VERSION "HNNBNNNYNNNNNNNNNNNNNNNNNNNNNNNNNNNNNNNNNN/4/%%%/4/'%**4NNN///"

NS_ :

BS_ :

BU_:  Airbag BAP_Tester ICAS1_Gateway ICAS1_KommunikationsServer LE1 LE2 Motor_BEV Schaltbetaetigung

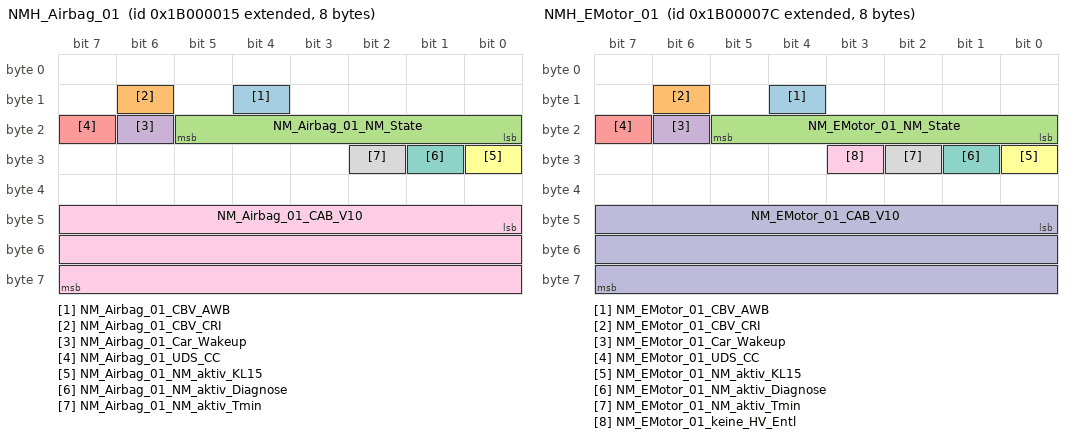
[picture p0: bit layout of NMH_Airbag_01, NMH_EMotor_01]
BO_ 2600468501 NMH_Airbag_01: 8 Airbag
 SG_ NM_Airbag_01_CBV_AWB  : 12|1@1+ (1.000000,0.000000) [0.000000|1.000000] "" ICAS1_Gateway
 SG_ NM_Airbag_01_CBV_CRI  : 14|1@1+ (1.000000,0.000000) [0.000000|1.000000] "" ICAS1_Gateway
 SG_ NM_Airbag_01_NM_State  : 16|6@1+ (1.000000,0.000000) [0.000000|63.000000] "" LE1 LE2 Motor_BEV Schaltbetaetigung
 SG_ NM_Airbag_01_Car_Wakeup  : 22|1@1+ (1.000000,0.000000) [0.000000|1.000000] "" ICAS1_Gateway
 SG_ NM_Airbag_01_UDS_CC  : 23|1@1+ (1.000000,0.000000) [0.000000|1.000000] "" Vector__XXX
 SG_ NM_Airbag_01_NM_aktiv_KL15  : 24|1@1+ (1.000000,0.000000) [0.000000|1.000000] "" Vector__XXX
 SG_ NM_Airbag_01_NM_aktiv_Diagnose  : 25|1@1+ (1.000000,0.000000) [0.000000|1.000000] "" Vector__XXX
 SG_ NM_Airbag_01_NM_aktiv_Tmin  : 26|1@1+ (1.000000,0.000000) [0.000000|1.000000] "" Vector__XXX
 SG_ NM_Airbag_01_CAB_V10  : 40|24@1+ (1.000000,0.000000) [0.000000|16777215.000000] "" ICAS1_Gateway

BO_ 2600468604 NMH_EMotor_01: 8 LE1
 SG_ NM_EMotor_01_CBV_AWB  : 12|1@1+ (1.000000,0.000000) [0.000000|1.000000] "" ICAS1_Gateway
 SG_ NM_EMotor_01_CBV_CRI  : 14|1@1+ (1.000000,0.000000) [0.000000|1.000000] "" ICAS1_Gateway
 SG_ NM_EMotor_01_NM_State  : 16|6@1+ (1.000000,0.000000) [0.000000|63.000000] "" Airbag LE2 Motor_BEV Schaltbetaetigung
 SG_ NM_EMotor_01_Car_Wakeup  : 22|1@1+ (1.000000,0.000000) [0.000000|1.000000] "" ICAS1_Gateway
 SG_ NM_EMotor_01_UDS_CC  : 23|1@1+ (1.000000,0.000000) [0.000000|1.000000] "" Vector__XXX
 SG_ NM_EMotor_01_NM_aktiv_KL15  : 24|1@1+ (1.000000,0.000000) [0.000000|1.000000] "" Vector__XXX
 SG_ NM_EMotor_01_NM_aktiv_Diagnose  : 25|1@1+ (1.000000,0.000000) [0.000000|1.000000] "" Vector__XXX
 SG_ NM_EMotor_01_NM_aktiv_Tmin  : 26|1@1+ (1.000000,0.000000) [0.000000|1.000000] "" Vector__XXX
 SG_ NM_EMotor_01_keine_HV_Entl  : 27|1@1+ (1.000000,0.000000) [0.000000|1.000000] "" Vector__XXX
 SG_ NM_EMotor_01_CAB_V10  : 40|24@1+ (1.000000,0.000000) [0.000000|16777215.000000] "" ICAS1_Gateway

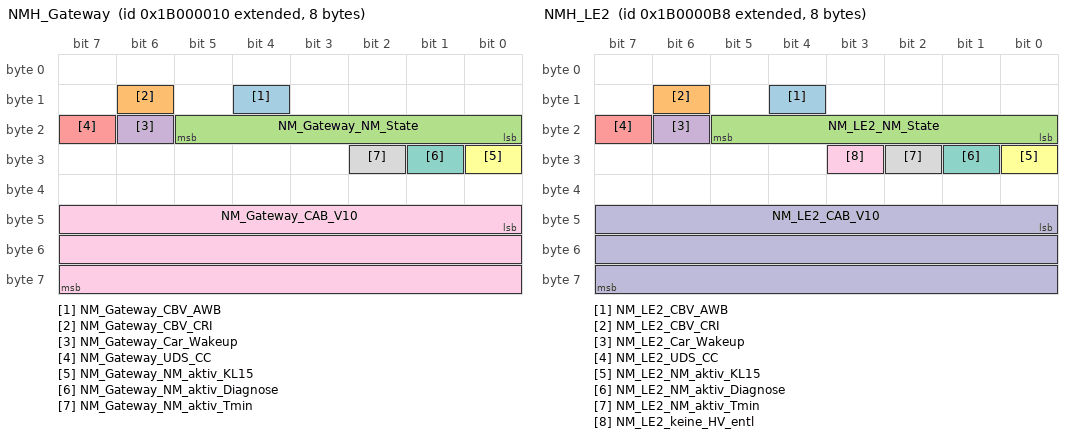
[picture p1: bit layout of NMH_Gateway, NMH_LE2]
BO_ 2600468496 NMH_Gateway: 8 ICAS1_Gateway
 SG_ NM_Gateway_CBV_AWB  : 12|1@1+ (1.000000,0.000000) [0.000000|1.000000] "" Vector__XXX
 SG_ NM_Gateway_CBV_CRI  : 14|1@1+ (1.000000,0.000000) [0.000000|1.000000] "" Vector__XXX
 SG_ NM_Gateway_NM_State  : 16|6@1+ (1.000000,0.000000) [0.000000|63.000000] "" Airbag LE1 LE2 Motor_BEV Schaltbetaetigung
 SG_ NM_Gateway_Car_Wakeup  : 22|1@1+ (1.000000,0.000000) [0.000000|1.000000] "" Vector__XXX
 SG_ NM_Gateway_UDS_CC  : 23|1@1+ (1.000000,0.000000) [0.000000|1.000000] "" Vector__XXX
 SG_ NM_Gateway_NM_aktiv_KL15  : 24|1@1+ (1.000000,0.000000) [0.000000|1.000000] "" Vector__XXX
 SG_ NM_Gateway_NM_aktiv_Diagnose  : 25|1@1+ (1.000000,0.000000) [0.000000|1.000000] "" Vector__XXX
 SG_ NM_Gateway_NM_aktiv_Tmin  : 26|1@1+ (1.000000,0.000000) [0.000000|1.000000] "" Vector__XXX
 SG_ NM_Gateway_CAB_V10  : 40|24@1+ (1.000000,0.000000) [0.000000|16777215.000000] "" Vector__XXX

BO_ 2600468664 NMH_LE2: 8 LE2
 SG_ NM_LE2_CBV_AWB  : 12|1@1+ (1.000000,0.000000) [0.000000|1.000000] "" ICAS1_Gateway
 SG_ NM_LE2_CBV_CRI  : 14|1@1+ (1.000000,0.000000) [0.000000|1.000000] "" ICAS1_Gateway
 SG_ NM_LE2_NM_State  : 16|6@1+ (1.000000,0.000000) [0.000000|63.000000] "" Airbag LE1 Motor_BEV Schaltbetaetigung
 SG_ NM_LE2_Car_Wakeup  : 22|1@1+ (1.000000,0.000000) [0.000000|1.000000] "" ICAS1_Gateway
 SG_ NM_LE2_UDS_CC  : 23|1@1+ (1.000000,0.000000) [0.000000|1.000000] "" Vector__XXX
 SG_ NM_LE2_NM_aktiv_KL15  : 24|1@1+ (1.000000,0.000000) [0.000000|1.000000] "" Vector__XXX
 SG_ NM_LE2_NM_aktiv_Diagnose  : 25|1@1+ (1.000000,0.000000) [0.000000|1.000000] "" Vector__XXX
 SG_ NM_LE2_NM_aktiv_Tmin  : 26|1@1+ (1.000000,0.000000) [0.000000|1.000000] "" Vector__XXX
 SG_ NM_LE2_keine_HV_entl  : 27|1@1+ (1.000000,0.000000) [0.000000|1.000000] "" Vector__XXX
 SG_ NM_LE2_CAB_V10  : 40|24@1+ (1.000000,0.000000) [0.000000|16777215.000000] "" ICAS1_Gateway

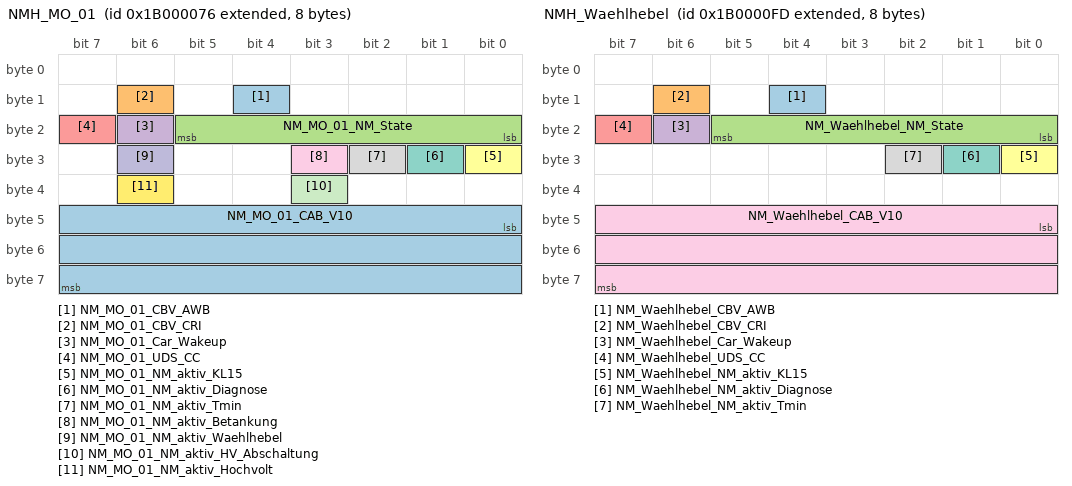
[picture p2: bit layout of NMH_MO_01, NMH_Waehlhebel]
BO_ 2600468598 NMH_MO_01: 8 Motor_BEV
 SG_ NM_MO_01_CBV_AWB  : 12|1@1+ (1.000000,0.000000) [0.000000|1.000000] "" ICAS1_Gateway
 SG_ NM_MO_01_CBV_CRI  : 14|1@1+ (1.000000,0.000000) [0.000000|1.000000] "" ICAS1_Gateway
 SG_ NM_MO_01_NM_State  : 16|6@1+ (1.000000,0.000000) [0.000000|63.000000] "" Airbag LE1 LE2 Schaltbetaetigung
 SG_ NM_MO_01_Car_Wakeup  : 22|1@1+ (1.000000,0.000000) [0.000000|1.000000] "" ICAS1_Gateway
 SG_ NM_MO_01_UDS_CC  : 23|1@1+ (1.000000,0.000000) [0.000000|1.000000] "" Vector__XXX
 SG_ NM_MO_01_NM_aktiv_KL15  : 24|1@1+ (1.000000,0.000000) [0.000000|1.000000] "" Vector__XXX
 SG_ NM_MO_01_NM_aktiv_Diagnose  : 25|1@1+ (1.000000,0.000000) [0.000000|1.000000] "" Vector__XXX
 SG_ NM_MO_01_NM_aktiv_Tmin  : 26|1@1+ (1.000000,0.000000) [0.000000|1.000000] "" Vector__XXX
 SG_ NM_MO_01_NM_aktiv_Betankung  : 27|1@1+ (1.000000,0.000000) [0.000000|1.000000] "" Vector__XXX
 SG_ NM_MO_01_NM_aktiv_Waehlhebel  : 30|1@1+ (1.000000,0.000000) [0.000000|1.000000] "" Vector__XXX
 SG_ NM_MO_01_NM_aktiv_HV_Abschaltung  : 35|1@1+ (1.000000,0.000000) [0.000000|1.000000] "" Vector__XXX
 SG_ NM_MO_01_NM_aktiv_Hochvolt  : 38|1@1+ (1.000000,0.000000) [0.000000|1.000000] "" Vector__XXX
 SG_ NM_MO_01_CAB_V10  : 40|24@1+ (1.000000,0.000000) [0.000000|16777215.000000] "" ICAS1_Gateway

BO_ 2600468733 NMH_Waehlhebel: 8 Schaltbetaetigung
 SG_ NM_Waehlhebel_CBV_AWB  : 12|1@1+ (1.000000,0.000000) [0.000000|1.000000] "" ICAS1_Gateway
 SG_ NM_Waehlhebel_CBV_CRI  : 14|1@1+ (1.000000,0.000000) [0.000000|1.000000] "" ICAS1_Gateway
 SG_ NM_Waehlhebel_NM_State  : 16|6@1+ (1.000000,0.000000) [0.000000|63.000000] "" Airbag LE1 LE2 Motor_BEV
 SG_ NM_Waehlhebel_Car_Wakeup  : 22|1@1+ (1.000000,0.000000) [0.000000|1.000000] "" ICAS1_Gateway
 SG_ NM_Waehlhebel_UDS_CC  : 23|1@1+ (1.000000,0.000000) [0.000000|1.000000] "" Vector__XXX
 SG_ NM_Waehlhebel_NM_aktiv_KL15  : 24|1@1+ (1.000000,0.000000) [0.000000|1.000000] "" Vector__XXX
 SG_ NM_Waehlhebel_NM_aktiv_Diagnose  : 25|1@1+ (1.000000,0.000000) [0.000000|1.000000] "" Vector__XXX
 SG_ NM_Waehlhebel_NM_aktiv_Tmin  : 26|1@1+ (1.000000,0.000000) [0.000000|1.000000] "" Vector__XXX
 SG_ NM_Waehlhebel_CAB_V10  : 40|24@1+ (1.000000,0.000000) [0.000000|16777215.000000] "" ICAS1_Gateway

BO_ 2621440533 OBDC_Airbag_01_Req_FD: 64 ICAS1_Gateway
 SG_ OBDC_Airbag_01_Req_FD_Data  : 0|512@1+ (1.000000,0.000000) [0.000000|13407807929942597099574024998205846127479365820592393377723561443721764030073546976801874298166903427690031858186486050853753882811946569946433649006084096.000000] "" Airbag

BO_ 2621571605 OBDC_Airbag_01_Resp_FD: 64 Airbag
 SG_ OBDC_Airbag_01_Resp_FD_Data  : 0|512@1+ (1.000000,0.000000) [0.000000|13407807929942597099574024998205846127479365820592393377723561443721764030073546976801874298166903427690031858186486050853753882811946569946433649006084096.000000] "" ICAS1_Gateway

BO_ 2621440636 OBDC_EMotor_01_Req_FD: 64 ICAS1_Gateway
 SG_ OBDC_EMotor_01_Req_FD_Data  : 0|512@1+ (1.000000,0.000000) [0.000000|13407807929942597099574024998205846127479365820592393377723561443721764030073546976801874298166903427690031858186486050853753882811946569946433649006084096.000000] "" LE1

BO_ 2621571708 OBDC_EMotor_01_Resp_FD: 64 LE1
 SG_ OBDC_EMotor_01_Resp_FD_Data  : 0|512@1+ (1.000000,0.000000) [0.000000|13407807929942597099574024998205846127479365820592393377723561443721764030073546976801874298166903427690031858186486050853753882811946569946433649006084096.000000] "" ICAS1_Gateway

BO_ 2621440696 OBDC_EMotor_02_Req_FD: 64 ICAS1_Gateway
 SG_ OBDC_EMotor_02_Req_FD_Data  : 0|512@1+ (1.000000,0.000000) [0.000000|13407807929942597099574024998205846127479365820592393377723561443721764030073546976801874298166903427690031858186486050853753882811946569946433649006084096.000000] "" LE2

BO_ 2621571768 OBDC_EMotor_02_Resp_FD: 64 LE2
 SG_ OBDC_EMotor_02_Resp_FD_Data  : 0|512@1+ (1.000000,0.000000) [0.000000|13407807929942597099574024998205846127479365820592393377723561443721764030073546976801874298166903427690031858186486050853753882811946569946433649006084096.000000] "" ICAS1_Gateway

BO_ 2621506048 OBDC_Funktionaler_Req_All_FD: 64 ICAS1_Gateway
 SG_ OBDC_Funktion_Req_All_FD_Data  : 0|512@1+ (1.000000,0.000000) [0.000000|13407807929942597099574024998205846127479365820592393377723561443721764030073546976801874298166903427690031858186486050853753882811946569946433649006084096.000000] "" Airbag LE1 LE2 Motor_BEV

BO_ 2621440630 OBDC_MO_01_Req_FD: 64 ICAS1_Gateway
 SG_ OBDC_MO_01_Req_FD_Data  : 0|512@1+ (1.000000,0.000000) [0.000000|13407807929942597099574024998205846127479365820592393377723561443721764030073546976801874298166903427690031858186486050853753882811946569946433649006084096.000000] "" Motor_BEV

BO_ 2621571702 OBDC_MO_01_Resp_FD: 64 Motor_BEV
 SG_ OBDC_MO_01_Resp_FD_Data  : 0|512@1+ (1.000000,0.000000) [0.000000|13407807929942597099574024998205846127479365820592393377723561443721764030073546976801874298166903427690031858186486050853753882811946569946433649006084096.000000] "" ICAS1_Gateway

BO_ 2564502513 OBDx_allOBD_Req: 8 ICAS1_Gateway
 SG_ OBDx_allOBD_Req_Data  : 0|64@1+ (1.000000,0.000000) [0.000000|18446744073709551616.000000] "" LE1 LE2 Motor_BEV

BO_ 2564425457 OBDx_LE1_Req: 8 ICAS1_Gateway
 SG_ OBDx_LE1_Req_Data  : 0|64@1+ (1.000000,0.000000) [0.000000|18446744073709551616.000000] "" LE1

BO_ 2564485382 OBDx_LE1_Resp: 8 LE1
 SG_ OBDx_LE1_Resp_Data  : 0|64@1+ (1.000000,0.000000) [0.000000|18446744073709551616.000000] "" ICAS1_Gateway

BO_ 2564425713 OBDx_LE2_Req: 8 ICAS1_Gateway
 SG_ OBDx_LE2_Req_Data  : 0|64@1+ (1.000000,0.000000) [0.000000|18446744073709551616.000000] "" LE2

BO_ 2564485383 OBDx_LE2_Resp: 8 LE2
 SG_ OBDx_LE2_Resp_Data  : 0|64@1+ (1.000000,0.000000) [0.000000|18446744073709551616.000000] "" ICAS1_Gateway

BO_ 2564424177 OBDx_MO_01_Req: 8 ICAS1_Gateway
 SG_ OBDx_MO_01_Req_Data  : 0|64@1+ (1.000000,0.000000) [0.000000|18446744073709551616.000000] "" Motor_BEV

BO_ 2564485377 OBDx_MO_01_Resp: 8 Motor_BEV
 SG_ OBDx_MO_01_Resp_Data  : 0|64@1+ (1.000000,0.000000) [0.000000|18446744073709551616.000000] "" ICAS1_Gateway

BO_ 627 OCC_01: 24 ICAS1_Gateway
 SG_ OCC_01_CRC  : 0|8@1+ (1.000000,0.000000) [0.000000|255.000000] "" Vector__XXX
 SG_ OCC_01_BZ  : 8|4@1+ (1.000000,0.000000) [0.000000|15.000000] "" Vector__XXX
 SG_ OCC_Stecker_Status  : 12|2@1+ (1.000000,0.000000) [0.000000|3.000000] "" Vector__XXX
 SG_ OCC_Status_Spgfreiheit  : 14|2@1+ (1.000000,0.000000) [0.000000|3.000000] "" Motor_BEV
 SG_ OCC_DC_IstStrom  : 16|11@1+ (0.100000,0.000000) [0.000000|204.500000] "Unit_Amper" Vector__XXX
 SG_ OCC_CC_Latchstatus_DC_GBT  : 27|3@1+ (1.000000,0.000000) [0.000000|7.000000] "" Vector__XXX
 SG_ OCC_Status_EoHVL  : 30|2@1+ (1.000000,0.000000) [0.000000|3.000000] "" Motor_BEV
 SG_ OCC_I_istAC_Netz_L1  : 32|9@1+ (0.100000,0.000000) [0.000000|50.800000] "Unit_Amper" Vector__XXX
 SG_ OCC_PP_Latchstatus_A  : 41|3@1+ (1.000000,0.000000) [0.000000|7.000000] "" Vector__XXX
 SG_ OCC_PP_Latchstatus_B  : 44|3@1+ (1.000000,0.000000) [0.000000|7.000000] "" Vector__XXX
 SG_ OCC_I_istAC_Netz_L2  : 47|9@1+ (0.100000,0.000000) [0.000000|50.800000] "Unit_Amper" Vector__XXX
 SG_ OCC_I_istAC_Netz_L3  : 56|9@1+ (0.100000,0.000000) [0.000000|50.800000] "Unit_Amper" Vector__XXX
 SG_ OCC_IstModus  : 65|3@1+ (1.000000,0.000000) [0.000000|7.000000] "" Motor_BEV
 SG_ OCC_CP_Status_A  : 68|2@1+ (1.000000,0.000000) [0.000000|3.000000] "" Vector__XXX
 SG_ OCC_CP_Status_B  : 70|2@1+ (1.000000,0.000000) [0.000000|3.000000] "" Vector__XXX
 SG_ OCC_IstSpannung_HV  : 72|10@1+ (1.000000,0.000000) [0.000000|1021.000000] "Unit_Volt" Vector__XXX
 SG_ OCC_PP_Status_A  : 82|2@1+ (1.000000,0.000000) [0.000000|3.000000] "" Vector__XXX
 SG_ OCC_PP_Status_B  : 84|2@1+ (1.000000,0.000000) [0.000000|3.000000] "" Vector__XXX
 SG_ OCC_CC_Status_DC_GBT  : 86|2@1+ (1.000000,0.000000) [0.000000|3.000000] "" Vector__XXX
 SG_ OCC_CC_Fehlerstatus_DC_GBT  : 88|4@1+ (1.000000,0.000000) [0.000000|15.000000] "" Vector__XXX
 SG_ OCC_Temp_Sensor_Fehlerstatus_DC  : 92|4@1+ (1.000000,0.000000) [0.000000|15.000000] "" Vector__XXX
 SG_ OCC_Temp_Sensor_Fehlerstatus_AC  : 96|3@1+ (1.000000,0.000000) [0.000000|7.000000] "" Vector__XXX
 SG_ OCC_Temp_Sensor_Status  : 99|3@1+ (1.000000,0.000000) [0.000000|7.000000] "" Vector__XXX

BO_ 2463978709 OCC_02: 32 ICAS1_Gateway
 SG_ OCC_CP_Tastgrad_A  : 12|10@1+ (0.100000,0.000000) [0.000000|100.000000] "Unit_PerCent" Vector__XXX
 SG_ OCC_CP_Tastgrad_B  : 22|10@1+ (0.100000,0.000000) [0.000000|100.000000] "Unit_PerCent" Vector__XXX
 SG_ OCC_CP_Frequenz_A  : 32|8@1+ (1.000000,880.000000) [880.000000|1132.000000] "Unit_Hertz" Vector__XXX
 SG_ OCC_CP_Frequenz_B  : 40|8@1+ (1.000000,880.000000) [880.000000|1132.000000] "Unit_Hertz" Vector__XXX
 SG_ OCC_CP_Spannung_A  : 48|9@1+ (0.100000,-25.000000) [-25.000000|25.900000] "Unit_Volt" Vector__XXX
 SG_ OCC_CP_Spannung_B  : 57|9@1+ (0.100000,-25.000000) [-25.000000|25.900000] "Unit_Volt" Vector__XXX
 SG_ OCC_CP_Fehlerstatus_A  : 66|3@1+ (1.000000,0.000000) [0.000000|7.000000] "" Vector__XXX
 SG_ OCC_CP_Fehlerstatus_B  : 69|3@1+ (1.000000,0.000000) [0.000000|7.000000] "" Vector__XXX
 SG_ OCC_Temp_Ladedose_A_AC  : 72|8@1+ (1.000000,-40.000000) [-40.000000|213.000000] "Unit_DegreCelsi" Vector__XXX
 SG_ OCC_Temp_Ladedose_A_DC_minus  : 80|8@1+ (1.000000,-40.000000) [-40.000000|213.000000] "Unit_DegreCelsi" Vector__XXX
 SG_ OCC_Temp_Ladedose_A_DC_plus  : 88|8@1+ (1.000000,-40.000000) [-40.000000|213.000000] "Unit_DegreCelsi" Vector__XXX
 SG_ OCC_U_istAC_Netz_L1  : 96|9@1+ (1.000000,0.000000) [0.000000|509.000000] "Unit_Volt" Vector__XXX
 SG_ OCC_U_istAC_Netz_L2  : 105|9@1+ (1.000000,0.000000) [0.000000|509.000000] "Unit_Volt" Vector__XXX
 SG_ OCC_U_istAC_Netz_L3  : 114|9@1+ (1.000000,0.000000) [0.000000|508.000000] "Unit_Volt" Vector__XXX
 SG_ OCC_StatusVerEntriegelungAktor_A  : 123|3@1+ (1.000000,0.000000) [0.000000|7.000000] "" Vector__XXX
 SG_ OCC_SteckerEntriegelung_Verbot_A  : 126|2@1+ (1.000000,0.000000) [0.000000|3.000000] "" Vector__XXX
 SG_ OCC_StatusVerEntriegelungAktor_B  : 128|3@1+ (1.000000,0.000000) [0.000000|7.000000] "" Vector__XXX
 SG_ OCC_SteckerEntriegelung_Verbot_B  : 131|2@1+ (1.000000,0.000000) [0.000000|3.000000] "" Vector__XXX
 SG_ OCC_Verriegelung_Status_A  : 133|3@1+ (1.000000,0.000000) [0.000000|7.000000] "" Vector__XXX
 SG_ OCC_Verriegelung_Status_B  : 136|3@1+ (1.000000,0.000000) [0.000000|7.000000] "" Vector__XXX
 SG_ OCC_RtmWarnLadeKommunikation  : 139|3@1+ (1.000000,0.000000) [0.000000|7.000000] "" Vector__XXX
 SG_ OCC_Ist_Wirkungsgrad  : 145|7@1+ (1.000000,0.000000) [0.000000|100.000000] "Unit_PerCent" Vector__XXX
 SG_ OCC_PP_Max_Strom_A  : 152|4@1+ (1.000000,0.000000) [0.000000|15.000000] "" Vector__XXX
 SG_ OCC_PP_Max_Strom_B  : 156|4@1+ (1.000000,0.000000) [0.000000|15.000000] "" Vector__XXX
 SG_ OCC_DC_MaxStrom  : 160|11@1+ (0.100000,0.000000) [0.000000|204.500000] "Unit_Amper" Vector__XXX
 SG_ OCC_Derating_Temperatur  : 171|1@1+ (1.000000,0.000000) [0.000000|1.000000] "" Vector__XXX
 SG_ OCC_Fehlerzustand  : 172|1@1+ (1.000000,0.000000) [0.000000|1.000000] "" Vector__XXX
 SG_ OCC_Ladest_Entriegelungs_Verbot  : 173|3@1+ (1.000000,0.000000) [0.000000|7.000000] "" Vector__XXX
 SG_ OCC_Netzfrequenz_EVU  : 176|9@1+ (0.100000,40.000000) [40.000000|80.000000] "Unit_Hertz" Vector__XXX
 SG_ OCC_Warnzustand  : 185|1@1+ (1.000000,0.000000) [0.000000|1.000000] "" Vector__XXX
 SG_ OCC_Kuehltemperatur  : 192|8@1+ (1.000000,-40.000000) [-40.000000|213.000000] "Unit_DegreCelsi" Motor_BEV
 SG_ OCC_PP_Fehlerstatus_A  : 200|4@1+ (1.000000,0.000000) [0.000000|15.000000] "" Vector__XXX
 SG_ OCC_PP_Fehlerstatus_B  : 204|4@1+ (1.000000,0.000000) [0.000000|15.000000] "" Vector__XXX

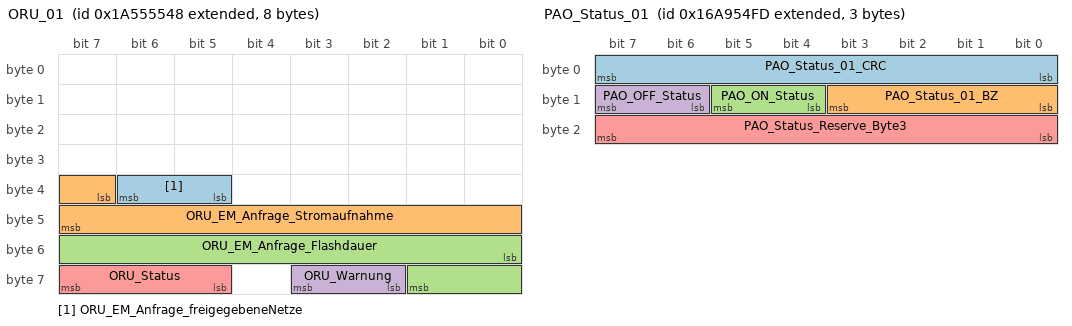
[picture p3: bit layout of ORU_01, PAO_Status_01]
BO_ 2589283656 ORU_01: 8 ICAS1_Gateway
 SG_ ORU_EM_Anfrage_freigegebeneNetze  : 37|2@1+ (1.000000,0.000000) [0.000000|3.000000] "" Vector__XXX
 SG_ ORU_EM_Anfrage_Stromaufnahme  : 39|9@1+ (0.100000,0.000000) [0.000000|51.100000] "Unit_Amper" Vector__XXX
 SG_ ORU_EM_Anfrage_Flashdauer  : 48|10@1+ (10.000000,0.000000) [0.000000|10230.000000] "Unit_Secon" Vector__XXX
 SG_ ORU_Warnung  : 58|2@1+ (1.000000,0.000000) [0.000000|3.000000] "" Vector__XXX
 SG_ ORU_Status  : 61|3@1+ (1.000000,0.000000) [0.000000|7.000000] "" Airbag LE1 LE2 Motor_BEV

BO_ 2527679741 PAO_Status_01: 3 ICAS1_Gateway
 SG_ PAO_Status_01_CRC  : 0|8@1+ (1.000000,0.000000) [0.000000|255.000000] "" Airbag
 SG_ PAO_Status_01_BZ  : 8|4@1+ (1.000000,0.000000) [0.000000|15.000000] "" Airbag
 SG_ PAO_ON_Status  : 12|2@1+ (1.000000,0.000000) [0.000000|3.000000] "" Airbag
 SG_ PAO_OFF_Status  : 14|2@1+ (1.000000,0.000000) [0.000000|3.000000] "" Airbag
 SG_ PAO_Status_Reserve_Byte3  : 16|8@1+ (1.000000,0.000000) [0.000000|255.000000] "" Vector__XXX

BO_ 518 Parken_01: 24 ICAS1_Gateway
 SG_ Parken_BKD_Anf  : 12|4@1+ (0.100000,0.000000) [0.000000|1.300000] "Unit_Secon" Vector__XXX
 SG_ Parken_Verz_Anf  : 16|7@1+ (0.100000,-12.600000) [-12.600000|-0.100000] "Unit_MeterPerSeconSquar" Vector__XXX
 SG_ Parken_Prefill_Anf  : 23|1@1+ (1.000000,0.000000) [0.000000|1.000000] "" Vector__XXX
 SG_ Parken_Warnruck_Anf  : 24|2@1+ (1.000000,0.000000) [0.000000|3.000000] "" Vector__XXX
 SG_ Parken_Verz_Anf_ASIL  : 26|2@1+ (1.000000,0.000000) [0.000000|3.000000] "" Vector__XXX
 SG_ Parken_Warnruckeln_Anf  : 28|2@1+ (1.000000,0.000000) [0.000000|3.000000] "" Vector__XXX
 SG_ Parken_beibehalten  : 30|2@1+ (1.000000,0.000000) [0.000000|3.000000] "" Vector__XXX
 SG_ Parken_Anforderung_HMS  : 32|3@1+ (1.000000,0.000000) [0.000000|7.000000] "" Vector__XXX
 SG_ Parken_Notstopp_Anf  : 40|2@1+ (1.000000,0.000000) [0.000000|3.000000] "" Vector__XXX
 SG_ Parken_Anhalteweg_Anf  : 42|10@1+ (0.010000,0.000000) [0.000000|10.210000] "Unit_Meter" Vector__XXX
 SG_ Parken_aktives_System  : 52|4@1+ (1.000000,0.000000) [0.000000|15.000000] "" Motor_BEV
 SG_ Parken_max_Beschleunigung  : 56|7@1+ (0.100000,-6.000000) [-5.900000|6.100000] "Unit_MeterPerSeconSquar" Motor_BEV
 SG_ Parken_Blinker_li_Anf  : 63|1@1+ (1.000000,0.000000) [0.000000|1.000000] "" Vector__XXX
 SG_ Parken_QFK_KruemmSoll  : 64|15@1+ (0.000007,0.000000) [0.000000|0.219539] "Unit_MeterInver" Vector__XXX
 SG_ Parken_QFK_KruemmSoll_VZ  : 79|1@1+ (1.000000,0.000000) [0.000000|1.000000] "" Vector__XXX
 SG_ Parken_QFK_Spuerb  : 80|8@1+ (0.400000,0.000000) [0.000000|100.000000] "Unit_PerCent" Vector__XXX
 SG_ Parken_QFK_AnfStat  : 88|4@1+ (1.000000,0.000000) [0.000000|15.000000] "" Vector__XXX
 SG_ Parken_QFK_Signal1  : 92|10@1+ (1.000000,0.000000) [0.000000|1023.000000] "" Vector__XXX
 SG_ Parken_QFK_Art1  : 102|3@1+ (1.000000,0.000000) [0.000000|7.000000] "" Vector__XXX
 SG_ Parken_QFK_Art2  : 105|3@1+ (1.000000,0.000000) [0.000000|7.000000] "" Vector__XXX
 SG_ Parken_QFK_Signal2  : 108|10@1+ (1.000000,0.000000) [0.000000|1023.000000] "" Vector__XXX
 SG_ Parken_Sollbeschleunigung  : 118|9@1+ (0.010000,-4.110000) [-4.100000|1.000000] "Unit_MeterPerSeconSquar" Motor_BEV
 SG_ Parken_Blinker_re_Anf  : 127|1@1+ (1.000000,0.000000) [0.000000|1.000000] "" Vector__XXX
 SG_ Parken_Status_IPA_TSK  : 128|4@1+ (1.000000,0.000000) [0.000000|15.000000] "" Motor_BEV
 SG_ Parken_erhoehtes_Moment  : 132|4@1+ (1.000000,0.000000) [0.000000|15.000000] "" Motor_BEV
 SG_ Parken_max_Geschwindigkeit  : 136|8@1+ (0.100000,0.000000) [0.100000|25.000000] "Unit_KiloMeterPerHour" Motor_BEV
 SG_ Parken_Soll_Anhalteweg_Anf  : 144|10@1+ (0.010000,0.000000) [0.000000|10.210000] "Unit_Meter" Vector__XXX
 SG_ Parken_Fahrstufenwunsch  : 154|3@1+ (1.000000,0.000000) [0.000000|7.000000] "" Motor_BEV
 SG_ IPA_TPA_Remote  : 157|2@1+ (1.000000,0.000000) [0.000000|3.000000] "" Vector__XXX
 SG_ IPA_TPA_Remote_Anf  : 159|1@1+ (1.000000,0.000000) [0.000000|1.000000] "" Vector__XXX
 SG_ IPA_TPA_Fehler  : 160|4@1+ (1.000000,0.000000) [0.000000|15.000000] "" Vector__XXX
 SG_ IPA_TPA_Abbruch  : 164|4@1+ (1.000000,0.000000) [0.000000|15.000000] "" Vector__XXX
 SG_ IPA_TPA_Status  : 168|4@1+ (1.000000,0.000000) [0.000000|15.000000] "" Vector__XXX

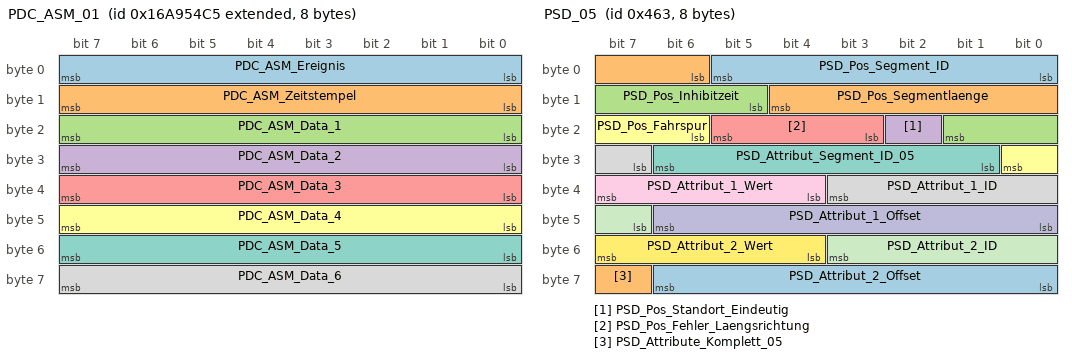
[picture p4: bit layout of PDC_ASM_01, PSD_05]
BO_ 2527679685 PDC_ASM_01: 8 ICAS1_Gateway
 SG_ PDC_ASM_Ereignis  : 0|8@1+ (1.000000,0.000000) [1.000000|254.000000] "" Airbag
 SG_ PDC_ASM_Zeitstempel  : 8|8@1+ (0.080000,0.000000) [0.000000|20.320000] "Unit_Secon" Airbag
 SG_ PDC_ASM_Data_1  : 16|8@1+ (1.000000,0.000000) [0.000000|255.000000] "" Airbag
 SG_ PDC_ASM_Data_2  : 24|8@1+ (1.000000,0.000000) [0.000000|255.000000] "" Airbag
 SG_ PDC_ASM_Data_3  : 32|8@1+ (1.000000,0.000000) [0.000000|255.000000] "" Airbag
 SG_ PDC_ASM_Data_4  : 40|8@1+ (1.000000,0.000000) [0.000000|255.000000] "" Airbag
 SG_ PDC_ASM_Data_5  : 48|8@1+ (1.000000,0.000000) [0.000000|255.000000] "" Airbag
 SG_ PDC_ASM_Data_6  : 56|8@1+ (1.000000,0.000000) [0.000000|255.000000] "" Airbag

BO_ 319 PreCrash_02: 8 Airbag
 SG_ PreCrash_Charisma_FahrPr  : 12|4@1+ (1.000000,0.000000) [0.000000|15.000000] "" ICAS1_Gateway
 SG_ PreCrash_Charisma_Status  : 16|2@1+ (1.000000,0.000000) [0.000000|3.000000] "" ICAS1_Gateway
 SG_ PreCrash_Schiebedach_schliessen  : 18|1@1+ (1.000000,0.000000) [0.000000|1.000000] "" ICAS1_Gateway
 SG_ PreCrash_Fenster_schliessen  : 19|1@1+ (1.000000,0.000000) [0.000000|1.000000] "" ICAS1_Gateway
 SG_ PreCrash_Blinken  : 20|3@1+ (1.000000,0.000000) [0.000000|7.000000] "" ICAS1_Gateway
 SG_ SC_PreSense_FCWP  : 23|1@1+ (1.000000,0.000000) [0.000000|1.000000] "" ICAS1_Gateway
 SG_ PreCrash_Tueren_Verriegeln  : 24|1@1+ (1.000000,0.000000) [0.000000|1.000000] "" ICAS1_Gateway
 SG_ PreCrash_FS_Laengsverstellung  : 25|1@1+ (1.000000,0.000000) [0.000000|1.000000] "" ICAS1_Gateway
 SG_ PreCrash_Anforderung_AFR  : 26|3@1+ (1.000000,0.000000) [0.000000|7.000000] "" ICAS1_Gateway
 SG_ SC_PreCrash_LED  : 29|2@1+ (1.000000,0.000000) [0.000000|3.000000] "" ICAS1_Gateway
 SG_ PreCrash_FS_Pneumatik_ansteuern  : 31|1@1+ (1.000000,0.000000) [0.000000|1.000000] "" ICAS1_Gateway
 SG_ PreCrash_BFS_Pneumatik_ansteuern  : 32|1@1+ (1.000000,0.000000) [0.000000|1.000000] "" ICAS1_Gateway
 SG_ PreCrash_Fo_Pneumatik_ansteuern  : 33|1@1+ (1.000000,0.000000) [0.000000|1.000000] "" ICAS1_Gateway
 SG_ PreCrash_FS_Sitzlehne_verfahren  : 34|3@1+ (1.000000,0.000000) [0.000000|7.000000] "" ICAS1_Gateway
 SG_ PreCrash_BFS_Sitzlehne_verfahren  : 37|3@1+ (1.000000,0.000000) [0.000000|7.000000] "" ICAS1_Gateway
 SG_ PreCrash_Fo_Sitzlehne_verfahren  : 40|3@1+ (1.000000,0.000000) [0.000000|7.000000] "" ICAS1_Gateway
 SG_ PreCrash_FS_KSV_verfahren  : 43|4@1+ (1.000000,0.000000) [0.000000|15.000000] "" ICAS1_Gateway
 SG_ PreCrash_BFS_KSV_verfahren  : 47|4@1+ (1.000000,0.000000) [0.000000|15.000000] "" ICAS1_Gateway
 SG_ PreCrash_Fo_KSV_verfahren  : 51|4@1+ (1.000000,0.000000) [0.000000|15.000000] "" ICAS1_Gateway
 SG_ PreCrash_BFS_Laengsverstellung  : 55|1@1+ (1.000000,0.000000) [0.000000|1.000000] "" ICAS1_Gateway
 SG_ SC_PreCrash_Warnung  : 56|4@1+ (1.000000,0.000000) [0.000000|15.000000] "" ICAS1_Gateway ICAS1_KommunikationsServer
 SG_ SC_PreCrash_Texte  : 60|4@1+ (1.000000,0.000000) [0.000000|15.000000] "" ICAS1_Gateway ICAS1_KommunikationsServer

BO_ 1122 PSD_04: 8 ICAS1_Gateway
 SG_ PSD_Segment_ID  : 0|6@1+ (1.000000,0.000000) [2.000000|63.000000] "" Motor_BEV
 SG_ PSD_Vorgaenger_Segment_ID  : 6|6@1+ (1.000000,0.000000) [2.000000|63.000000] "" Motor_BEV
 SG_ PSD_Segmentlaenge  : 12|7@1+ (2.000000,0.000000) [0.000000|254.000000] "Unit_Meter" Motor_BEV
 SG_ PSD_Strassenkategorie  : 19|3@1+ (1.000000,0.000000) [0.000000|7.000000] "" Motor_BEV
 SG_ PSD_Endkruemmung  : 22|8@1+ (1.000000,0.000000) [0.000000|254.000000] "Unit_None" Motor_BEV
 SG_ PSD_Endkruemmung_Vorz  : 30|1@1+ (1.000000,0.000000) [0.000000|1.000000] "" Motor_BEV
 SG_ PSD_Idenditaets_ID  : 31|6@1+ (1.000000,0.000000) [2.000000|63.000000] "" Vector__XXX
 SG_ PSD_ADAS_Qualitaet  : 37|1@1+ (1.000000,0.000000) [0.000000|1.000000] "" Motor_BEV
 SG_ PSD_wahrscheinlichster_Pfad  : 38|1@1+ (1.000000,0.000000) [0.000000|1.000000] "" Motor_BEV
 SG_ PSD_Geradester_Pfad  : 39|1@1+ (1.000000,0.000000) [0.000000|1.000000] "" Motor_BEV
 SG_ PSD_Fahrspuren_Anzahl  : 40|3@1+ (1.000000,0.000000) [0.000000|7.000000] "" Motor_BEV
 SG_ PSD_Bebauung  : 43|1@1+ (1.000000,0.000000) [0.000000|1.000000] "" Motor_BEV
 SG_ PSD_Segment_Komplett  : 44|1@1+ (1.000000,0.000000) [0.000000|1.000000] "" Motor_BEV
 SG_ PSD_Rampe  : 45|2@1+ (1.000000,0.000000) [0.000000|3.000000] "" Motor_BEV
 SG_ PSD_Anfangskruemmung  : 47|8@1+ (1.000000,0.000000) [0.000000|254.000000] "" Motor_BEV
 SG_ PSD_Anfangskruemmung_Vorz  : 55|1@1+ (1.000000,0.000000) [0.000000|1.000000] "" Motor_BEV
 SG_ PSD_Abzweigerichtung  : 56|1@1+ (1.000000,0.000000) [0.000000|1.000000] "" Motor_BEV
 SG_ PSD_Abzweigewinkel  : 57|7@1+ (1.417323,0.000000) [0.000000|180.000021] "" Motor_BEV

BO_ 1123 PSD_05: 8 ICAS1_Gateway
 SG_ PSD_Pos_Segment_ID  : 0|6@1+ (1.000000,0.000000) [2.000000|63.000000] "" Motor_BEV
 SG_ PSD_Pos_Segmentlaenge  : 6|7@1+ (2.000000,0.000000) [0.000000|254.000000] "Unit_Meter" Motor_BEV
 SG_ PSD_Pos_Inhibitzeit  : 13|5@1+ (10.000000,0.000000) [0.000000|310.000000] "Unit_MilliSecon" Motor_BEV
 SG_ PSD_Pos_Standort_Eindeutig  : 18|1@1+ (1.000000,0.000000) [0.000000|1.000000] "" Motor_BEV
 SG_ PSD_Pos_Fehler_Laengsrichtung  : 19|3@1+ (1.000000,0.000000) [0.000000|7.000000] "" Motor_BEV
 SG_ PSD_Pos_Fahrspur  : 22|3@1+ (1.000000,0.000000) [0.000000|7.000000] "" Motor_BEV
 SG_ PSD_Attribut_Segment_ID_05  : 25|6@1+ (1.000000,0.000000) [2.000000|63.000000] "" Motor_BEV
 SG_ PSD_Attribut_1_ID  : 31|5@1+ (1.000000,0.000000) [1.000000|31.000000] "" Motor_BEV
 SG_ PSD_Attribut_1_Wert  : 36|4@1+ (1.000000,0.000000) [0.000000|15.000000] "" Motor_BEV
 SG_ PSD_Attribut_1_Offset  : 40|7@1+ (2.000000,0.000000) [0.000000|254.000000] "Unit_Meter" Motor_BEV
 SG_ PSD_Attribut_2_ID  : 47|5@1+ (1.000000,0.000000) [1.000000|31.000000] "" Motor_BEV
 SG_ PSD_Attribut_2_Wert  : 52|4@1+ (1.000000,0.000000) [0.000000|15.000000] "" Motor_BEV
 SG_ PSD_Attribut_2_Offset  : 56|7@1+ (2.000000,0.000000) [0.000000|254.000000] "Unit_Meter" Motor_BEV
 SG_ PSD_Attribute_Komplett_05  : 63|1@1+ (1.000000,0.000000) [0.000000|1.000000] "" Motor_BEV

BO_ 1124 PSD_06: 8 ICAS1_Gateway
 SG_ PSD_06_Mux M : 0|3@1+ (1.000000,0.000000) [0.000000|7.000000] "" Motor_BEV
 SG_ PSD_Sys_Segment_ID m0 : 3|6@1+ (1.000000,0.000000) [2.000000|63.000000] "" Motor_BEV
 SG_ PSD_Attribut_Segment_ID m1 : 3|6@1+ (1.000000,0.000000) [2.000000|63.000000] "" Motor_BEV
 SG_ PSD_Ges_Segment_ID m2 : 3|6@1+ (1.000000,0.000000) [2.000000|63.000000] "" Motor_BEV
 SG_ PSD_Baum_Laenge_VZ m3 : 3|1@1+ (1.000000,0.000000) [0.000000|1.000000] "" Motor_BEV
 SG_ PSD_Steigung_1_Segment_ID m4 : 3|6@1+ (1.000000,0.000000) [2.000000|63.000000] "" Motor_BEV
 SG_ PSD_Baum_Laenge m3 : 4|25@1+ (0.000010,0.000000) [0.000000|180.000000] "Unit_DegreOfArc" Motor_BEV
 SG_ PSD_Sys_Laendercode m0 : 9|8@1+ (1.000000,0.000000) [0.000000|255.000000] "" Motor_BEV
 SG_ PSD_Attribut_3_ID m1 : 9|5@1+ (1.000000,0.000000) [1.000000|31.000000] "" Motor_BEV
 SG_ PSD_Ges_Offset m2 : 9|7@1+ (2.000000,0.000000) [0.000000|254.000000] "Unit_Meter" Motor_BEV
 SG_ PSD_Steigung_1_A_Steigung m4 : 9|7@1+ (0.120000,0.000000) [0.000000|15.000000] "Unit_PerCent" Motor_BEV
 SG_ PSD_Attribut_3_Offset m1 : 14|7@1+ (2.000000,0.000000) [0.000000|254.000000] "Unit_Meter" Motor_BEV
 SG_ PSD_Ges_Geschwindigkeit m2 : 16|5@1+ (1.000000,0.000000) [0.000000|31.000000] "" Motor_BEV
 SG_ PSD_Steigung_1_A_Vorz m4 : 16|1@1+ (1.000000,0.000000) [0.000000|1.000000] "" Motor_BEV
 SG_ PSD_Sys_Geschwindigkeit_Einheit m0 : 17|1@1+ (1.000000,0.000000) [0.000000|1.000000] "" Motor_BEV
 SG_ PSD_Steigung_1_A_Offset m4 : 17|7@1+ (2.000000,0.000000) [0.000000|254.000000] "Unit_Meter" Motor_BEV
 SG_ PSD_Sys_Verkehrsrichtung m0 : 18|1@1+ (1.000000,0.000000) [0.000000|1.000000] "" Motor_BEV
 SG_ PSD_Sys_Geometrieguete m0 : 19|2@1+ (1.000000,0.000000) [0.000000|3.000000] "" Motor_BEV
 SG_ PSD_Sys_Mapmatchingguete m0 : 21|2@1+ (1.000000,0.000000) [0.000000|3.000000] "" Motor_BEV
 SG_ PSD_Attribut_3_Wert m1 : 21|4@1+ (1.000000,0.000000) [0.000000|15.000000] "" Motor_BEV
 SG_ PSD_Ges_Typ m2 : 21|2@1+ (1.000000,0.000000) [0.000000|3.000000] "" Motor_BEV
 SG_ PSD_Sys_Alter_Karte m0 : 23|3@1+ (1.000000,0.000000) [0.000000|7.000000] "" Motor_BEV
 SG_ PSD_Ges_Spur_Geschw_Begrenzung m2 : 23|6@1+ (1.000000,0.000000) [0.000000|63.000000] "" Motor_BEV
 SG_ PSD_Steigung_1_B_Steigung m4 : 24|7@1+ (0.120000,0.000000) [0.000000|15.000000] "Unit_PerCent" Motor_BEV
 SG_ PSD_Attribut_4_ID m1 : 25|5@1+ (1.000000,0.000000) [1.000000|31.000000] "" Motor_BEV
 SG_ PSD_Sys_Zielfuehrung m0 : 26|1@1+ (1.000000,0.000000) [0.000000|1.000000] "" Motor_BEV
 SG_ PSD_Sys_US_State m0 : 27|6@1+ (1.000000,0.000000) [0.000000|63.000000] "" Motor_BEV
 SG_ PSD_Ges_Geschwindigkeit_Gespann m2 : 29|2@1+ (1.000000,0.000000) [0.000000|3.000000] "" Motor_BEV
 SG_ PSD_Baum_Breite_VZ m3 : 29|1@1+ (1.000000,0.000000) [0.000000|1.000000] "" Motor_BEV
 SG_ PSD_Attribut_4_Wert m1 : 30|4@1+ (1.000000,0.000000) [0.000000|15.000000] "" Motor_BEV
 SG_ PSD_Baum_Breite m3 : 30|24@1+ (0.000010,0.000000) [0.000000|90.000000] "Unit_DegreOfArc" Motor_BEV
 SG_ PSD_Ges_Geschwindigkeit_Witter m2 : 31|2@1+ (1.000000,0.000000) [0.000000|3.000000] "" Motor_BEV
 SG_ PSD_Steigung_1_B_Vorz m4 : 31|1@1+ (1.000000,0.000000) [0.000000|1.000000] "" Motor_BEV
 SG_ PSD_Steigung_1_B_Offset m4 : 32|7@1+ (2.000000,0.000000) [0.000000|254.000000] "Unit_Meter" Motor_BEV
 SG_ PSD_Sys_Quali_Geometrien m0 : 33|3@1+ (1.000000,0.000000) [0.000000|7.000000] "Unit_None" Vector__XXX
 SG_ PSD_Ges_Geschwindigkeit_Tag_Anf m2 : 33|3@1+ (1.000000,0.000000) [0.000000|7.000000] "" Motor_BEV
 SG_ PSD_Attribut_4_Offset m1 : 34|7@1+ (2.000000,0.000000) [0.000000|254.000000] "Unit_Meter" Motor_BEV
 SG_ PSD_Sys_Quali_Ortsinfo m0 : 36|2@1+ (1.000000,0.000000) [0.000000|3.000000] "Unit_None" Vector__XXX
 SG_ PSD_Ges_Geschwindigkeit_Tag_Ende m2 : 36|3@1+ (1.000000,0.000000) [0.000000|7.000000] "" Motor_BEV
 SG_ PSD_Sys_Quali_verfuegbar m0 : 38|1@1+ (1.000000,0.000000) [0.000000|1.000000] "" Vector__XXX
 SG_ PSD_Sys_Zielfuehrung_geaendert m0 : 39|1@1+ (1.000000,0.000000) [0.000000|1.000000] "" Motor_BEV
 SG_ PSD_Ges_Geschwindigkeit_Std_Anf m2 : 39|5@1+ (1.000000,0.000000) [0.000000|24.000000] "Unit_Hours" Motor_BEV
 SG_ PSD_Steigung_1_Attribute_kompl m4 : 39|1@1+ (1.000000,0.000000) [0.000000|1.000000] "" Motor_BEV
 SG_ PSD_Sys_Geometrieguete_erweitert m0 : 40|8@1+ (1.000000,0.000000) [0.000000|255.000000] "" Vector__XXX
 SG_ PSD_Steigung_2_Segment_ID m4 : 40|6@1+ (1.000000,0.000000) [2.000000|63.000000] "" Motor_BEV
 SG_ PSD_Attribut_5_ID m1 : 41|5@1+ (1.000000,0.000000) [1.000000|31.000000] "" Motor_BEV
 SG_ PSD_Ges_Geschwindigkeit_Std_Ende m2 : 44|5@1+ (1.000000,0.000000) [0.000000|24.000000] "Unit_Hours" Motor_BEV
 SG_ PSD_Attribut_5_Offset m1 : 46|7@1+ (2.000000,0.000000) [0.000000|254.000000] "Unit_Meter" Motor_BEV
 SG_ PSD_Steigung_2_Steigung m4 : 46|7@1+ (0.120000,0.000000) [0.000000|15.000000] "Unit_PerCent" Motor_BEV
 SG_ PSD_Sys_Quali_sonstige_Attribute m0 : 48|3@1+ (1.000000,0.000000) [0.000000|7.000000] "Unit_None" Vector__XXX
 SG_ PSD_Ges_Ueberholverbot m2 : 49|2@1+ (1.000000,0.000000) [0.000000|3.000000] "" Vector__XXX
 SG_ PSD_Sys_Quali_Steigungen m0 : 51|3@1+ (1.000000,0.000000) [0.000000|7.000000] "" Vector__XXX
 SG_ PSD_Ges_Wechselverkehrszeichen m2 : 51|3@1+ (1.000000,0.000000) [0.000000|7.000000] "" Vector__XXX
 SG_ PSD_Attribut_5_Wert m1 : 53|4@1+ (1.000000,0.000000) [0.000000|15.000000] "" Motor_BEV
 SG_ PSD_Steigung_2_Vorz m4 : 53|1@1+ (1.000000,0.000000) [0.000000|1.000000] "" Motor_BEV
 SG_ PSD_Sys_Quali_Strassenkennz m0 : 54|3@1+ (1.000000,0.000000) [0.000000|7.000000] "Unit_None" Vector__XXX
 SG_ PSD_Wechselverkehrszeichen_Typ m2 : 54|2@1+ (1.000000,0.000000) [0.000000|3.000000] "" Vector__XXX
 SG_ PSD_Baum_Ausrichtung m3 : 54|10@1+ (0.351562,0.000000) [0.000000|359.648438] "Unit_DegreOfArc" Vector__XXX
 SG_ PSD_Steigung_2_Offset m4 : 54|7@1+ (2.000000,0.000000) [0.000000|254.000000] "Unit_Meter" Motor_BEV
 SG_ PSD_Ges_Gesetzlich_Kategorie m2 : 56|3@1+ (1.000000,0.000000) [0.000000|7.000000] "" Motor_BEV
 SG_ PSD_Sys_Quali_Tempolimits m0 : 57|3@1+ (1.000000,0.000000) [0.000000|7.000000] "Unit_None" Vector__XXX
 SG_ PSD_Attribute_Komplett_06 m1 : 57|1@1+ (1.000000,0.000000) [0.000000|1.000000] "" Motor_BEV
 SG_ PSD_Ges_Gesetzlich_Zusatz m2 : 59|2@1+ (1.000000,0.000000) [0.000000|3.000000] "" Motor_BEV
 SG_ PSD_Sys_Quali_Vorfahrtsregelung m0 : 60|3@1+ (1.000000,0.000000) [0.000000|7.000000] "Unit_None" Vector__XXX
 SG_ PSD_Ges_Verkehrszeichen_Quelle m2 : 61|2@1+ (1.000000,0.000000) [0.000000|3.000000] "" Motor_BEV
 SG_ PSD_Steigung_2_Attribute_kompl m4 : 61|1@1+ (1.000000,0.000000) [0.000000|1.000000] "" Motor_BEV
 SG_ PSD_Ges_Attribute_Komplett m2 : 63|1@1+ (1.000000,0.000000) [0.000000|1.000000] "" Motor_BEV

BO_ 591 RDR1_Objekte_02: 64 ICAS1_Gateway
 SG_ RDR1_relevanter_Fehler  : 12|1@1+ (1.000000,0.000000) [0.000000|1.000000] "" Motor_BEV
 SG_ RDR1_Blindheit_erkannt  : 13|1@1+ (1.000000,0.000000) [0.000000|1.000000] "" Motor_BEV
 SG_ RDR1_relev_Nichtverfuegbarkeit  : 14|1@1+ (1.000000,0.000000) [0.000000|1.000000] "" Motor_BEV
 SG_ RDR1_Obj_01_Nummer  : 16|6@1+ (1.000000,0.000000) [0.000000|63.000000] "" Vector__XXX
 SG_ RDR1_Obj_02_Nummer  : 22|6@1+ (1.000000,0.000000) [0.000000|63.000000] "" Vector__XXX
 SG_ RDR1_Obj_03_Nummer  : 28|6@1+ (1.000000,0.000000) [0.000000|63.000000] "" Vector__XXX
 SG_ RDR1_Obj_04_Nummer  : 34|6@1+ (1.000000,0.000000) [0.000000|63.000000] "" Vector__XXX
 SG_ RDR1_Obj_05_Nummer  : 40|6@1+ (1.000000,0.000000) [0.000000|63.000000] "" Vector__XXX
 SG_ RDR1_Obj_06_Nummer  : 46|6@1+ (1.000000,0.000000) [0.000000|63.000000] "" Vector__XXX
 SG_ RDR1_Verkehrssinn  : 52|2@1+ (1.000000,0.000000) [0.000000|3.000000] "" Vector__XXX
 SG_ RDR1_Objekte_02_Datenalter  : 54|10@1+ (0.000977,0.000000) [0.000000|0.998047] "Unit_Secon" Vector__XXX
 SG_ RDR1_Obj_01_dx_v  : 64|12@1+ (0.062500,0.000000) [0.000000|255.937500] "Unit_Meter" Motor_BEV
 SG_ RDR1_Obj_01_dy_v  : 76|10@1+ (0.062500,-32.000000) [-32.000000|31.937500] "Unit_Meter" Motor_BEV
 SG_ RDR1_Obj_01_vx_v  : 86|10@1+ (0.250000,-128.000000) [-128.000000|127.750000] "Unit_MeterPerSecon" Motor_BEV
 SG_ RDR1_Obj_02_dx_v  : 96|12@1+ (0.062500,0.000000) [0.000000|255.937500] "Unit_Meter" Vector__XXX
 SG_ RDR1_Obj_02_dy_v  : 108|10@1+ (0.062500,-32.000000) [-32.000000|31.937500] "Unit_Meter" Vector__XXX
 SG_ RDR1_Obj_02_vx_v  : 118|10@1+ (0.250000,-128.000000) [-128.000000|127.750000] "Unit_MeterPerSecon" Vector__XXX
 SG_ RDR1_Obj_03_dx_v  : 128|12@1+ (0.062500,0.000000) [0.000000|255.937500] "Unit_Meter" Vector__XXX
 SG_ RDR1_Obj_03_dy_v  : 140|10@1+ (0.062500,-32.000000) [-32.000000|31.937500] "Unit_Meter" Vector__XXX
 SG_ RDR1_Obj_03_vx_v  : 150|10@1+ (0.250000,-128.000000) [-128.000000|127.750000] "Unit_MeterPerSecon" Vector__XXX
 SG_ RDR1_Obj_04_dx_v  : 160|12@1+ (0.062500,0.000000) [0.000000|255.937500] "Unit_Meter" Motor_BEV
 SG_ RDR1_Obj_04_dy_v  : 172|10@1+ (0.062500,-32.000000) [-32.000000|31.937500] "Unit_Meter" Vector__XXX
 SG_ RDR1_Obj_04_vx_v  : 182|10@1+ (0.250000,-128.000000) [-128.000000|127.750000] "Unit_MeterPerSecon" Motor_BEV
 SG_ RDR1_Obj_05_dx_v  : 192|12@1+ (0.062500,0.000000) [0.000000|255.937500] "Unit_Meter" Vector__XXX
 SG_ RDR1_Obj_05_dy_v  : 204|10@1+ (0.062500,-32.000000) [-32.000000|31.937500] "Unit_Meter" Vector__XXX
 SG_ RDR1_Obj_05_vx_v  : 214|10@1+ (0.250000,-128.000000) [-128.000000|127.750000] "Unit_MeterPerSecon" Vector__XXX
 SG_ RDR1_Obj_06_dx_v  : 224|12@1+ (0.062500,0.000000) [0.000000|255.937500] "Unit_Meter" Vector__XXX
 SG_ RDR1_Obj_06_dy_v  : 236|10@1+ (0.062500,-32.000000) [-32.000000|31.937500] "Unit_Meter" Vector__XXX
 SG_ RDR1_Obj_06_vx_v  : 246|10@1+ (0.250000,-128.000000) [-128.000000|127.750000] "Unit_MeterPerSecon" Vector__XXX
 SG_ RDR1_Obj_01_ax_v  : 256|8@1+ (0.125000,-16.000000) [-16.000000|15.750000] "Unit_MeterPerSeconSquar" Motor_BEV
 SG_ RDR1_Obj_01_ax_StdA  : 264|6@1+ (0.125000,0.000000) [0.000000|7.750000] "Unit_MeterPerSeconSquar" Motor_BEV
 SG_ RDR1_Obj_01_vx_StdA  : 270|7@1+ (0.031250,0.000000) [0.000000|3.937500] "Unit_MeterPerSecon" Motor_BEV
 SG_ RDR1_Obj_01_dx_StdA  : 277|7@1+ (0.050000,0.000000) [0.000000|6.300000] "Unit_Meter" Motor_BEV
 SG_ RDR1_Obj_01_dy_StdA  : 284|7@1+ (0.062500,0.000000) [0.000000|7.875000] "Unit_Meter" Motor_BEV

BO_ 2033 Request_Airbag_Deployment: 8 ICAS1_Gateway
 SG_ Request_Airbag_Deployment  : 0|64@1+ (1.000000,0.000000) [0.000000|18446744073709551616.000000] "" Airbag

BO_ 2041 Response_Airbag_Deployment: 8 Airbag
 SG_ Response_Airbag_Deployment  : 0|64@1+ (1.000000,0.000000) [0.000000|18446744073709551616.000000] "" ICAS1_Gateway

BO_ 980 SMLS_01: 8 ICAS1_Gateway
 SG_ SMLS_01_CRC  : 0|8@1+ (1.000000,0.000000) [0.000000|255.000000] "" Vector__XXX
 SG_ SMLS_01_BZ  : 8|4@1+ (1.000000,0.000000) [0.000000|15.000000] "" Vector__XXX
 SG_ BH_Blinker_li  : 12|1@1+ (1.000000,0.000000) [0.000000|1.000000] "" Motor_BEV
 SG_ BH_Blinker_re  : 13|1@1+ (1.000000,0.000000) [0.000000|1.000000] "" Motor_BEV
 SG_ BH_Lichthupe  : 14|1@1+ (1.000000,0.000000) [0.000000|1.000000] "" Vector__XXX
 SG_ BH_Fernlicht  : 15|1@1+ (1.000000,0.000000) [0.000000|1.000000] "" Vector__XXX
 SG_ WH_Tipwischen  : 16|1@1+ (1.000000,0.000000) [0.000000|1.000000] "" Vector__XXX
 SG_ WH_Intervall  : 17|1@1+ (1.000000,0.000000) [0.000000|1.000000] "" Vector__XXX
 SG_ WH_WischerStufe1  : 18|1@1+ (1.000000,0.000000) [0.000000|1.000000] "" Vector__XXX
 SG_ WH_WischerStufe2  : 19|1@1+ (1.000000,0.000000) [0.000000|1.000000] "" Vector__XXX
 SG_ WH_Frontwaschen  : 20|1@1+ (1.000000,0.000000) [0.000000|1.000000] "" Vector__XXX
 SG_ WH_Heckintervall  : 21|1@1+ (1.000000,0.000000) [0.000000|1.000000] "" Vector__XXX
 SG_ WH_Heckwaschen  : 22|1@1+ (1.000000,0.000000) [0.000000|1.000000] "" Vector__XXX
 SG_ WH_Intervallstufen  : 23|4@1+ (1.000000,0.000000) [0.000000|15.000000] "" Vector__XXX
 SG_ FAS_Taster  : 27|1@1+ (1.000000,0.000000) [0.000000|1.000000] "" Vector__XXX
 SG_ FAS_Taster_Fehler  : 28|1@1+ (1.000000,0.000000) [0.000000|1.000000] "" Vector__XXX
 SG_ SMLS_Hupe  : 29|1@1+ (1.000000,0.000000) [0.000000|1.000000] "" Vector__XXX
 SG_ LRH_on_off  : 30|2@1+ (1.000000,0.000000) [0.000000|3.000000] "" Vector__XXX
 SG_ LSS_Tastencode  : 32|8@1+ (1.000000,0.000000) [0.000000|255.000000] "" Vector__XXX
 SG_ LRH_aktiv  : 40|1@1+ (1.000000,0.000000) [0.000000|1.000000] "" Vector__XXX
 SG_ SMLS_P_verriegelt  : 41|2@1+ (1.000000,0.000000) [0.000000|3.000000] "" Vector__XXX
 SG_ SMLS_P_verriegelt_plausibel  : 43|1@1+ (1.000000,0.000000) [0.000000|1.000000] "" Vector__XXX
 SG_ WH_SRA  : 44|1@1+ (1.000000,0.000000) [0.000000|1.000000] "" Vector__XXX
 SG_ WH_Wischer_Fehler  : 45|1@1+ (1.000000,0.000000) [0.000000|1.000000] "" Vector__XXX
 SG_ BH_Blinker_Fehler  : 46|1@1+ (1.000000,0.000000) [0.000000|1.000000] "" Vector__XXX
 SG_ SMLS_PTT  : 47|1@1+ (1.000000,0.000000) [0.000000|1.000000] "" Vector__XXX
 SG_ WH_Tipwischen_lang  : 48|1@1+ (1.000000,0.000000) [0.000000|1.000000] "" Vector__XXX

BO_ 2464153718 SOK_FoD_MO_01_Req_Chal_01: 8 Motor_BEV
 SG_ SOK_FoD_MO_01_Req_Challenge  : 0|64@1+ (1.000000,0.000000) [0.000000|18446744073709551616.000000] "Unit_None" ICAS1_Gateway

BO_ 2464284790 SOK_FoD_MO_01_Resp_Chal_01: 8 ICAS1_Gateway
 SG_ SOK_FoD_MO_01_Resp_Challenge  : 0|64@1+ (1.000000,0.000000) [0.000000|18446744073709551616.000000] "Unit_None" Motor_BEV

BO_ 1413 Systeminfo_01: 8 ICAS1_Gateway
 SG_ SI_Sammel_SG_Fehler  : 0|6@1+ (1.000000,0.000000) [0.000000|60.000000] "" Vector__XXX
 SG_ SI_P_Mode_gueltig  : 6|1@1+ (1.000000,0.000000) [0.000000|1.000000] "" Vector__XXX
 SG_ SI_Diagnose_Aktiv  : 7|1@1+ (1.000000,0.000000) [0.000000|1.000000] "" Vector__XXX
 SG_ SI_QRS_Mode  : 8|1@1+ (1.000000,0.000000) [0.000000|1.000000] "" Airbag Motor_BEV
 SG_ SI_T_Mode  : 9|1@1+ (1.000000,0.000000) [0.000000|1.000000] "" Motor_BEV
 SG_ SI_NWDF  : 10|1@1+ (1.000000,0.000000) [0.000000|1.000000] "" Vector__XXX
 SG_ SI_NWDF_gueltig  : 11|1@1+ (1.000000,0.000000) [0.000000|1.000000] "" Vector__XXX
 SG_ SI_Sammelfehler  : 12|1@1+ (1.000000,0.000000) [0.000000|1.000000] "" Vector__XXX
 SG_ GW_KD_Fehler  : 13|1@1+ (1.000000,0.000000) [0.000000|1.000000] "" Vector__XXX
 SG_ SI_T_Schutz  : 14|1@1+ (1.000000,0.000000) [0.000000|1.000000] "" Motor_BEV
 SG_ SI_P_Mode  : 15|1@1+ (1.000000,0.000000) [0.000000|1.000000] "" Vector__XXX
 SG_ SI_BUS_01  : 16|1@1+ (1.000000,0.000000) [0.000000|1.000000] "" Vector__XXX
 SG_ SI_BUS_02  : 17|1@1+ (1.000000,0.000000) [0.000000|1.000000] "" Vector__XXX
 SG_ SI_BUS_03  : 18|1@1+ (1.000000,0.000000) [0.000000|1.000000] "" Vector__XXX
 SG_ SI_BUS_04  : 19|1@1+ (1.000000,0.000000) [0.000000|1.000000] "" Vector__XXX
 SG_ SI_BUS_05  : 20|1@1+ (1.000000,0.000000) [0.000000|1.000000] "" Vector__XXX
 SG_ SI_BUS_06  : 21|1@1+ (1.000000,0.000000) [0.000000|1.000000] "" Vector__XXX
 SG_ SI_BUS_07  : 22|1@1+ (1.000000,0.000000) [0.000000|1.000000] "" Vector__XXX
 SG_ SI_BUS_08  : 23|1@1+ (1.000000,0.000000) [0.000000|1.000000] "" Vector__XXX
 SG_ SI_BUS_09  : 24|1@1+ (1.000000,0.000000) [0.000000|1.000000] "" Vector__XXX
 SG_ SI_BUS_10  : 25|1@1+ (1.000000,0.000000) [0.000000|1.000000] "" Vector__XXX
 SG_ SI_BUS_11  : 26|1@1+ (1.000000,0.000000) [0.000000|1.000000] "" Vector__XXX
 SG_ SI_BUS_12  : 27|1@1+ (1.000000,0.000000) [0.000000|1.000000] "" Vector__XXX
 SG_ SI_BUS_13  : 28|1@1+ (1.000000,0.000000) [0.000000|1.000000] "" Vector__XXX
 SG_ SI_BUS_14  : 29|1@1+ (1.000000,0.000000) [0.000000|1.000000] "" Vector__XXX
 SG_ SI_BUS_15  : 30|1@1+ (1.000000,0.000000) [0.000000|1.000000] "" Vector__XXX
 SG_ SI_Bus_Identifikation  : 32|8@1+ (1.000000,0.000000) [0.000000|255.000000] "" Vector__XXX
 SG_ SI_CAB_V10  : 40|24@1+ (1.000000,0.000000) [0.000000|16777215.000000] "" Vector__XXX

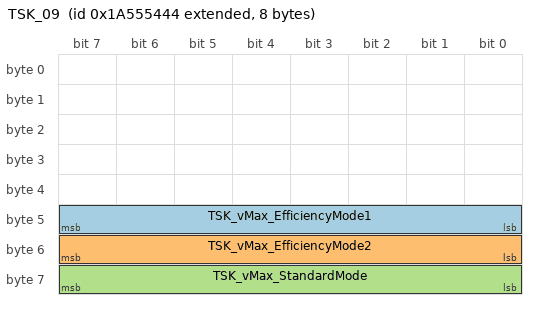
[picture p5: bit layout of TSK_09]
BO_ 2589283396 TSK_09: 8 Motor_BEV
 SG_ TSK_vMax_EfficiencyMode1  : 40|8@1+ (1.000000,0.000000) [0.000000|253.000000] "Unit_KiloMeterPerHour" ICAS1_Gateway
 SG_ TSK_vMax_EfficiencyMode2  : 48|8@1+ (1.000000,0.000000) [0.000000|253.000000] "Unit_KiloMeterPerHour" ICAS1_Gateway
 SG_ TSK_vMax_StandardMode  : 56|8@1+ (1.000000,0.000000) [0.000000|253.000000] "Unit_KiloMeterPerHour" ICAS1_Gateway

CM_ BO_ 2621506048 "VDCfunktionalerRequestaufCANFD";
CM_ BO_ 980 "AbMQB7.2";
CM_ BO_ 1413 "MQB,MLBevo";
CM_ SG_ 2600468501 NM_Airbag_01_CBV_AWB "DasSignalistzusetzen,wenndasSGaktivdenBusgeweckthat";
CM_ SG_ 2600468501 NM_Airbag_01_CBV_CRI "DasSignalistdauerhaftgesetzt,wenndasNM-LayoutdemneuenNM-LayoutfürTeilnetzbetriebentspricht";
CM_ SG_ 2600468501 NM_Airbag_01_NM_State "1=ZustandRepeatMessage(<--Bus-SleepMode)
2 = Zustand Repeat Message (<-- Prepare Bus-Sleep Mode)
4 = Zustand Normal Operation (<-- Repeat Message)
8 = Zustand Normal Operation (<-- Ready Sleep)";
CM_ SG_ 2600468501 NM_Airbag_01_Car_Wakeup "CarWakeup(Gatewaywertetaus)
MQB: Klemme 15 ist unplausibel (Kl.-15 HW ist ein, Kl.-15 SW aus) und muss dem Fahrer angezeigt werden (dauerhaft)";
CM_ SG_ 2600468501 NM_Airbag_01_UDS_CC "FunktionseinschränkungaufgrundaktivemUDS-CommunicationControl;sieheVW80124";
CM_ SG_ 2600468501 NM_Airbag_01_NM_aktiv_KL15 "SteuergeräthatKL15-EINerkannt";
CM_ SG_ 2600468501 NM_Airbag_01_NM_aktiv_Diagnose "DiagnosebefindetsichnachVW80124ineinerNonDefaultDiagnostic-Session,z.B.ExtendedDiagnostic-Session";
CM_ SG_ 2600468501 NM_Airbag_01_NM_aktiv_Tmin "Mindestaktivzeitistnochnichtabgelaufen(beijedemWeckereigniswirddieMindestaktivzeitneugestartet)";
CM_ SG_ 2600468501 NM_Airbag_01_CAB_V10 "CAB=Clusteraktivbits(V10)";
CM_ SG_ 2600468604 NM_EMotor_01_CBV_AWB "DasSignalistzusetzen,wenndasSGaktivdenBusgeweckthat";
CM_ SG_ 2600468604 NM_EMotor_01_CBV_CRI "DasSignalistdauerhaftgesetzt,wenndasNM-LayoutdemneuenNM-LayoutfürTeilnetzbetriebentspricht";
CM_ SG_ 2600468604 NM_EMotor_01_NM_State "1=ZustandRepeatMessage(<--Bus-SleepMode)
2 = Zustand Repeat Message (<-- Prepare Bus-Sleep Mode)
4 = Zustand Normal Operation (<-- Repeat Message)
8 = Zustand Normal Operation (<-- Ready Sleep)";
CM_ SG_ 2600468604 NM_EMotor_01_Car_Wakeup "CarWakeup(Gatewaywertetaus)
";
CM_ SG_ 2600468604 NM_EMotor_01_UDS_CC "FunktionseinschränkungaufgrundaktivemUDS-CommunicationControl;sieheVW80124";
CM_ SG_ 2600468604 NM_EMotor_01_NM_aktiv_KL15 "SteuergeräthatKL15-EINerkannt";
CM_ SG_ 2600468604 NM_EMotor_01_NM_aktiv_Diagnose "DiagnosebefindetsichnachVW80124ineinerNonDefaultDiagnostic-Session,z.B.ExtendedDiagnostic-Session";
CM_ SG_ 2600468604 NM_EMotor_01_NM_aktiv_Tmin "Mindestaktivzeitistnochnichtabgelaufen(beijedemWeckereigniswirddieMindestaktivzeitneugestartet)";
CM_ SG_ 2600468604 NM_EMotor_01_keine_HV_Entl "DieserBuswirdwachgehalten,weilkeineHV-Entladungmöglich";
CM_ SG_ 2600468604 NM_EMotor_01_CAB_V10 "CAB=Clusteraktivbits(V10)";
CM_ SG_ 2600468496 NM_Gateway_CBV_AWB "DasSignalistzusetzen,wenndasSGaktivdenBusgeweckthat";
CM_ SG_ 2600468496 NM_Gateway_CBV_CRI "DasSignalistdauerhaftgesetzt,wenndasNM-LayoutdemneuenNM-LayoutfürTeilnetzbetriebentspricht";
CM_ SG_ 2600468496 NM_Gateway_NM_State "1=ZustandRepeatMessage(<--Bus-SleepMode)
2 = Zustand Repeat Message (<-- Prepare Bus-Sleep Mode)
4 = Zustand Normal Operation (<-- Repeat Message)
8 = Zustand Normal Operation (<-- Ready Sleep)
16 = Zustand Repeat Message (<-- Ready Sleep)
32 ";
CM_ SG_ 2600468496 NM_Gateway_Car_Wakeup "CarWakeup(Subbusmasterwertetaus)

MQB:
-Diagnose- oder Komponentenschutzmaster-Funktion weckt den schlafenden Subbus (z.B. MOST)

MEB:
- Diagnose aktiv -aktive Diagnosekommunikation am OBD-Stecker";
CM_ SG_ 2600468496 NM_Gateway_UDS_CC "FunktionseinschränkungaufgrundaktivemUDS-CommunicationControl;sieheVW80124";
CM_ SG_ 2600468496 NM_Gateway_NM_aktiv_KL15 "SteuergeräthatKL15-EINerkannt";
CM_ SG_ 2600468496 NM_Gateway_NM_aktiv_Diagnose "DiagnosebefindetsichnachVW80124ineinerNonDefaultDiagnostic-Session,z.B.ExtendedDiagnostic-Session";
CM_ SG_ 2600468496 NM_Gateway_NM_aktiv_Tmin "Mindestaktivzeitistnochnichtabgelaufen(beijedemWeckereigniswirddieMindestaktivzeitneugestartet)";
CM_ SG_ 2600468496 NM_Gateway_CAB_V10 "CAB=Clusteraktivbits(V10)";
CM_ SG_ 2600468664 NM_LE2_CBV_AWB "DasSignalistzusetzen,wenndasSGaktivdenBusgeweckthat";
CM_ SG_ 2600468664 NM_LE2_CBV_CRI "DasSignalistdauerhaftgesetzt,wenndasNM-LayoutdemneuenNM-LayoutfürTeilnetzbetriebentspricht";
CM_ SG_ 2600468664 NM_LE2_NM_State "1=ZustandRepeatMessage(<--Bus-SleepMode)
2 = Zustand Repeat Message (<-- Prepare Bus-Sleep Mode)
4 = Zustand Normal Operation (<-- Repeat Message)
8 = Zustand Normal Operation (<-- Ready Sleep)
16 = Zustand Repeat Message (<-- Ready Sleep)
32 ";
CM_ SG_ 2600468664 NM_LE2_Car_Wakeup "CarWakeup(Gatewaywertetaus)";
CM_ SG_ 2600468664 NM_LE2_UDS_CC "FunktionseinschränkungaufgrundaktivemUDS-CommunicationControl;sieheVW80124";
CM_ SG_ 2600468664 NM_LE2_NM_aktiv_KL15 "SteuergeräthatKL15-EINerkannt";
CM_ SG_ 2600468664 NM_LE2_NM_aktiv_Diagnose "DiagnosebefindetsichnachVW80124ineinerNonDefaultDiagnostic-Session,z.B.ExtendedDiagnostic-Session";
CM_ SG_ 2600468664 NM_LE2_NM_aktiv_Tmin "Mindestaktivzeitistnochnichtabgelaufen(beijedemWeckereigniswirddieMindestaktivzeitneugestartet)";
CM_ SG_ 2600468664 NM_LE2_keine_HV_entl "DieserBuswirdwachgehalten,weilkeineHV-Entladungmöglich";
CM_ SG_ 2600468664 NM_LE2_CAB_V10 "CAB=Clusteraktivbits(V10)";
CM_ SG_ 2600468598 NM_MO_01_CBV_AWB "DasSignalistzusetzen,wenndasSGaktivdenBusgeweckthat";
CM_ SG_ 2600468598 NM_MO_01_CBV_CRI "DasSignalistdauerhaftgesetzt,wenndasNM-LayoutdemneuenNM-LayoutfürTeilnetzbetriebentspricht";
CM_ SG_ 2600468598 NM_MO_01_NM_State "1=ZustandRepeatMessage(<--Bus-SleepMode)
2 = Zustand Repeat Message (<-- Prepare Bus-Sleep Mode)
4 = Zustand Normal Operation (<-- Repeat Message)
8 = Zustand Normal Operation (<-- Ready Sleep)
16 = Zustand Repeat Message (<-- Ready Sleep)
32 ";
CM_ SG_ 2600468598 NM_MO_01_Car_Wakeup "CarWakeup(Gatewaywertetaus)
MQB:
- Betanken (Drucktank): gesetzt nur zum busübergreifenden Wachhalten (des BCM für Hybrid)
- Standklimatisierung (Vorhalt)
- Hybrid-Manager deaktiviert alle Hochvolt-Verbraucher für stromloses Öffnen der Batteriesch";
CM_ SG_ 2600468598 NM_MO_01_UDS_CC "FunktionseinschränkungaufgrundaktivemUDS-CommunicationControl;sieheVW80124";
CM_ SG_ 2600468598 NM_MO_01_NM_aktiv_KL15 "SteuergeräthatKL15-EINerkannt";
CM_ SG_ 2600468598 NM_MO_01_NM_aktiv_Diagnose "DiagnosebefindetsichnachVW80124ineinerNonDefaultDiagnostic-Session,z.B.ExtendedDiagnostic-Session";
CM_ SG_ 2600468598 NM_MO_01_NM_aktiv_Tmin "Mindestaktivzeitistnochnichtabgelaufen(beijedemWeckereigniswirddieMindestaktivzeitneugestartet)";
CM_ SG_ 2600468598 NM_MO_01_NM_aktiv_Betankung "BetankungDrucktank";
CM_ SG_ 2600468598 NM_MO_01_NM_aktiv_Waehlhebel "DerWaehlhebelMQBsetztwegenForderungderFunktion'Verlassenswarnung'NM-Highum.BeimE-Fzg.istderMasterdesWaehlhebelsdasMotor-SG.
Daher ist ein neuer Nachlaufgrund des Motors erforderlich, wenn die Wählhebelposition gefordert wird.";
CM_ SG_ 2600468598 NM_MO_01_NM_aktiv_HV_Abschaltung "Hybrid-ManagerdeaktiviertalleHochvolt-VerbraucherfürstromlosesÖffnenderBatterieschütze";
CM_ SG_ 2600468598 NM_MO_01_NM_aktiv_Hochvolt "Hochvoltaktiv";
CM_ SG_ 2600468598 NM_MO_01_CAB_V10 "CAB=Clusteraktivbits(V10)";
CM_ SG_ 2600468733 NM_Waehlhebel_CBV_AWB "DasSignalistzusetzen,wenndasSGaktivdenBusgeweckthat";
CM_ SG_ 2600468733 NM_Waehlhebel_CBV_CRI "DasSignalistdauerhaftgesetzt,wenndasNM-LayoutdemneuenNM-LayoutfürTeilnetzbetriebentspricht";
CM_ SG_ 2600468733 NM_Waehlhebel_NM_State "1=ZustandRepeatMessage(<--Bus-SleepMode)
2 = Zustand Repeat Message (<-- Prepare Bus-Sleep Mode)
4 = Zustand Normal Operation (<-- Repeat Message)
8 = Zustand Normal Operation (<-- Ready Sleep)";
CM_ SG_ 2600468733 NM_Waehlhebel_Car_Wakeup "CarWakeup(Gatewaywertetaus)

MLBevo: Fahrerwunsch_P";
CM_ SG_ 2600468733 NM_Waehlhebel_UDS_CC "FunktionseinschränkungaufgrundaktivemUDS-CommunicationControl;sieheVW80124";
CM_ SG_ 2600468733 NM_Waehlhebel_NM_aktiv_KL15 "SteuergeräthatKL15-EINerkannt";
CM_ SG_ 2600468733 NM_Waehlhebel_NM_aktiv_Diagnose "DiagnosebefindetsichnachVW80124ineinerNonDefaultDiagnostic-Session,z.B.ExtendedDiagnostic-Session";
CM_ SG_ 2600468733 NM_Waehlhebel_NM_aktiv_Tmin "Mindestaktivzeitistnochnichtabgelaufen(beijedemWeckereigniswirddieMindestaktivzeitneugestartet)";
CM_ SG_ 2600468733 NM_Waehlhebel_CAB_V10 "CAB=Clusteraktivbits(V10)";
CM_ SG_ 2621440533 OBDC_Airbag_01_Req_FD_Data "TP-KanalfürdenOnboardDatensammler";
CM_ SG_ 2621571605 OBDC_Airbag_01_Resp_FD_Data "TP-KanalfürdenOnboardDatensammler";
CM_ SG_ 2621506048 OBDC_Funktion_Req_All_FD_Data "VDCfunktionalerRequestaufCANFD";
CM_ SG_ 2564502513 OBDx_allOBD_Req_Data "29bitOBD";
CM_ SG_ 2564425457 OBDx_LE1_Req_Data "29bitOBD";
CM_ SG_ 2564485382 OBDx_LE1_Resp_Data "29bitOBD";
CM_ SG_ 2564425713 OBDx_LE2_Req_Data "29bitOBD";
CM_ SG_ 2564485383 OBDx_LE2_Resp_Data "29bitOBD";
CM_ SG_ 2564424177 OBDx_MO_01_Req_Data "29bitOBDDiagnose";
CM_ SG_ 2564485377 OBDx_MO_01_Resp_Data "29bitOBDDiagnose";
CM_ SG_ 627 OCC_01_CRC "FürMLB:
Berechnung siehe Lastenheft 'Kommunikationsabsicherung für FlexRay und CAN'
Ab MQB und MLBevo:
Berechnung siehe Lastenheft 'End-to-End Kommunikationsabsicherung'

Endwerte siehe Begleitdokument 'S-PDU Kennungsfolgen'";
CM_ SG_ 627 OCC_01_BZ "4bitBotschaftszähler,wirdmitjederSendebotschaftinkrementiert";
CM_ SG_ 627 OCC_Stecker_Status "StelltdenStatusdesLadesteckershinsichtlichPräsenzzurVerfügung";
CM_ SG_ 627 OCC_Status_Spgfreiheit "StatusderSpannungsfreiheitfürdenOnboardChargeClient";
CM_ SG_ 627 OCC_DC_IstStrom "aktuellerIststromdesOCC";
CM_ SG_ 627 OCC_CC_Latchstatus_DC_GBT "GibtdenLatchstatusdesDC-SteckersfürChinaaus";
CM_ SG_ 627 OCC_Status_EoHVL "ErkennungeineroffenenHV-Leitung(EoHVL),bewertetanhandeinerSpannungsgrenze";
CM_ SG_ 627 OCC_I_istAC_Netz_L1 "aktuellerAC-IststromamEingangskreisPhase1desOCC";
CM_ SG_ 627 OCC_PP_Latchstatus_A "LatchstatusPlugPresentA";
CM_ SG_ 627 OCC_PP_Latchstatus_B "LatchstatusPlugPresentB";
CM_ SG_ 627 OCC_I_istAC_Netz_L2 "aktuellerAC-IststromamEingangskreisPhase2desOCC";
CM_ SG_ 627 OCC_I_istAC_Netz_L3 "aktuellerAC-IststromamEingangskreisPhase3desOCC";
CM_ SG_ 627 OCC_IstModus "aktuellerFunktionszustanddesOCC";
CM_ SG_ 627 OCC_CP_Status_A "StatusAdesControlPilots";
CM_ SG_ 627 OCC_CP_Status_B "StatusBdesControlPilots";
CM_ SG_ 627 OCC_IstSpannung_HV "aktuelleDC-AusgangsspannungdesOCC";
CM_ SG_ 627 OCC_PP_Status_A "StatusPlugPresentA";
CM_ SG_ 627 OCC_PP_Status_B "StatusPlugPresentB";
CM_ SG_ 627 OCC_CC_Status_DC_GBT "GibtdenStatusdesDC-SteckersfürChinaaus";
CM_ SG_ 627 OCC_CC_Fehlerstatus_DC_GBT "GibtdenFehlerstatusdesDC-SteckersfürChinaaus";
CM_ SG_ 627 OCC_Temp_Sensor_Fehlerstatus_DC "FehlerstatusTemperatursensorLadedosebeimDC-Laden";
CM_ SG_ 627 OCC_Temp_Sensor_Fehlerstatus_AC "FehlerstatusTemperatursensorLadedosebeimAC-Laden";
CM_ SG_ 627 OCC_Temp_Sensor_Status "TemperaturandenTemp-SensorenLadedosefürdasDC-Laden.";
CM_ SG_ 2463978709 OCC_CP_Tastgrad_A "TastgradControlPilotA";
CM_ SG_ 2463978709 OCC_CP_Tastgrad_B "TastgradControlPilotB";
CM_ SG_ 2463978709 OCC_CP_Frequenz_A "FrequenzControlPilotA";
CM_ SG_ 2463978709 OCC_CP_Frequenz_B "FrequenzControlPilotB";
CM_ SG_ 2463978709 OCC_CP_Spannung_A "SpannungControlPilotA";
CM_ SG_ 2463978709 OCC_CP_Spannung_B "SpannungControlPilotB";
CM_ SG_ 2463978709 OCC_CP_Fehlerstatus_A "FehlerstatusControlPilotA";
CM_ SG_ 2463978709 OCC_CP_Fehlerstatus_B "FehlerstatusControlPilotB";
CM_ SG_ 2463978709 OCC_Temp_Ladedose_A_AC "aktuelleTemperaturderAC-Ladedose";
CM_ SG_ 2463978709 OCC_Temp_Ladedose_A_DC_minus "aktuelleTemperaturdesPinsDC(-)derLadedoseA";
CM_ SG_ 2463978709 OCC_Temp_Ladedose_A_DC_plus "aktuelleTemperaturdesPinsDC(+)derLadedoseA";
CM_ SG_ 2463978709 OCC_U_istAC_Netz_L1 "aktuelleAC-IstspannungamEingangskreisPhase1desOCC";
CM_ SG_ 2463978709 OCC_U_istAC_Netz_L2 "aktuelleAC-IstspannungamEingangskreisPhase2desOCC";
CM_ SG_ 2463978709 OCC_U_istAC_Netz_L3 "aktuelleAC-IstspannungamEingangskreisPhase3desOCC";
CM_ SG_ 2463978709 OCC_StatusVerEntriegelungAktor_A "gibtdenStatusderAnsteuerungdesVerriegelungsaktorsimFahrzeugan";
CM_ SG_ 2463978709 OCC_SteckerEntriegelung_Verbot_A "VerbotzurLadesteckerentriegelung";
CM_ SG_ 2463978709 OCC_StatusVerEntriegelungAktor_B "gibtdenStatusderAnsteuerungdesVerriegelungsaktorsimFahrzeugan";
CM_ SG_ 2463978709 OCC_SteckerEntriegelung_Verbot_B "VerbotzurLadesteckerentriegelung";
CM_ SG_ 2463978709 OCC_Verriegelung_Status_A "ZeigtdenStatusdesVerriegelungsaktorsderLadedoseAan";
CM_ SG_ 2463978709 OCC_Verriegelung_Status_B "ZeigtdenStatusdesVerriegelungsaktorsderLadedoseanB";
CM_ SG_ 2463978709 OCC_RtmWarnLadeKommunikation "RTMWarningofchargingcommunctionfault";
CM_ SG_ 2463978709 OCC_Ist_Wirkungsgrad "aktuellerWirkungsgraddesOCC";
CM_ SG_ 2463978709 OCC_PP_Max_Strom_A "GibtdiemaximaleBelastbarkeitdesangeschlossenenLadekabelsan";
CM_ SG_ 2463978709 OCC_PP_Max_Strom_B "GibtdiemaximaleBelastbarkeitdesangeschlossenenLadekabelsan";
CM_ SG_ 2463978709 OCC_DC_MaxStrom "maximalerStromdendasOCCbeideraktuellenSpannungslageunddesvorgegebenenAC-Aufnahmenstromstellenkann";
CM_ SG_ 2463978709 OCC_Derating_Temperatur "Derating-StatusaufgrundvonTemperaturbegrenzungendesOCC";
CM_ SG_ 2463978709 OCC_Fehlerzustand "zeigtan,obimOCCeinFehleranliegt";
CM_ SG_ 2463978709 OCC_Ladest_Entriegelungs_Verbot "VerbotzurLadesteckerEntriegelung";
CM_ SG_ 2463978709 OCC_Netzfrequenz_EVU "aktuelleAC-NetzfrequenzimEingangskreisdesOCC";
CM_ SG_ 2463978709 OCC_Warnzustand "SammelwarnungOCC";
CM_ SG_ 2463978709 OCC_Kuehltemperatur "IstwertderOCC-Kühlkanaltemperatur";
CM_ SG_ 2463978709 OCC_PP_Fehlerstatus_A "FehlerstatusPlugPresentA";
CM_ SG_ 2463978709 OCC_PP_Fehlerstatus_B "FehlerstatusPlugPresentB";
CM_ SG_ 2589283656 ORU_EM_Anfrage_freigegebeneNetze "MeldungderwährendeineskonkretenOnlineRemoteUpdatesfreigegebenenNetze(12V,48V,HV)";
CM_ SG_ 2589283656 ORU_EM_Anfrage_Stromaufnahme "MeldungdervoraussichtlichendurchschnittlichenStromaufnahmeeineskonkretenOnlineRemoteUpdatesandasNVEM";
CM_ SG_ 2589283656 ORU_EM_Anfrage_Flashdauer "AnfrageandasEnergiemanagement,obeinkonkretesOnlineRemoteUpdatedurchgeführtwerdenkann-Flashdauerin10s.";
CM_ SG_ 2589283656 ORU_Warnung "WenndurchStörungenderFunktionOnlineRemoteUpdatenichtsichergestelltist,dassvorKundekeineFunktionseinschränkungenauftreten,mussderBenutzerdesFahrzeugsentsprechendgewarntwerden.";
CM_ SG_ 2589283656 ORU_Status "BroadcastdesStatusderKonzernfunktionOnlineRemoteUpdate";
CM_ SG_ 2527679741 PAO_Status_01_CRC "FürMLB:
Berechnung siehe Lastenheft 'Kommunikationsabsicherung für FlexRay und CAN'
Ab MQB und MLBevo:
Berechnung siehe Lastenheft 'End-to-End Kommunikationsabsicherung'

Endwerte siehe Begleitdokument 'S-PDU Kennungsfolgen'";
CM_ SG_ 2527679741 PAO_Status_01_BZ "4bitBotschaftszähler,wirdmitjederSendebotschaftinkrementiert";
CM_ SG_ 2527679741 PAO_ON_Status "IstwertfürLED'ON'inAnzeigePassengerAirbagOn/Off";
CM_ SG_ 2527679741 PAO_OFF_Status "IstwertfürLED'OFF'inAnzeigePassengerAirbagOn/Off";
CM_ SG_ 2527679741 PAO_Status_Reserve_Byte3 "Zweck:BefüllenderreserviertenBitpositionenmit0(wg.LIN-Teilnehmer)";
CM_ SG_ 518 Parken_BKD_Anf "AnforderungderSystemtotzeitoptimierungansVZM";
CM_ SG_ 518 Parken_Verz_Anf "ZeigtdiedieangeforderteVerzögerungan";
CM_ SG_ 518 Parken_Prefill_Anf "AnforderungPrefillamVZM";
CM_ SG_ 518 Parken_Warnruck_Anf "SignalzurAnforderungWarnruckbeimVZM";
CM_ SG_ 518 Parken_Verz_Anf_ASIL "AngabedesASILLevelsderaktuellaktivenFuntkionaufderParkplattform";
CM_ SG_ 518 Parken_Warnruckeln_Anf "AnforderungWarnruckelnbeimVZM";
CM_ SG_ 518 Parken_beibehalten "FordertdasParkenbeimHMSan";
CM_ SG_ 518 Parken_Anforderung_HMS "AnforderungderDienstedesHMSdurchdieParkplattform";
CM_ SG_ 518 Parken_Notstopp_Anf "AnforderungNotstoppderParkplattform";
CM_ SG_ 518 Parken_Anhalteweg_Anf "ZeigteineAnhaltewegAnforderungan";
CM_ SG_ 518 Parken_aktives_System "DasSignalzeigtan,welchesderParksystemeaufdemzFASgeradeaktivist.";
CM_ SG_ 518 Parken_max_Beschleunigung "MaximalezulässigeBeschleunigungderParkfunktion";
CM_ SG_ 518 Parken_Blinker_li_Anf "AnforderungseitensParkensfür'Linksblinken'";
CM_ SG_ 518 Parken_QFK_KruemmSoll "Krümmungsanforderung";
CM_ SG_ 518 Parken_QFK_KruemmSoll_VZ "VorzeichenfürdieKrümmungsanforderung";
CM_ SG_ 518 Parken_QFK_Spuerb "Spürbarkeitsanforderung.Legtfest,mitwelchemHandmomentdieangeforderteKrümmungüberlenktwerdenmuss.";
CM_ SG_ 518 Parken_QFK_AnfStat "StatusinformationendesAnforderers";
CM_ SG_ 518 Parken_QFK_Signal1 "InhaltPLA_QFK_Signal1wirddurchdasSignalPLA_QFK_Art1gesteuert.
Nähere Informationen im LAH Querführungskoordinator.";
CM_ SG_ 518 Parken_QFK_Art1 "AuswahlsignalfürParken_QFK_Signal1";
CM_ SG_ 518 Parken_QFK_Art2 "AuswahlsignalfürParken_QFK_Signal2";
CM_ SG_ 518 Parken_QFK_Signal2 "InhaltParken_QFK_Signal2wirddurchdasSignalParken_QFK_Art2gesteuert.
Nähere Informationen im LAH Querführungskoordinator.";
CM_ SG_ 518 Parken_Sollbeschleunigung "AnforderungeinerParkenfunktionandenTSK,dasFahrzeugzubeschleunigen.";
CM_ SG_ 518 Parken_Blinker_re_Anf "AnforderungseitensParkenfür'Rechtsblinken'";
CM_ SG_ 518 Parken_Status_IPA_TSK "StatusinformationvomIPAfürHandshakemechanismusmitTSK";
CM_ SG_ 518 Parken_erhoehtes_Moment "AnforderungeinerspezifiziertenMotormomenten-RampeseitensIPA/PiloPafürdasÜberfahreneinerSchwelleodereinesBordsteins.";
CM_ SG_ 518 Parken_max_Geschwindigkeit "MaximalezulässigeGeschwindigkeitderParkfunktion";
CM_ SG_ 518 Parken_Soll_Anhalteweg_Anf "AnforderungdesSollAnhaltewegesderPPFbeimVZM";
CM_ SG_ 518 Parken_Fahrstufenwunsch "FahrstufenwunschvonIPAe/RPAeandasGetriebe";
CM_ SG_ 518 IPA_TPA_Remote "StatushinsichtlichUmschaltungauffernbedientenParkvorgang";
CM_ SG_ 518 IPA_TPA_Remote_Anf "AnforderungfürfernbedientenParkvorgang";
CM_ SG_ 518 IPA_TPA_Fehler "SignalisierungeinesdurchIPAerkanntenFehlersmitAngabederFehlerart";
CM_ SG_ 518 IPA_TPA_Abbruch "SignalisierungeinesdurchIPAerkanntenAbbruchsmitAngabedesGrundes";
CM_ SG_ 518 IPA_TPA_Status "StatusderFunktionIPAgegenüberderFunktionTPA";
CM_ SG_ 2527679685 PDC_ASM_Ereignis "DiesesSignaldefiniert,welcheFunktionundwelcheArtvonAktivitätdasSendenderBotschaftandenAssistenzsystemmonitorASMveranlassthat.";
CM_ SG_ 2527679685 PDC_ASM_Zeitstempel "DiesesSignalermöglichtdiezeitlicheZuordnungdervonPDCandenAssistenzsystemmonitorASMgesendetenStatusbotschaften.";
CM_ SG_ 2527679685 PDC_ASM_Data_1 "DiesesSignalwirdvomPDCSGbefülltundandenAssistenzsystemmonitorASMgesendet.";
CM_ SG_ 2527679685 PDC_ASM_Data_2 "DiesesSignalwirdvomPDCSGbefülltundandenAssistenzsystemmonitorASMgesendet.";
CM_ SG_ 2527679685 PDC_ASM_Data_3 "DiesesSignalwirdvomPDCSGbefülltundandenAssistenzsystemmonitorASMgesendet.";
CM_ SG_ 2527679685 PDC_ASM_Data_4 "DiesesSignalwirdvomPDCSGbefülltundandenAssistenzsystemmonitorASMgesendet.";
CM_ SG_ 2527679685 PDC_ASM_Data_5 "DiesesSignalwirdvomPDCSGbefülltundandenAssistenzsystemmonitorASMgesendet.";
CM_ SG_ 2527679685 PDC_ASM_Data_6 "DiesesSignalwirdvomPDCSGbefülltundandenAssistenzsystemmonitorASMgesendet.";
CM_ SG_ 319 PreCrash_Charisma_FahrPr "AktuelleingestelltesFahrprogrammderFunktionPreCrash";
CM_ SG_ 319 PreCrash_Charisma_Status "VerfügbarkeitderFunktionPreCrashfürdieAnsteuerungdurchdenCharisma_Koordinator";
CM_ SG_ 319 PreCrash_Schiebedach_schliessen "AnforderungSchiebedachschließendurchdieFunktionPreCrash";
CM_ SG_ 319 PreCrash_Fenster_schliessen "AnforderungSeitenscheibenschließendurchdieFunktionPreCrash";
CM_ SG_ 319 PreCrash_Blinken "SafetyComputerübermitteltBlinkverhaltenbeieinerPreCrash-AuslösungandenBCM2";
CM_ SG_ 319 SC_PreSense_FCWP "MitteilungandasNightVision,aufwelcheArtvonObjekteineWarnungangefordertwird";
CM_ SG_ 319 PreCrash_Tueren_Verriegeln "AnforderungTürenVerriegelndurchdieFunktionPreCrash";
CM_ SG_ 319 PreCrash_FS_Laengsverstellung "AnsteuerungderLaengsverstellungdesFahrersitzesdurchdiePreCrash-Funktionen";
CM_ SG_ 319 PreCrash_Anforderung_AFR "AnforderungenderFunktionPrecrashSeiteanFahrwerksregelung";
CM_ SG_ 319 SC_PreCrash_LED "AnsteuerungLED-LeisteimKombidurchSC";
CM_ SG_ 319 PreCrash_FS_Pneumatik_ansteuern "AnsteuerungdesFahrersitzesdurchdiePreCrash-Funktionen";
CM_ SG_ 319 PreCrash_BFS_Pneumatik_ansteuern "AnsteuerungdesBeifahrersitzesdurchdiePreCrash-Funktionen";
CM_ SG_ 319 PreCrash_Fo_Pneumatik_ansteuern "AnsteuerungderFondsitzedurchdiePreCrash-Funktionen";
CM_ SG_ 319 PreCrash_FS_Sitzlehne_verfahren "AnsteuerungdesFahrersitzesdurchdiePreCrash-Funktionen

Wert 0x06 und 0x07 für vereinfachte Ansteuerung Sitzlehne";
CM_ SG_ 319 PreCrash_BFS_Sitzlehne_verfahren "AnsteuerungdesBeifahrersitzesdurchdiePreCrash-Funktionen

Wert 0x06 und 0x07 für vereinfachte Ansteuerung Sitzlehne";
CM_ SG_ 319 PreCrash_Fo_Sitzlehne_verfahren "AnsteuerungdesFondsitzesdurchdiePreCrash-Funktionen";
CM_ SG_ 319 PreCrash_FS_KSV_verfahren "AnsteuerungderKopfstuetzeFahrerseitedurchdiePreCrash-Funktionen

Signalwert 0x09 für vereinfachte Ansteuerung mit Logik im Sitz-SG (MQB37W)";
CM_ SG_ 319 PreCrash_BFS_KSV_verfahren "AnsteuerungderKopfstuetzeBeifahrerseitedurchdieFunktionPreCrash

Signalwert 0x09 für vereinfachte Ansteuerung mit Logik im Sitz-SG (MQB37W)";
CM_ SG_ 319 PreCrash_Fo_KSV_verfahren "AnsteuerungderKopfstuetzenimFonddurchdiePreCrash-Funktionen";
CM_ SG_ 319 PreCrash_BFS_Laengsverstellung "AnsteuerungderLaengsverstellungdesBeifahrersitzesdurchdiePreCrash-Funktionen";
CM_ SG_ 319 SC_PreCrash_Warnung "SafetyComputerübermitteltWarnungderPreCrashFunktionenanKombi";
CM_ SG_ 319 SC_PreCrash_Texte "SafetyComputerübermitteltSystemstatusderPreCrashFunktionenanKombi";
CM_ SG_ 1122 PSD_Segment_ID "IdentifierdesprädiktivenStreckensegments
";
CM_ SG_ 1122 PSD_Vorgaenger_Segment_ID "AndemStreckensegmentmitdiesemIdentifierschließtsichdasneueSegmentmitderID'PSD_01_Segment_ID'an.
";
CM_ SG_ 1122 PSD_Segmentlaenge "GesamtlängedesprädiktivenStreckensegments";
CM_ SG_ 1122 PSD_Strassenkategorie "KlassifizierungderStraßedesbeschriebenenSegments
";
CM_ SG_ 1122 PSD_Endkruemmung "'EndkrümmungderKlotoidedesübermitteltenStreckensegments.DieAnfangskrümmungdesfolgendenStreckensegmentsentsprichtderEndkrümmungdiesesSegments.Krümmung=1/(1+0.155*x²)[1/m]

";
CM_ SG_ 1122 PSD_Idenditaets_ID "IdentifieraufeinStreckensegment,dassmitdemaktuellübertragenengeometrischidentischist.";
CM_ SG_ 1122 PSD_ADAS_Qualitaet "ADASQualtitätdesStreckensegments.";
CM_ SG_ 1122 PSD_wahrscheinlichster_Pfad "IdentifiziertdenvomNavigationssystemberechnetenwahrscheinlichstenPfaddesFahrzeuges.";
CM_ SG_ 1122 PSD_Geradester_Pfad "SegmentistTeildesgeradestenPfades";
CM_ SG_ 1122 PSD_Fahrspuren_Anzahl "AnzahlderFahrspureninFahrtrichtung
";
CM_ SG_ 1122 PSD_Bebauung "SegementbefindetsichinnerhalbbebautenGebietes";
CM_ SG_ 1122 PSD_Segment_Komplett "Zeigt,oballeAttributefürdasSegmentübertragenwordensind
";
CM_ SG_ 1122 PSD_Anfangskruemmung "StartkrümmungderKlothoidedesübermitteltenabzweigendenStreckensegments.
1/(1+0.155 * x^2) {1/m}'
";
CM_ SG_ 1122 PSD_Anfangskruemmung_Vorz "VorzeichenfürdieStartkrümmungbeiAbzweigungen
";
CM_ SG_ 1122 PSD_Abzweigerichtung "Richtung,inderdieAbzweigungvonderHauptrouteabzweigt
";
CM_ SG_ 1122 PSD_Abzweigewinkel "Winkel,unterdemdieAbzweigungvonderHauptrouteabzweigt.
";
CM_ SG_ 1123 PSD_Pos_Segment_ID "IdentifierdesStreckensegments,aufdemsichdasFahrzeugaktuellbefindet
";
CM_ SG_ 1123 PSD_Pos_Segmentlaenge "VerbleibendeLängedesStreckensegments,aufdemsichdasFahrzeugaktuellbefindet
";
CM_ SG_ 1123 PSD_Pos_Inhibitzeit "ZeitspannezwischenGenerierungderPSDDatenimNavigationssystemundVersandderDatenaufdenMost
";
CM_ SG_ 1123 PSD_Pos_Standort_Eindeutig "IstdiePositiondesFahrzeugseindeutigdemaktuelleSegmentzugeordnet,odergibtesfahrbarealternativeSegmente,diebeiaktellerGPS-PositionebenfallsalsaktuellesSegmentmöglichwären.";
CM_ SG_ 1123 PSD_Pos_Fehler_Laengsrichtung "LaengsfehlerderPositionierung";
CM_ SG_ 1123 PSD_Pos_Fahrspur "Spur,aufdersichdasFahrzeugaktuellbefindet";
CM_ SG_ 1123 PSD_Attribut_Segment_ID_05 "IdentifierdesStreckensegments,fürdasdieweiterenAttributeinderBotschaftgültigsind";
CM_ SG_ 1123 PSD_Attribut_1_ID "IdentifierdeserstenAttributes";
CM_ SG_ 1123 PSD_Attribut_1_Wert "WertdeserstenAttributes";
CM_ SG_ 1123 PSD_Attribut_1_Offset "PositionsoffsetimSegmentfürdiePositiondesAttributs";
CM_ SG_ 1123 PSD_Attribut_2_ID "IdentifierdeszweitenAttributes";
CM_ SG_ 1123 PSD_Attribut_2_Wert "WertdeszweitenAttributes";
CM_ SG_ 1123 PSD_Attribut_2_Offset "PositionsoffsetimSegmentfürdiePositiondesAttributs";
CM_ SG_ 1123 PSD_Attribute_Komplett_05 "Zeigt,oballeAttributefürdasSegmentübertragenwordensind";
CM_ SG_ 1124 PSD_06_Mux "MultiplexZählerfürdiePSD_06-Botschaft.
Die unterschiedlichen Muxe folgen keiner festen Reihenfolge. Je nach Inhalt des PSD-Protokolls an der aktuellen Position werden jeweils die notwendigen PSD6-Botschaften gesendet.";
CM_ SG_ 1124 PSD_Sys_Segment_ID "IdentifierdesprädiktivenStreckensegmentsabdemdieSysteminformationengültigsind.
";
CM_ SG_ 1124 PSD_Attribut_Segment_ID "IdentifierdesStreckensegments,fürdasdieweiterenAttributeinderBotschaftgültigsind";
CM_ SG_ 1124 PSD_Ges_Segment_ID "IdentifierdesprädiktivenStreckensegmentsabdemdieGeschwindigkeitsbegrenzungenundmöglicheEinschränkungengelten.
";
CM_ SG_ 1124 PSD_Baum_Laenge_VZ "VorzeichenWGS84LaengedesFahrzeugsegments";
CM_ SG_ 1124 PSD_Steigung_1_Segment_ID "IdentifierdesprädiktivenStreckensegments,zudemdieerstenbeidenSteigungswertedieserBotschaftgehören";
CM_ SG_ 1124 PSD_Baum_Laenge "WGS84LaengedesFahrzeugsegments";
CM_ SG_ 1124 PSD_Sys_Laendercode "Ländercode
";
CM_ SG_ 1124 PSD_Attribut_3_ID "IdentifierdesdrittenAttributes";
CM_ SG_ 1124 PSD_Ges_Offset "PositionsoffsetimSegmentfürdiePositiondesAttributs";
CM_ SG_ 1124 PSD_Steigung_1_A_Steigung "SteigungdesSegmentsabOffset1A";
CM_ SG_ 1124 PSD_Attribut_3_Offset "PositionsoffsetimSegmentfürdiePositiondesAttributs";
CM_ SG_ 1124 PSD_Steigung_1_A_Vorz "VorzeichenfürSteigung1A";
CM_ SG_ 1124 PSD_Sys_Geschwindigkeit_Einheit "Unterscheidungzwischenkm/hundmiles/h";
CM_ SG_ 1124 PSD_Steigung_1_A_Offset "PositionsoffsetimSegmentfürdiePositionderSteigung1A";
CM_ SG_ 1124 PSD_Sys_Verkehrsrichtung "UnterscheidungzwischenLinksverkehrundRechtsverkehr";
CM_ SG_ 1124 PSD_Sys_Geometrieguete "MaßfürdieGütederKlothoidengeometrie.";
CM_ SG_ 1124 PSD_Sys_Mapmatchingguete "GütedesMapmatchings";
CM_ SG_ 1124 PSD_Attribut_3_Wert "WertdesdrittenAttributes";
CM_ SG_ 1124 PSD_Ges_Typ "TypderGeschwindigkeitsbegrenzung
";
CM_ SG_ 1124 PSD_Sys_Alter_Karte "AlterderKarte";
CM_ SG_ 1124 PSD_Ges_Spur_Geschw_Begrenzung "DefinitionderSpuren,fürdiedasübertrageneGebotgilt";
CM_ SG_ 1124 PSD_Steigung_1_B_Steigung "SteigungdesSegmentsabOffset1B";
CM_ SG_ 1124 PSD_Attribut_4_ID "TypvonAttribut4";
CM_ SG_ 1124 PSD_Sys_Zielfuehrung "ZielfuehrungimNavigationssystem.DamitlässtsichderwahrscheinlichstePfaddesFahrzeugeszuverlässigangeben.";
CM_ SG_ 1124 PSD_Sys_US_State "NamedesUSA-State";
CM_ SG_ 1124 PSD_Ges_Geschwindigkeit_Gespann "GiltdieseEinschränkungderGeschwindigkeitfüralleFahrzeugeoderausschließlichfürPKWmitGespannoderfürLKW,Buss,etc.";
CM_ SG_ 1124 PSD_Baum_Breite_VZ "VorzeichenWGS84BreitedesFahrzeugsegments";
CM_ SG_ 1124 PSD_Attribut_4_Wert "WertvonAttribut4";
CM_ SG_ 1124 PSD_Baum_Breite "WGS84BreitedesFahrzeugsegments";
CM_ SG_ 1124 PSD_Ges_Geschwindigkeit_Witter "WitterungsabhängigkeitderGeschwindigkeitsbegrenzung";
CM_ SG_ 1124 PSD_Steigung_1_B_Vorz "VorzeichenfürSteigung1B";
CM_ SG_ 1124 PSD_Steigung_1_B_Offset "PositionsoffsetimSegmentfürdiePositionderSteigung1B";
CM_ SG_ 1124 PSD_Sys_Quali_Geometrien "QualitätderGeometrienindieserRegion";
CM_ SG_ 1124 PSD_Ges_Geschwindigkeit_Tag_Anf "Wochentag,andemdietäglicheGeschwindigkeitsbegrenzungbeginnt";
CM_ SG_ 1124 PSD_Attribut_4_Offset "OffsetvonAttribut4";
CM_ SG_ 1124 PSD_Sys_Quali_Ortsinfo "QualitätOrtsinformationen(Bebauung,Ortsschild)dieserRegion";
CM_ SG_ 1124 PSD_Ges_Geschwindigkeit_Tag_Ende "Wochentag,andemdietäglicheGeschwindigkeitsbegrenzungendet";
CM_ SG_ 1124 PSD_Sys_Quali_verfuegbar "KarteenthältgültigeQualitätskriterien";
CM_ SG_ 1124 PSD_Sys_Zielfuehrung_geaendert "DieZielführung(Route)hatsichgeänderthatohnedassderFahrereineneueZielführunggestartethat";
CM_ SG_ 1124 PSD_Ges_Geschwindigkeit_Std_Anf "Stunde,zuderdiestündlicheGeschwindigkeitsbegrenzungbeginnt
0h.. 24h";
CM_ SG_ 1124 PSD_Steigung_1_Attribute_kompl "AlleSteigungsdatenfürdiesesSegmentgesendet";
CM_ SG_ 1124 PSD_Sys_Geometrieguete_erweitert "GütederKurvenrepräsentationderKlothoiden";
CM_ SG_ 1124 PSD_Steigung_2_Segment_ID "IdentifierdesprädiktivenStreckensegments,zudemderdritteSteigungswertdieserBotschaftgehört";
CM_ SG_ 1124 PSD_Attribut_5_ID "TypvonAttribut5";
CM_ SG_ 1124 PSD_Ges_Geschwindigkeit_Std_Ende "Stunde,anderdiestündlicheGeschwindigkeitsbegrenzungendet
0h.. 24h";
CM_ SG_ 1124 PSD_Attribut_5_Offset "OffsetvonAttribut5";
CM_ SG_ 1124 PSD_Steigung_2_Steigung "SteigungdesSegmentsabOffset2";
CM_ SG_ 1124 PSD_Sys_Quali_sonstige_Attribute "QualitätsonstigerAttributedieserRegion";
CM_ SG_ 1124 PSD_Sys_Quali_Steigungen "QualitätderSteigungendieserRegion";
CM_ SG_ 1124 PSD_Ges_Wechselverkehrszeichen "AmBeginndesSegmentsisteinWechselverkehrszeichenangebracht.";
CM_ SG_ 1124 PSD_Attribut_5_Wert "WertvonAttribut5";
CM_ SG_ 1124 PSD_Steigung_2_Vorz "VorzeichenfürSteigung2";
CM_ SG_ 1124 PSD_Sys_Quali_Strassenkennz "QualitätStraßenkennzeichnungendieserRegion";
CM_ SG_ 1124 PSD_Wechselverkehrszeichen_Typ "TypdesWechselverkehrszeichen";
CM_ SG_ 1124 PSD_Baum_Ausrichtung "AusrichtungdesFahrzeugsegmentszuNord";
CM_ SG_ 1124 PSD_Steigung_2_Offset "PositionsoffsetimSegmentfürdiePositionderSteigung2";
CM_ SG_ 1124 PSD_Ges_Gesetzlich_Kategorie "KategoriefürdaslegaleGebot";
CM_ SG_ 1124 PSD_Sys_Quali_Tempolimits "QualitätTempolimitsdieserRegion";
CM_ SG_ 1124 PSD_Attribute_Komplett_06 "Zeigt,oballeAttributefürdasSegmentübertragenwordensind
";
CM_ SG_ 1124 PSD_Ges_Gesetzlich_Zusatz "ZusatzfürdaslegaleGebot";
CM_ SG_ 1124 PSD_Sys_Quali_Vorfahrtsregelung "QualitätVorfahrtsregelungendieserRegion";
CM_ SG_ 1124 PSD_Ges_Verkehrszeichen_Quelle "QuellederVerkehrszeicheninformation";
CM_ SG_ 1124 PSD_Steigung_2_Attribute_kompl "AlleSteigungsdatenfürdiesesSegmentgesendet";
CM_ SG_ 1124 PSD_Ges_Attribute_Komplett "Zeigt,oballeAttributefürdasSegmentübertragenwordensind";
CM_ SG_ 591 RDR1_relevanter_Fehler "RDR1-SGerkennteinenFehler,mitFSP-Eintrag.";
CM_ SG_ 591 RDR1_Blindheit_erkannt "Blindheitserkennung";
CM_ SG_ 591 RDR1_relev_Nichtverfuegbarkeit "RDR1-SGerkennteinetemporäreNichtverfügbarkeit,ohneFSP-Eintrag";
CM_ SG_ 591 RDR1_Obj_01_Nummer "InterneObjektnummer(Track)";
CM_ SG_ 591 RDR1_Obj_02_Nummer "InterneObjektnummer(Track)";
CM_ SG_ 591 RDR1_Obj_03_Nummer "InterneObjektnummer(Track)";
CM_ SG_ 591 RDR1_Obj_04_Nummer "InterneObjektnummer(Track)";
CM_ SG_ 591 RDR1_Obj_05_Nummer "InterneObjektnummer(Track)";
CM_ SG_ 591 RDR1_Obj_06_Nummer "InterneObjektnummer(Track)";
CM_ SG_ 591 RDR1_Verkehrssinn "vomRadarerkannterVerkehrssinn";
CM_ SG_ 591 RDR1_Objekte_02_Datenalter "DatenalterderObjekteausBotschaftRDR1_Objekte_02";
CM_ SG_ 591 RDR1_Obj_01_dx_v "x-AbstanddesbezüglichdesEgo-Fzg.-MomentankursesdetektiertenObjektdatenblocks";
CM_ SG_ 591 RDR1_Obj_01_dy_v "y-AbstanddesbezüglichdesEgo-Fzg.-MomentankursesdetektiertenObjektdatenblocks";
CM_ SG_ 591 RDR1_Obj_01_vx_v "Relativgeschwindigkeitinx-RichtungdesbezüglichdesEgo-Fzg.MomentankursesdetektiertenObjektes";
CM_ SG_ 591 RDR1_Obj_02_dx_v "x-AbstanddesbezüglichdesEgo-Fzg.-MomentankursesdetektiertenObjektdatenblocks";
CM_ SG_ 591 RDR1_Obj_02_dy_v "y-AbstanddesbezüglichdesEgo-Fzg.-MomentankursesdetektiertenObjektdatenblocks";
CM_ SG_ 591 RDR1_Obj_02_vx_v "Relativgeschwindigkeitinx-RichtungdesbezüglichdesEgo-Fzg.MomentankursesdetektiertenObjektes";
CM_ SG_ 591 RDR1_Obj_03_dx_v "x-AbstanddesbezüglichdesEgo-Fzg.-MomentankursesdetektiertenObjektdatenblocks";
CM_ SG_ 591 RDR1_Obj_03_dy_v "y-AbstanddesbezüglichdesEgo-Fzg.-MomentankursesdetektiertenObjektdatenblocks";
CM_ SG_ 591 RDR1_Obj_03_vx_v "Relativgeschwindigkeitinx-RichtungdesbezüglichdesEgo-Fzg.MomentankursesdetektiertenObjektes";
CM_ SG_ 591 RDR1_Obj_04_dx_v "x-AbstanddesbezüglichdesEgo-Fzg.-MomentankursesdetektiertenObjektdatenblocks";
CM_ SG_ 591 RDR1_Obj_04_dy_v "y-AbstanddesbezüglichdesEgo-Fzg.-MomentankursesdetektiertenObjektdatenblocks";
CM_ SG_ 591 RDR1_Obj_04_vx_v "Relativgeschwindigkeitinx-RichtungdesbezüglichdesEgo-Fzg.MomentankursesdetektiertenObjektes";
CM_ SG_ 591 RDR1_Obj_05_dx_v "x-AbstanddesbezüglichdesEgo-Fzg.-MomentankursesdetektiertenObjektdatenblocks";
CM_ SG_ 591 RDR1_Obj_05_dy_v "y-AbstanddesbezüglichdesEgo-Fzg.-MomentankursesdetektiertenObjektdatenblocks";
CM_ SG_ 591 RDR1_Obj_05_vx_v "Relativgeschwindigkeitinx-RichtungdesbezüglichdesEgo-Fzg.MomentankursesdetektiertenObjektes";
CM_ SG_ 591 RDR1_Obj_06_dx_v "x-AbstanddesbezüglichdesEgo-Fzg.-MomentankursesdetektiertenObjektdatenblocks";
CM_ SG_ 591 RDR1_Obj_06_dy_v "y-AbstanddesbezüglichdesEgo-Fzg.-MomentankursesdetektiertenObjektdatenblocks";
CM_ SG_ 591 RDR1_Obj_06_vx_v "Relativgeschwindigkeitinx-RichtungdesbezüglichdesEgo-Fzg.MomentankursesdetektiertenObjektes";
CM_ SG_ 591 RDR1_Obj_01_ax_v "Relativbeschleunigunginx-RichtungdesbezüglichdesEgo-Fzg.MomentankursesdetektiertenObjektes";
CM_ SG_ 591 RDR1_Obj_01_ax_StdA "StandardabweichungderRelativbeschleunigunginx-RichtungdesbezüglichdesEgo-Fzg.MomentankursesdetektiertenObjektes";
CM_ SG_ 591 RDR1_Obj_01_vx_StdA "StandardabweichungderRelativgeschwindigkeitinx-RichtungdesbezüglichdesEgo-Fzg.MomentankursesdetektiertenObjektes";
CM_ SG_ 591 RDR1_Obj_01_dx_StdA "Standardabweichungdesx-AbstandsdesbezüglichdesEgo-Fzg.-MomentankursesdetektiertenObjektdatenblocks";
CM_ SG_ 591 RDR1_Obj_01_dy_StdA "Standardabweichungdesy-AbstandsdesbezüglichdesEgo-Fzg.-MomentankursesdetektiertenObjektdatenblocks";
CM_ SG_ 2033 Request_Airbag_Deployment "RequestfürdieDisposalDiagnose(ISO26021)";
CM_ SG_ 2041 Response_Airbag_Deployment "ResponsefürdieDisposalDiagnose(ISO26021)";
CM_ SG_ 980 SMLS_01_CRC "FürMLB:
'Berechnung siehe Lastenheft 'Kommunikationsabsicherung für FlexRay und CAN''

Ab MQB und MLBevo:
'Berechnung siehe Lastenheft 'End-to-End Kommunikationsabsicherung''

Endwerte siehe Begleitdokument 'S-PDU Kennungsfolgen'";
CM_ SG_ 980 SMLS_01_BZ "4bitBotschaftszaehler,wirdmitjederSendebotschaftinkrementiert";
CM_ SG_ 980 BH_Blinker_li "BlinkerhebelRichtunglinks
";
CM_ SG_ 980 BH_Blinker_re "BlinkerhebelRichtungrechts
";
CM_ SG_ 980 BH_Lichthupe "BetaetigungLichthupe
";
CM_ SG_ 980 BH_Fernlicht "BetaetigungFernlicht
";
CM_ SG_ 980 WH_Tipwischen "Wischerhebel:Tippwischen

MQB A0/ PQ26: Bei Verbau LSS (kein SMLS): gespiegelter Wert zu Signal WH_WischerStufe1";
CM_ SG_ 980 WH_Intervall "Wischerhebel:StellungIntervall
";
CM_ SG_ 980 WH_WischerStufe1 "Wischerhebel:StufeWischen1
";
CM_ SG_ 980 WH_WischerStufe2 "Wischerhebel:StufeWischen2
";
CM_ SG_ 980 WH_Frontwaschen "Wischerhebel:StellungWischWaschvorne
";
CM_ SG_ 980 WH_Heckintervall "Wischerhebel:StellungHeckintervall
";
CM_ SG_ 980 WH_Heckwaschen "Wischerhebel:StellungWischWaschhinten
";
CM_ SG_ 980 WH_Intervallstufen "Wischerhebel:StellungIntervallstufen";
CM_ SG_ 980 FAS_Taster "BetaetigungFASTaster
";
CM_ SG_ 980 FAS_Taster_Fehler "FehlerstatusFASTaster
";
CM_ SG_ 980 SMLS_Hupe "BetaetigungHupe
";
CM_ SG_ 980 LRH_on_off "StatusLenkradheizung";
CM_ SG_ 980 LSS_Tastencode "0x00=Nokeypressed/keyreleased
0x01 = Menu
0x02 = Menu Up / Next Screen
0x03 = Menu Down / Previous Screen
0x04 = Up
0x05 = Down
0x06 = Up / Down ThumbWheel
0x07 = OK (ThumbWheel-Button)
0x08 = Cancel / Escape
0x09..0x0F = reserved for furt";
CM_ SG_ 980 LRH_aktiv "Signalgibtan,obeinHeizstromdurchdieLenkradheizungfließt.EsdientderAuswertungdurchdasEnergiemanagement.";
CM_ SG_ 980 SMLS_P_verriegelt "SignalstelltdenStatusdesSignalsP-verriegeltaufdenFahrzeugbuszurVerfügung.Nutzersindz.B.dieELV,diedasSignalfürdieVerriegelungbenötigtunddieFunktionVerlassenswarnung,diedenFahrerbeimVerrollendesFahrzeugswarnt.";
CM_ SG_ 980 SMLS_P_verriegelt_plausibel "SignalstelltdenPlausibilisierungstatusdesSignalsp_verriegeltaufdenFahrzeugbuszurVerfügung.EinePlausibilitätmussexpliziterkanntwerden.Initialwird'unplausibel'gesendet.EinplausiblesSignalwirderkannt,wennp_verriegeltplausibelgeg";
CM_ SG_ 980 WH_SRA "Scheinwerferreinigungsanlage

derzeit nur bei PAG umgesetzt";
CM_ SG_ 980 WH_Wischer_Fehler "Anzeige,obamLenkstockschaltereinFehleranliegt.
Notwendig aufgrund ASIL-Einstufung";
CM_ SG_ 980 BH_Blinker_Fehler "Anzeige,obamLenkstockschaltereinFehleranliegt.
Notwendig aufgrund ASIL-Einstufung";
CM_ SG_ 980 SMLS_PTT "BetaetigungPTT";
CM_ SG_ 980 WH_Tipwischen_lang "Wischerhebel:Tippwischenlang
(dient zur Auswertung für die Unterscheidung Tippwischen oder Serviceposition Wischer)";
CM_ SG_ 2464153718 SOK_FoD_MO_01_Req_Challenge "ChallengeimRahmendesSOKChallenge-ResponseProtokolls.

Geschützte Funktion: Function on Demand";
CM_ SG_ 2464284790 SOK_FoD_MO_01_Resp_Challenge "ChallengeimRahmendesSOKChallenge-ResponseProtokolls.

Geschützte Funktion: Function on Demand";
CM_ SG_ 1413 SI_Sammel_SG_Fehler "AnzahldergesetztenKD-FehlerdirektangeschlossenerSteuergerätederDK3undDK4gemäß80127.
Hinweis: Ein Subbusmaster stellt nur die gesammelte Information der an ihn angeschlossenen Steuergeräte der DK3 und DK4 zur Verfügung.

Für ServiceKey Auswe";
CM_ SG_ 1413 SI_P_Mode_gueltig "zeigtan,obessichumeinFahrzeugmitzentraleroderdezentralerSteu-erungdesProduktionsmodeshandelt
Siehe Q-LAH Produktionsmode (LAH.DUM.907.AS)";
CM_ SG_ 1413 SI_Diagnose_Aktiv "GibtanobDiagnose-BotschaftenempfangenwerdenundsomiteineDiagnoseaktivist.
MQB: Gibt an ob Diagnose-Bus Botschaften empfangen werden und somit eine Diagnose aktiv ist.";
CM_ SG_ 1413 SI_T_Mode "0x0:Transportmodusnichtaktiv
0x1: Transportmodus aktiv";
CM_ SG_ 1413 SI_NWDF "Netzwerk-DiagnoseFreigebezurzentralenAktivierungderNetzwerkdiagnose";
CM_ SG_ 1413 SI_NWDF_gueltig "GültigkeitsbitzuSI_NWDFgemäßLastenheft:ZentraleAktivierungNetzwerkdiagnose";
CM_ SG_ 1413 SI_Sammelfehler "SammelfehlermeldungzurAnzeigeimKombi-sieheSpez.Sammelfehlermeldung
Hinweis: Einzelne Steuergeräte können zur Anpassung an den Produktionsprozess im Gateway auskodiert werden!";
CM_ SG_ 1413 GW_KD_Fehler "KundendienstfehlerbitGatewayzurAnzeigeeinesimGatewayabgelegtenFehlerspeichereintrages.";
CM_ SG_ 1413 SI_T_Schutz "Transportschutz-Signal,dasbeiTransportmodusundMotorlaufaktivbleibt
0x0: Transportschutz nicht aktiv
0x1: Transportschutz aktiv";
CM_ SG_ 1413 SI_P_Mode "ZentraleSteuerungdesProduktionsmodesgemäßQ-LAH-Produktionsmode(LAH.DUM.907.AS)";
CM_ SG_ 1413 SI_BUS_01 "MQB/MQB_A0/PQ26:ACAN
MQB2020: ACAN(FD)
MLBevo: HCAN
MEB: ACAN(FD)";
CM_ SG_ 1413 SI_BUS_02 "MQB/MQBA0Standard+,High:FCAN
MQB2020: FCAN(FD)
MLBevo: Frei
MEB: FCAN(FD)";
CM_ SG_ 1413 SI_BUS_03 "MQB/MQBA0/PQ26:KCAN
MQB2020: KCAN
MLBevo: KCAN
MEB: KCAN";
CM_ SG_ 1413 SI_BUS_04 "MQB/MQBA0Standard+,High:ICAN
MQB2020: ICAN
MLBevo: ICAN
MEB: ABCAN(FD)";
CM_ SG_ 1413 SI_BUS_05 "MQB/MQBA0/PQ26:DiagCAN
MQB2020: DiagCAN(FD)
MLBevo: DiagCAN
MEB: DiagCAN(FD)";
CM_ SG_ 1413 SI_BUS_06 "MQB/MQBA0/PQ26:ECAN
MQB2020: FASCAN(FD)
MLBevo: ECAN
MEB: FASCAN(FD)";
CM_ SG_ 1413 SI_BUS_07 "MQB:LIN1(Energie)
MQB2020: LIN1 (Energie)
MLBevo: LIN1 (Energie)";
CM_ SG_ 1413 SI_BUS_08 "MQB:LIN2(MFL)
MQB2020: LIN2 (MFL)
MLBevo: LIN2 (MFL)";
CM_ SG_ 1413 SI_BUS_09 "MQB:LIN3(unbelegt)
MQB2020: LIN3 (Uhr/FES)
MLBevo: LIN3 (Energie2)";
CM_ SG_ 1413 SI_BUS_10 "MLBevo:Flexray

MQB2020: MCAN";
CM_ SG_ 1413 SI_BUS_11 "MLBevo:Ethernet";
CM_ SG_ 1413 SI_BUS_12 "MQB:unbelegt
MLBevo: K2CAN";
CM_ SG_ 1413 SI_BUS_13 "MQB:unbelegt
MLBevo: DCAN
MEB: CCAN";
CM_ SG_ 1413 SI_BUS_14 "MQB/MQBA0:unbelegt
MQB2020: HCAN
MLBevo: CCAN
MEB: EVCAN(FD)";
CM_ SG_ 1413 SI_BUS_15 "MQB:frei
MQB2020: frei
MLBevo: frei
MEB: AFSCAN";
CM_ SG_ 1413 SI_Bus_Identifikation "DasSignalidentifiziertdenBuseindeutig.DasSignalistkonstantaufjedemBus.
Der Signalwert entspricht dem Wert 'Busnummer' aus der VW80127 Gateway_component_list_databus_identification (0x2A2D) 'Bus-Identifier'.";
CM_ SG_ 1413 SI_CAB_V10 "CAB=Clusteraktivbits(V10)";
CM_ SG_ 2589283396 TSK_vMax_EfficiencyMode1 "GlobalesLimitimEffizienz1Fahrprofil/Fahrmodus(e.g.'ECO').";
CM_ SG_ 2589283396 TSK_vMax_EfficiencyMode2 "GlobalesLimitimEfficiency2Fahrprofil/Fahrprogramm(e.g.'ECO+'oder'Rangeplus').";
CM_ SG_ 2589283396 TSK_vMax_StandardMode "GlobalesLimitimStandardFahrprofil/FahrprogrammModus(e.g.'normal'oder'comfort').";
BA_DEF_ BO_ "DiagRequest" ENUM "No", "Yes";
BA_DEF_ BO_ "DiagResponse" ENUM "No", "Yes";
BA_DEF_ BO_ "DiagState" ENUM "No", "Yes";
BA_DEF_ BO_ "GenMsgChkConstant" HEX 0 4095;
BA_DEF_ BO_ "GenMsgCycleTime" INT 0 65535;
BA_DEF_ BO_ "GenMsgCycleTimeFast" INT 0 65535;
BA_DEF_ BO_ "GenMsgDelayTime" INT 0 100000;
BA_DEF_ BO_ "GenMsgILSupport" ENUM "No", "Yes";
BA_DEF_ BO_ "GenMsgNrOfRepetition" INT 0 100;
BA_DEF_ BO_ "GenMsgPDUConstants" STRING;
BA_DEF_ BO_ "GenMsgSendType" ENUM "Cyclic", "not_used", "not_used", "not_used", "not_used", "not_used", "not_used", "IfActive", "NoMsgSendType";
BA_DEF_ BO_ "GenMsgStartDelayTime" INT 0 100000;
BA_DEF_ BO_ "NmMessage" ENUM "No", "Yes";
BA_DEF_ BO_ "NmhMessage" ENUM "No", "Yes";
BA_DEF_ BO_ "MsgType" ENUM "Application", "NM", "NMH", "TP2.0", "ISO-TP", "BAP", "EID", "KS";
BA_DEF_ BO_ "VAGTP20_API" HEX 0 255;
BA_DEF_ BO_ "VAGTP20_DynConnection" ENUM "No", "Yes";
BA_DEF_ BO_ "VAGTP20_DynSetup" ENUM "No", "Yes";
BA_DEF_ BO_ "VAGTP20_StatConnection" ENUM "No", "Yes";
BA_DEF_ BO_ "CANFD_BRS" ENUM "0", "1";
BA_DEF_ BO_ "VFrameFormat" ENUM "StandardCAN", "ExtendedCAN", "reserved", "reserved", "reserved", "reserved", "reserved", "reserved", "reserved", "reserved", "reserved", "reserved", "reserved", "reserved", "StandardCAN_FD", "ExtendedCAN_FD";
BA_DEF_ SG_ "GenSigActiveRepetitions" INT -2147483648 2147483647;
BA_DEF_ SG_ "GenSigInactiveValue" INT -2147483648 2147483647;
BA_DEF_ SG_ "GenSigSendType" ENUM "Cyclic", "OnWrite", "OnWriteWithRepetition", "OnChange", "OnChangeWithRepetition", "IfActive", "IfActiveWithRepetition", "NoSigSendType", "OnChangeAndIfActive", "OnChangeAndIfActiveWithRepetition";
BA_DEF_ SG_ "GenSigStartValue" INT -2147483648 2147483647;
BA_DEF_ SG_ "NWM-WakeupAllowed" ENUM "No", "Yes";
BA_DEF_ SG_ "GenSigFuncType" ENUM "NoFunction", "MsgCounter", "CRC-8", "XOR", "XOR-2", "DatedBit", "SW-Kl15", "CHK", "Constant", "Protocol", "CRC-8-SAE_J1850";
BA_DEF_ SG_ "GenSigSwitchedByIgnition" ENUM "No", "Yes";
BA_DEF_ SG_ "Fehlerwert" HEX 0 2147483647;
BA_DEF_ SG_ "GenSigMissingSourceValue" HEX 0 2147483647;
BA_DEF_DEF_  "DiagRequest" "No";
BA_DEF_DEF_  "DiagResponse" "No";
BA_DEF_DEF_  "DiagState" "No";
BA_DEF_DEF_  "GenMsgChkConstant" 0;
BA_DEF_DEF_  "GenMsgCycleTime" 0;
BA_DEF_DEF_  "GenMsgCycleTimeFast" 0;
BA_DEF_DEF_  "GenMsgDelayTime" 0;
BA_DEF_DEF_  "GenMsgILSupport" "No";
BA_DEF_DEF_  "GenMsgNrOfRepetition" 0;
BA_DEF_DEF_  "GenMsgPDUConstants" "";
BA_DEF_DEF_  "GenMsgSendType" "NoMsgSendType";
BA_DEF_DEF_  "GenMsgStartDelayTime" 0;
BA_DEF_DEF_  "NmMessage" "No";
BA_DEF_DEF_  "NmhMessage" "No";
BA_DEF_DEF_  "MsgType" "Application";
BA_DEF_DEF_  "VAGTP20_API" 0;
BA_DEF_DEF_  "VAGTP20_DynConnection" "No";
BA_DEF_DEF_  "VAGTP20_DynSetup" "No";
BA_DEF_DEF_  "VAGTP20_StatConnection" "No";
BA_DEF_DEF_  "CANFD_BRS" "1";
BA_DEF_DEF_  "VFrameFormat" "StandardCAN";
BA_DEF_DEF_  "GenSigActiveRepetitions" 0;
BA_DEF_DEF_  "GenSigInactiveValue" 0;
BA_DEF_DEF_  "GenSigSendType" "NoSigSendType";
BA_DEF_DEF_  "GenSigStartValue" 0;
BA_DEF_DEF_  "NWM-WakeupAllowed" "No";
BA_DEF_DEF_  "GenSigFuncType" "NoFunction";
BA_DEF_DEF_  "GenSigSwitchedByIgnition" "Yes";
BA_DEF_DEF_  "Fehlerwert" 0;
BA_DEF_DEF_  "GenSigMissingSourceValue" 0;
BA_ "GenMsgCycleTime" BO_ 2600468501 200;
BA_ "GenMsgCycleTimeFast" BO_ 2600468501 10;
BA_ "NmhMessage" BO_ 2600468501 "Yes";
BA_ "MsgType" BO_ 2600468501 "NMH";
BA_ "CANFD_BRS" BO_ 2600468501 "0";
BA_ "VFrameFormat" BO_ 2600468501 "ExtendedCAN";
BA_ "GenMsgCycleTime" BO_ 2600468604 200;
BA_ "GenMsgCycleTimeFast" BO_ 2600468604 10;
BA_ "NmhMessage" BO_ 2600468604 "Yes";
BA_ "MsgType" BO_ 2600468604 "NMH";
BA_ "CANFD_BRS" BO_ 2600468604 "0";
BA_ "VFrameFormat" BO_ 2600468604 "ExtendedCAN";
BA_ "GenMsgCycleTime" BO_ 2600468496 200;
BA_ "GenMsgCycleTimeFast" BO_ 2600468496 10;
BA_ "NmhMessage" BO_ 2600468496 "Yes";
BA_ "MsgType" BO_ 2600468496 "NMH";
BA_ "CANFD_BRS" BO_ 2600468496 "0";
BA_ "VFrameFormat" BO_ 2600468496 "ExtendedCAN";
BA_ "GenMsgCycleTime" BO_ 2600468664 200;
BA_ "GenMsgCycleTimeFast" BO_ 2600468664 10;
BA_ "NmhMessage" BO_ 2600468664 "Yes";
BA_ "MsgType" BO_ 2600468664 "NMH";
BA_ "CANFD_BRS" BO_ 2600468664 "0";
BA_ "VFrameFormat" BO_ 2600468664 "ExtendedCAN";
BA_ "GenMsgCycleTime" BO_ 2600468598 200;
BA_ "GenMsgCycleTimeFast" BO_ 2600468598 10;
BA_ "NmhMessage" BO_ 2600468598 "Yes";
BA_ "MsgType" BO_ 2600468598 "NMH";
BA_ "CANFD_BRS" BO_ 2600468598 "0";
BA_ "VFrameFormat" BO_ 2600468598 "ExtendedCAN";
BA_ "GenMsgCycleTime" BO_ 2600468733 200;
BA_ "GenMsgCycleTimeFast" BO_ 2600468733 10;
BA_ "NmhMessage" BO_ 2600468733 "Yes";
BA_ "MsgType" BO_ 2600468733 "NMH";
BA_ "CANFD_BRS" BO_ 2600468733 "0";
BA_ "VFrameFormat" BO_ 2600468733 "ExtendedCAN";
BA_ "DiagRequest" BO_ 2621440533 "Yes";
BA_ "MsgType" BO_ 2621440533 "ISO-TP";
BA_ "VFrameFormat" BO_ 2621440533 "ExtendedCAN_FD";
BA_ "DiagResponse" BO_ 2621571605 "Yes";
BA_ "MsgType" BO_ 2621571605 "ISO-TP";
BA_ "VFrameFormat" BO_ 2621571605 "ExtendedCAN_FD";
BA_ "DiagRequest" BO_ 2621440636 "Yes";
BA_ "MsgType" BO_ 2621440636 "ISO-TP";
BA_ "VFrameFormat" BO_ 2621440636 "ExtendedCAN_FD";
BA_ "DiagResponse" BO_ 2621571708 "Yes";
BA_ "MsgType" BO_ 2621571708 "ISO-TP";
BA_ "VFrameFormat" BO_ 2621571708 "ExtendedCAN_FD";
BA_ "DiagRequest" BO_ 2621440696 "Yes";
BA_ "MsgType" BO_ 2621440696 "ISO-TP";
BA_ "VFrameFormat" BO_ 2621440696 "ExtendedCAN_FD";
BA_ "DiagResponse" BO_ 2621571768 "Yes";
BA_ "MsgType" BO_ 2621571768 "ISO-TP";
BA_ "VFrameFormat" BO_ 2621571768 "ExtendedCAN_FD";
BA_ "DiagState" BO_ 2621506048 "Yes";
BA_ "MsgType" BO_ 2621506048 "ISO-TP";
BA_ "VFrameFormat" BO_ 2621506048 "ExtendedCAN_FD";
BA_ "DiagRequest" BO_ 2621440630 "Yes";
BA_ "MsgType" BO_ 2621440630 "ISO-TP";
BA_ "VFrameFormat" BO_ 2621440630 "ExtendedCAN_FD";
BA_ "DiagResponse" BO_ 2621571702 "Yes";
BA_ "MsgType" BO_ 2621571702 "ISO-TP";
BA_ "VFrameFormat" BO_ 2621571702 "ExtendedCAN_FD";
BA_ "DiagState" BO_ 2564502513 "Yes";
BA_ "MsgType" BO_ 2564502513 "ISO-TP";
BA_ "VFrameFormat" BO_ 2564502513 "ExtendedCAN_FD";
BA_ "DiagRequest" BO_ 2564425457 "Yes";
BA_ "MsgType" BO_ 2564425457 "ISO-TP";
BA_ "VFrameFormat" BO_ 2564425457 "ExtendedCAN_FD";
BA_ "DiagResponse" BO_ 2564485382 "Yes";
BA_ "MsgType" BO_ 2564485382 "ISO-TP";
BA_ "VFrameFormat" BO_ 2564485382 "ExtendedCAN_FD";
BA_ "DiagRequest" BO_ 2564425713 "Yes";
BA_ "MsgType" BO_ 2564425713 "ISO-TP";
BA_ "VFrameFormat" BO_ 2564425713 "ExtendedCAN_FD";
BA_ "DiagResponse" BO_ 2564485383 "Yes";
BA_ "MsgType" BO_ 2564485383 "ISO-TP";
BA_ "VFrameFormat" BO_ 2564485383 "ExtendedCAN_FD";
BA_ "DiagRequest" BO_ 2564424177 "Yes";
BA_ "MsgType" BO_ 2564424177 "ISO-TP";
BA_ "VFrameFormat" BO_ 2564424177 "ExtendedCAN_FD";
BA_ "DiagResponse" BO_ 2564485377 "Yes";
BA_ "MsgType" BO_ 2564485377 "ISO-TP";
BA_ "VFrameFormat" BO_ 2564485377 "ExtendedCAN_FD";
BA_ "GenMsgCycleTime" BO_ 627 100;
BA_ "GenMsgDelayTime" BO_ 627 10;
BA_ "GenMsgILSupport" BO_ 627 "Yes";
BA_ "GenMsgPDUConstants" BO_ 627 "0xc6,0x40,0x32,0xbe,0xc7,0x76,0x16,0x17,0x05,0xd8,0xab,0x52,0x45,0x35,0xf1,0x1d";
BA_ "GenMsgSendType" BO_ 627 "Cyclic";
BA_ "VFrameFormat" BO_ 627 "StandardCAN_FD";
BA_ "GenMsgCycleTime" BO_ 2463978709 500;
BA_ "GenMsgDelayTime" BO_ 2463978709 50;
BA_ "GenMsgILSupport" BO_ 2463978709 "Yes";
BA_ "GenMsgSendType" BO_ 2463978709 "Cyclic";
BA_ "VFrameFormat" BO_ 2463978709 "ExtendedCAN_FD";
BA_ "GenMsgCycleTime" BO_ 2589283656 500;
BA_ "GenMsgDelayTime" BO_ 2589283656 100;
BA_ "GenMsgILSupport" BO_ 2589283656 "Yes";
BA_ "GenMsgSendType" BO_ 2589283656 "Cyclic";
BA_ "VFrameFormat" BO_ 2589283656 "ExtendedCAN_FD";
BA_ "GenMsgCycleTime" BO_ 2527679741 240;
BA_ "GenMsgILSupport" BO_ 2527679741 "Yes";
BA_ "GenMsgPDUConstants" BO_ 2527679741 "0x9d,0xe8,0x36,0xa1,0xca,0x3b,0x1d,0x33,0xe0,0xd5,0xbb,0x5f,0xae,0x3c,0x31,0x9f";
BA_ "GenMsgSendType" BO_ 2527679741 "Cyclic";
BA_ "VFrameFormat" BO_ 2527679741 "ExtendedCAN_FD";
BA_ "GenMsgCycleTime" BO_ 518 20;
BA_ "GenMsgILSupport" BO_ 518 "Yes";
BA_ "GenMsgSendType" BO_ 518 "Cyclic";
BA_ "VFrameFormat" BO_ 518 "StandardCAN_FD";
BA_ "GenMsgCycleTime" BO_ 2527679685 2000;
BA_ "GenMsgDelayTime" BO_ 2527679685 100;
BA_ "GenMsgILSupport" BO_ 2527679685 "Yes";
BA_ "GenMsgSendType" BO_ 2527679685 "Cyclic";
BA_ "VFrameFormat" BO_ 2527679685 "ExtendedCAN_FD";
BA_ "GenMsgCycleTime" BO_ 319 200;
BA_ "GenMsgDelayTime" BO_ 319 20;
BA_ "GenMsgILSupport" BO_ 319 "Yes";
BA_ "GenMsgSendType" BO_ 319 "Cyclic";
BA_ "CANFD_BRS" BO_ 319 "0";
BA_ "GenMsgCycleTime" BO_ 1122 150;
BA_ "GenMsgILSupport" BO_ 1122 "Yes";
BA_ "GenMsgSendType" BO_ 1122 "Cyclic";
BA_ "VFrameFormat" BO_ 1122 "StandardCAN_FD";
BA_ "GenMsgCycleTime" BO_ 1123 150;
BA_ "GenMsgILSupport" BO_ 1123 "Yes";
BA_ "GenMsgSendType" BO_ 1123 "Cyclic";
BA_ "VFrameFormat" BO_ 1123 "StandardCAN_FD";
BA_ "GenMsgCycleTime" BO_ 1124 150;
BA_ "GenMsgILSupport" BO_ 1124 "Yes";
BA_ "GenMsgSendType" BO_ 1124 "Cyclic";
BA_ "VFrameFormat" BO_ 1124 "StandardCAN_FD";
BA_ "GenMsgCycleTime" BO_ 591 40;
BA_ "GenMsgILSupport" BO_ 591 "Yes";
BA_ "GenMsgSendType" BO_ 591 "Cyclic";
BA_ "VFrameFormat" BO_ 591 "StandardCAN_FD";
BA_ "DiagRequest" BO_ 2033 "Yes";
BA_ "MsgType" BO_ 2033 "ISO-TP";
BA_ "CANFD_BRS" BO_ 2033 "0";
BA_ "DiagResponse" BO_ 2041 "Yes";
BA_ "MsgType" BO_ 2041 "ISO-TP";
BA_ "CANFD_BRS" BO_ 2041 "0";
BA_ "GenMsgCycleTime" BO_ 980 1000;
BA_ "GenMsgCycleTimeFast" BO_ 980 100;
BA_ "GenMsgDelayTime" BO_ 980 50;
BA_ "GenMsgILSupport" BO_ 980 "Yes";
BA_ "GenMsgNrOfRepetition" BO_ 980 5;
BA_ "GenMsgPDUConstants" BO_ 980 "0xc3,0x79,0xbf,0xdb,0xe9,0x11,0x46,0x86,0x69,0xb6,0x9b,0x29,0x15,0x9c,0x45,0x0d";
BA_ "GenMsgSendType" BO_ 980 "Cyclic";
BA_ "VFrameFormat" BO_ 980 "StandardCAN_FD";
BA_ "GenMsgDelayTime" BO_ 2464153718 50;
BA_ "GenMsgILSupport" BO_ 2464153718 "Yes";
BA_ "VFrameFormat" BO_ 2464153718 "ExtendedCAN_FD";
BA_ "GenMsgDelayTime" BO_ 2464284790 50;
BA_ "GenMsgILSupport" BO_ 2464284790 "Yes";
BA_ "VFrameFormat" BO_ 2464284790 "ExtendedCAN_FD";
BA_ "GenMsgCycleTime" BO_ 1413 1000;
BA_ "GenMsgDelayTime" BO_ 1413 10;
BA_ "GenMsgILSupport" BO_ 1413 "Yes";
BA_ "GenMsgSendType" BO_ 1413 "Cyclic";
BA_ "VFrameFormat" BO_ 1413 "StandardCAN_FD";
BA_ "GenMsgCycleTime" BO_ 2589283396 500;
BA_ "GenMsgILSupport" BO_ 2589283396 "Yes";
BA_ "GenMsgSendType" BO_ 2589283396 "Cyclic";
BA_ "VFrameFormat" BO_ 2589283396 "ExtendedCAN_FD";
BA_ "GenSigSwitchedByIgnition" SG_ 2600468501 NM_Airbag_01_CBV_AWB "No";
BA_ "GenSigSwitchedByIgnition" SG_ 2600468501 NM_Airbag_01_CBV_CRI "No";
BA_ "GenSigSwitchedByIgnition" SG_ 2600468501 NM_Airbag_01_NM_State "No";
BA_ "GenSigSwitchedByIgnition" SG_ 2600468501 NM_Airbag_01_Car_Wakeup "No";
BA_ "GenSigSwitchedByIgnition" SG_ 2600468501 NM_Airbag_01_UDS_CC "No";
BA_ "GenSigSwitchedByIgnition" SG_ 2600468501 NM_Airbag_01_NM_aktiv_KL15 "No";
BA_ "GenSigSwitchedByIgnition" SG_ 2600468501 NM_Airbag_01_NM_aktiv_Diagnose "No";
BA_ "GenSigSwitchedByIgnition" SG_ 2600468501 NM_Airbag_01_NM_aktiv_Tmin "No";
BA_ "GenSigSwitchedByIgnition" SG_ 2600468501 NM_Airbag_01_CAB_V10 "No";
BA_ "GenSigSwitchedByIgnition" SG_ 2600468604 NM_EMotor_01_CBV_AWB "No";
BA_ "GenSigSwitchedByIgnition" SG_ 2600468604 NM_EMotor_01_CBV_CRI "No";
BA_ "GenSigSwitchedByIgnition" SG_ 2600468604 NM_EMotor_01_NM_State "No";
BA_ "GenSigSwitchedByIgnition" SG_ 2600468604 NM_EMotor_01_Car_Wakeup "No";
BA_ "GenSigSwitchedByIgnition" SG_ 2600468604 NM_EMotor_01_UDS_CC "No";
BA_ "GenSigSwitchedByIgnition" SG_ 2600468604 NM_EMotor_01_NM_aktiv_KL15 "No";
BA_ "GenSigSwitchedByIgnition" SG_ 2600468604 NM_EMotor_01_NM_aktiv_Diagnose "No";
BA_ "GenSigSwitchedByIgnition" SG_ 2600468604 NM_EMotor_01_NM_aktiv_Tmin "No";
BA_ "GenSigSwitchedByIgnition" SG_ 2600468604 NM_EMotor_01_keine_HV_Entl "No";
BA_ "GenSigSwitchedByIgnition" SG_ 2600468604 NM_EMotor_01_CAB_V10 "No";
BA_ "GenSigSwitchedByIgnition" SG_ 2600468496 NM_Gateway_CBV_AWB "No";
BA_ "GenSigFuncType" SG_ 2600468496 NM_Gateway_CBV_CRI "Constant";
BA_ "GenSigSwitchedByIgnition" SG_ 2600468496 NM_Gateway_CBV_CRI "No";
BA_ "GenSigSwitchedByIgnition" SG_ 2600468496 NM_Gateway_NM_State "No";
BA_ "GenSigSwitchedByIgnition" SG_ 2600468496 NM_Gateway_Car_Wakeup "No";
BA_ "GenSigSwitchedByIgnition" SG_ 2600468496 NM_Gateway_UDS_CC "No";
BA_ "GenSigSwitchedByIgnition" SG_ 2600468496 NM_Gateway_NM_aktiv_KL15 "No";
BA_ "GenSigSwitchedByIgnition" SG_ 2600468496 NM_Gateway_NM_aktiv_Diagnose "No";
BA_ "GenSigSwitchedByIgnition" SG_ 2600468496 NM_Gateway_NM_aktiv_Tmin "No";
BA_ "GenSigSwitchedByIgnition" SG_ 2600468496 NM_Gateway_CAB_V10 "No";
BA_ "GenSigSwitchedByIgnition" SG_ 2600468664 NM_LE2_CBV_AWB "No";
BA_ "GenSigFuncType" SG_ 2600468664 NM_LE2_CBV_CRI "Constant";
BA_ "GenSigSwitchedByIgnition" SG_ 2600468664 NM_LE2_CBV_CRI "No";
BA_ "GenSigSwitchedByIgnition" SG_ 2600468664 NM_LE2_NM_State "No";
BA_ "GenSigSwitchedByIgnition" SG_ 2600468664 NM_LE2_Car_Wakeup "No";
BA_ "GenSigSwitchedByIgnition" SG_ 2600468664 NM_LE2_UDS_CC "No";
BA_ "GenSigSwitchedByIgnition" SG_ 2600468664 NM_LE2_NM_aktiv_KL15 "No";
BA_ "GenSigSwitchedByIgnition" SG_ 2600468664 NM_LE2_NM_aktiv_Diagnose "No";
BA_ "GenSigSwitchedByIgnition" SG_ 2600468664 NM_LE2_NM_aktiv_Tmin "No";
BA_ "GenSigSwitchedByIgnition" SG_ 2600468664 NM_LE2_keine_HV_entl "No";
BA_ "GenSigSwitchedByIgnition" SG_ 2600468664 NM_LE2_CAB_V10 "No";
BA_ "GenSigSwitchedByIgnition" SG_ 2600468598 NM_MO_01_CBV_AWB "No";
BA_ "GenSigFuncType" SG_ 2600468598 NM_MO_01_CBV_CRI "Constant";
BA_ "GenSigSwitchedByIgnition" SG_ 2600468598 NM_MO_01_CBV_CRI "No";
BA_ "GenSigSwitchedByIgnition" SG_ 2600468598 NM_MO_01_NM_State "No";
BA_ "GenSigSwitchedByIgnition" SG_ 2600468598 NM_MO_01_Car_Wakeup "No";
BA_ "GenSigSwitchedByIgnition" SG_ 2600468598 NM_MO_01_UDS_CC "No";
BA_ "GenSigSwitchedByIgnition" SG_ 2600468598 NM_MO_01_NM_aktiv_KL15 "No";
BA_ "GenSigSwitchedByIgnition" SG_ 2600468598 NM_MO_01_NM_aktiv_Diagnose "No";
BA_ "GenSigSwitchedByIgnition" SG_ 2600468598 NM_MO_01_NM_aktiv_Tmin "No";
BA_ "GenSigSwitchedByIgnition" SG_ 2600468598 NM_MO_01_NM_aktiv_Betankung "No";
BA_ "GenSigSwitchedByIgnition" SG_ 2600468598 NM_MO_01_NM_aktiv_Waehlhebel "No";
BA_ "GenSigSwitchedByIgnition" SG_ 2600468598 NM_MO_01_NM_aktiv_HV_Abschaltung "No";
BA_ "GenSigSwitchedByIgnition" SG_ 2600468598 NM_MO_01_NM_aktiv_Hochvolt "No";
BA_ "GenSigSwitchedByIgnition" SG_ 2600468598 NM_MO_01_CAB_V10 "No";
BA_ "GenSigSwitchedByIgnition" SG_ 2600468733 NM_Waehlhebel_CBV_AWB "No";
BA_ "GenSigFuncType" SG_ 2600468733 NM_Waehlhebel_CBV_CRI "Constant";
BA_ "GenSigSwitchedByIgnition" SG_ 2600468733 NM_Waehlhebel_CBV_CRI "No";
BA_ "GenSigSwitchedByIgnition" SG_ 2600468733 NM_Waehlhebel_NM_State "No";
BA_ "GenSigSwitchedByIgnition" SG_ 2600468733 NM_Waehlhebel_Car_Wakeup "No";
BA_ "GenSigSwitchedByIgnition" SG_ 2600468733 NM_Waehlhebel_UDS_CC "No";
BA_ "GenSigSwitchedByIgnition" SG_ 2600468733 NM_Waehlhebel_NM_aktiv_KL15 "No";
BA_ "GenSigSwitchedByIgnition" SG_ 2600468733 NM_Waehlhebel_NM_aktiv_Diagnose "No";
BA_ "GenSigSwitchedByIgnition" SG_ 2600468733 NM_Waehlhebel_NM_aktiv_Tmin "No";
BA_ "GenSigSwitchedByIgnition" SG_ 2600468733 NM_Waehlhebel_CAB_V10 "No";
BA_ "GenSigSendType" SG_ 2621440533 OBDC_Airbag_01_Req_FD_Data "OnChange";
BA_ "GenSigSwitchedByIgnition" SG_ 2621440533 OBDC_Airbag_01_Req_FD_Data "No";
BA_ "GenSigSendType" SG_ 2621571605 OBDC_Airbag_01_Resp_FD_Data "OnChange";
BA_ "GenSigSwitchedByIgnition" SG_ 2621571605 OBDC_Airbag_01_Resp_FD_Data "No";
BA_ "GenSigSendType" SG_ 2621440636 OBDC_EMotor_01_Req_FD_Data "OnChange";
BA_ "GenSigFuncType" SG_ 2621440636 OBDC_EMotor_01_Req_FD_Data "Protocol";
BA_ "GenSigSwitchedByIgnition" SG_ 2621440636 OBDC_EMotor_01_Req_FD_Data "No";
BA_ "GenSigSendType" SG_ 2621571708 OBDC_EMotor_01_Resp_FD_Data "OnChange";
BA_ "GenSigFuncType" SG_ 2621571708 OBDC_EMotor_01_Resp_FD_Data "Protocol";
BA_ "GenSigSwitchedByIgnition" SG_ 2621571708 OBDC_EMotor_01_Resp_FD_Data "No";
BA_ "GenSigSendType" SG_ 2621440696 OBDC_EMotor_02_Req_FD_Data "OnChange";
BA_ "GenSigFuncType" SG_ 2621440696 OBDC_EMotor_02_Req_FD_Data "Protocol";
BA_ "GenSigSwitchedByIgnition" SG_ 2621440696 OBDC_EMotor_02_Req_FD_Data "No";
BA_ "GenSigSendType" SG_ 2621571768 OBDC_EMotor_02_Resp_FD_Data "OnChange";
BA_ "GenSigFuncType" SG_ 2621571768 OBDC_EMotor_02_Resp_FD_Data "Protocol";
BA_ "GenSigSwitchedByIgnition" SG_ 2621571768 OBDC_EMotor_02_Resp_FD_Data "No";
BA_ "GenSigSendType" SG_ 2621506048 OBDC_Funktion_Req_All_FD_Data "OnChange";
BA_ "GenSigFuncType" SG_ 2621506048 OBDC_Funktion_Req_All_FD_Data "Protocol";
BA_ "GenSigSwitchedByIgnition" SG_ 2621506048 OBDC_Funktion_Req_All_FD_Data "No";
BA_ "GenSigSendType" SG_ 2621440630 OBDC_MO_01_Req_FD_Data "OnChange";
BA_ "GenSigFuncType" SG_ 2621440630 OBDC_MO_01_Req_FD_Data "Protocol";
BA_ "GenSigSwitchedByIgnition" SG_ 2621440630 OBDC_MO_01_Req_FD_Data "No";
BA_ "GenSigSendType" SG_ 2621571702 OBDC_MO_01_Resp_FD_Data "OnChange";
BA_ "GenSigFuncType" SG_ 2621571702 OBDC_MO_01_Resp_FD_Data "Protocol";
BA_ "GenSigSwitchedByIgnition" SG_ 2621571702 OBDC_MO_01_Resp_FD_Data "No";
BA_ "GenSigSendType" SG_ 2564502513 OBDx_allOBD_Req_Data "OnChange";
BA_ "GenSigFuncType" SG_ 2564502513 OBDx_allOBD_Req_Data "Protocol";
BA_ "GenSigSwitchedByIgnition" SG_ 2564502513 OBDx_allOBD_Req_Data "No";
BA_ "GenSigSendType" SG_ 2564425457 OBDx_LE1_Req_Data "OnChange";
BA_ "GenSigFuncType" SG_ 2564425457 OBDx_LE1_Req_Data "Protocol";
BA_ "GenSigSwitchedByIgnition" SG_ 2564425457 OBDx_LE1_Req_Data "No";
BA_ "GenSigSendType" SG_ 2564485382 OBDx_LE1_Resp_Data "OnChange";
BA_ "GenSigFuncType" SG_ 2564485382 OBDx_LE1_Resp_Data "Protocol";
BA_ "GenSigSwitchedByIgnition" SG_ 2564485382 OBDx_LE1_Resp_Data "No";
BA_ "GenSigSendType" SG_ 2564425713 OBDx_LE2_Req_Data "OnChange";
BA_ "GenSigFuncType" SG_ 2564425713 OBDx_LE2_Req_Data "Protocol";
BA_ "GenSigSwitchedByIgnition" SG_ 2564425713 OBDx_LE2_Req_Data "No";
BA_ "GenSigSendType" SG_ 2564485383 OBDx_LE2_Resp_Data "OnChange";
BA_ "GenSigFuncType" SG_ 2564485383 OBDx_LE2_Resp_Data "Protocol";
BA_ "GenSigSwitchedByIgnition" SG_ 2564485383 OBDx_LE2_Resp_Data "No";
BA_ "GenSigSendType" SG_ 2564424177 OBDx_MO_01_Req_Data "OnChange";
BA_ "GenSigSwitchedByIgnition" SG_ 2564424177 OBDx_MO_01_Req_Data "No";
BA_ "GenSigSendType" SG_ 2564485377 OBDx_MO_01_Resp_Data "OnChange";
BA_ "GenSigSwitchedByIgnition" SG_ 2564485377 OBDx_MO_01_Resp_Data "No";
BA_ "GenSigSendType" SG_ 627 OCC_01_CRC "Cyclic";
BA_ "GenSigFuncType" SG_ 627 OCC_01_CRC "CRC-8";
BA_ "GenSigSwitchedByIgnition" SG_ 627 OCC_01_CRC "No";
BA_ "GenSigSendType" SG_ 627 OCC_01_BZ "Cyclic";
BA_ "GenSigFuncType" SG_ 627 OCC_01_BZ "MsgCounter";
BA_ "GenSigSwitchedByIgnition" SG_ 627 OCC_01_BZ "No";
BA_ "GenSigSendType" SG_ 627 OCC_Stecker_Status "Cyclic";
BA_ "GenSigSwitchedByIgnition" SG_ 627 OCC_Stecker_Status "No";
BA_ "Fehlerwert" SG_ 627 OCC_Stecker_Status 3;
BA_ "GenSigSendType" SG_ 627 OCC_Status_Spgfreiheit "Cyclic";
BA_ "GenSigSwitchedByIgnition" SG_ 627 OCC_Status_Spgfreiheit "No";
BA_ "Fehlerwert" SG_ 627 OCC_Status_Spgfreiheit 3;
BA_ "GenSigSendType" SG_ 627 OCC_DC_IstStrom "Cyclic";
BA_ "GenSigStartValue" SG_ 627 OCC_DC_IstStrom 2046;
BA_ "GenSigSwitchedByIgnition" SG_ 627 OCC_DC_IstStrom "No";
BA_ "Fehlerwert" SG_ 627 OCC_DC_IstStrom 2047;
BA_ "GenSigSendType" SG_ 627 OCC_CC_Latchstatus_DC_GBT "OnChange";
BA_ "GenSigStartValue" SG_ 627 OCC_CC_Latchstatus_DC_GBT 6;
BA_ "GenSigSwitchedByIgnition" SG_ 627 OCC_CC_Latchstatus_DC_GBT "No";
BA_ "Fehlerwert" SG_ 627 OCC_CC_Latchstatus_DC_GBT 7;
BA_ "GenSigSendType" SG_ 627 OCC_Status_EoHVL "Cyclic";
BA_ "GenSigSwitchedByIgnition" SG_ 627 OCC_Status_EoHVL "No";
BA_ "Fehlerwert" SG_ 627 OCC_Status_EoHVL 3;
BA_ "GenSigSendType" SG_ 627 OCC_I_istAC_Netz_L1 "Cyclic";
BA_ "GenSigStartValue" SG_ 627 OCC_I_istAC_Netz_L1 510;
BA_ "GenSigSwitchedByIgnition" SG_ 627 OCC_I_istAC_Netz_L1 "No";
BA_ "Fehlerwert" SG_ 627 OCC_I_istAC_Netz_L1 511;
BA_ "GenSigSendType" SG_ 627 OCC_PP_Latchstatus_A "OnChange";
BA_ "GenSigStartValue" SG_ 627 OCC_PP_Latchstatus_A 6;
BA_ "GenSigSwitchedByIgnition" SG_ 627 OCC_PP_Latchstatus_A "No";
BA_ "Fehlerwert" SG_ 627 OCC_PP_Latchstatus_A 7;
BA_ "GenSigSendType" SG_ 627 OCC_PP_Latchstatus_B "OnChange";
BA_ "GenSigStartValue" SG_ 627 OCC_PP_Latchstatus_B 6;
BA_ "GenSigSwitchedByIgnition" SG_ 627 OCC_PP_Latchstatus_B "No";
BA_ "Fehlerwert" SG_ 627 OCC_PP_Latchstatus_B 7;
BA_ "GenSigSendType" SG_ 627 OCC_I_istAC_Netz_L2 "Cyclic";
BA_ "GenSigStartValue" SG_ 627 OCC_I_istAC_Netz_L2 510;
BA_ "GenSigSwitchedByIgnition" SG_ 627 OCC_I_istAC_Netz_L2 "No";
BA_ "Fehlerwert" SG_ 627 OCC_I_istAC_Netz_L2 511;
BA_ "GenSigSendType" SG_ 627 OCC_I_istAC_Netz_L3 "Cyclic";
BA_ "GenSigStartValue" SG_ 627 OCC_I_istAC_Netz_L3 510;
BA_ "GenSigSwitchedByIgnition" SG_ 627 OCC_I_istAC_Netz_L3 "No";
BA_ "Fehlerwert" SG_ 627 OCC_I_istAC_Netz_L3 511;
BA_ "GenSigSendType" SG_ 627 OCC_IstModus "Cyclic";
BA_ "GenSigStartValue" SG_ 627 OCC_IstModus 6;
BA_ "GenSigSwitchedByIgnition" SG_ 627 OCC_IstModus "No";
BA_ "Fehlerwert" SG_ 627 OCC_IstModus 7;
BA_ "GenSigSendType" SG_ 627 OCC_CP_Status_A "OnChange";
BA_ "GenSigStartValue" SG_ 627 OCC_CP_Status_A 2;
BA_ "GenSigSwitchedByIgnition" SG_ 627 OCC_CP_Status_A "No";
BA_ "Fehlerwert" SG_ 627 OCC_CP_Status_A 3;
BA_ "GenSigSendType" SG_ 627 OCC_CP_Status_B "OnChange";
BA_ "GenSigStartValue" SG_ 627 OCC_CP_Status_B 2;
BA_ "GenSigSwitchedByIgnition" SG_ 627 OCC_CP_Status_B "No";
BA_ "Fehlerwert" SG_ 627 OCC_CP_Status_B 3;
BA_ "GenSigSendType" SG_ 627 OCC_IstSpannung_HV "Cyclic";
BA_ "GenSigStartValue" SG_ 627 OCC_IstSpannung_HV 1022;
BA_ "GenSigSwitchedByIgnition" SG_ 627 OCC_IstSpannung_HV "No";
BA_ "Fehlerwert" SG_ 627 OCC_IstSpannung_HV 1023;
BA_ "GenSigSendType" SG_ 627 OCC_PP_Status_A "OnChange";
BA_ "GenSigStartValue" SG_ 627 OCC_PP_Status_A 2;
BA_ "GenSigSwitchedByIgnition" SG_ 627 OCC_PP_Status_A "No";
BA_ "Fehlerwert" SG_ 627 OCC_PP_Status_A 3;
BA_ "GenSigSendType" SG_ 627 OCC_PP_Status_B "OnChange";
BA_ "GenSigStartValue" SG_ 627 OCC_PP_Status_B 2;
BA_ "GenSigSwitchedByIgnition" SG_ 627 OCC_PP_Status_B "No";
BA_ "Fehlerwert" SG_ 627 OCC_PP_Status_B 3;
BA_ "GenSigSendType" SG_ 627 OCC_CC_Status_DC_GBT "OnChange";
BA_ "GenSigStartValue" SG_ 627 OCC_CC_Status_DC_GBT 2;
BA_ "GenSigSwitchedByIgnition" SG_ 627 OCC_CC_Status_DC_GBT "No";
BA_ "Fehlerwert" SG_ 627 OCC_CC_Status_DC_GBT 3;
BA_ "GenSigSendType" SG_ 627 OCC_CC_Fehlerstatus_DC_GBT "Cyclic";
BA_ "GenSigSwitchedByIgnition" SG_ 627 OCC_CC_Fehlerstatus_DC_GBT "No";
BA_ "GenSigSendType" SG_ 627 OCC_Temp_Sensor_Fehlerstatus_DC "OnChange";
BA_ "GenSigSwitchedByIgnition" SG_ 627 OCC_Temp_Sensor_Fehlerstatus_DC "No";
BA_ "GenSigSendType" SG_ 627 OCC_Temp_Sensor_Fehlerstatus_AC "OnChange";
BA_ "GenSigSwitchedByIgnition" SG_ 627 OCC_Temp_Sensor_Fehlerstatus_AC "No";
BA_ "GenSigSendType" SG_ 627 OCC_Temp_Sensor_Status "Cyclic";
BA_ "GenSigSwitchedByIgnition" SG_ 627 OCC_Temp_Sensor_Status "No";
BA_ "GenSigSendType" SG_ 2463978709 OCC_CP_Tastgrad_A "OnChange";
BA_ "GenSigStartValue" SG_ 2463978709 OCC_CP_Tastgrad_A 1022;
BA_ "GenSigSwitchedByIgnition" SG_ 2463978709 OCC_CP_Tastgrad_A "No";
BA_ "Fehlerwert" SG_ 2463978709 OCC_CP_Tastgrad_A 1023;
BA_ "GenSigSendType" SG_ 2463978709 OCC_CP_Tastgrad_B "OnChange";
BA_ "GenSigStartValue" SG_ 2463978709 OCC_CP_Tastgrad_B 1022;
BA_ "GenSigSwitchedByIgnition" SG_ 2463978709 OCC_CP_Tastgrad_B "No";
BA_ "Fehlerwert" SG_ 2463978709 OCC_CP_Tastgrad_B 1023;
BA_ "GenSigSendType" SG_ 2463978709 OCC_CP_Frequenz_A "OnChange";
BA_ "GenSigStartValue" SG_ 2463978709 OCC_CP_Frequenz_A 254;
BA_ "GenSigSwitchedByIgnition" SG_ 2463978709 OCC_CP_Frequenz_A "No";
BA_ "Fehlerwert" SG_ 2463978709 OCC_CP_Frequenz_A 255;
BA_ "GenSigSendType" SG_ 2463978709 OCC_CP_Frequenz_B "OnChange";
BA_ "GenSigStartValue" SG_ 2463978709 OCC_CP_Frequenz_B 254;
BA_ "GenSigSwitchedByIgnition" SG_ 2463978709 OCC_CP_Frequenz_B "No";
BA_ "Fehlerwert" SG_ 2463978709 OCC_CP_Frequenz_B 255;
BA_ "GenSigSendType" SG_ 2463978709 OCC_CP_Spannung_A "OnChange";
BA_ "GenSigStartValue" SG_ 2463978709 OCC_CP_Spannung_A 510;
BA_ "GenSigSwitchedByIgnition" SG_ 2463978709 OCC_CP_Spannung_A "No";
BA_ "Fehlerwert" SG_ 2463978709 OCC_CP_Spannung_A 511;
BA_ "GenSigSendType" SG_ 2463978709 OCC_CP_Spannung_B "OnChange";
BA_ "GenSigStartValue" SG_ 2463978709 OCC_CP_Spannung_B 510;
BA_ "GenSigSwitchedByIgnition" SG_ 2463978709 OCC_CP_Spannung_B "No";
BA_ "Fehlerwert" SG_ 2463978709 OCC_CP_Spannung_B 511;
BA_ "GenSigSendType" SG_ 2463978709 OCC_CP_Fehlerstatus_A "OnChange";
BA_ "GenSigStartValue" SG_ 2463978709 OCC_CP_Fehlerstatus_A 4;
BA_ "GenSigSwitchedByIgnition" SG_ 2463978709 OCC_CP_Fehlerstatus_A "No";
BA_ "GenSigSendType" SG_ 2463978709 OCC_CP_Fehlerstatus_B "OnChange";
BA_ "GenSigStartValue" SG_ 2463978709 OCC_CP_Fehlerstatus_B 4;
BA_ "GenSigSwitchedByIgnition" SG_ 2463978709 OCC_CP_Fehlerstatus_B "No";
BA_ "GenSigSendType" SG_ 2463978709 OCC_Temp_Ladedose_A_AC "Cyclic";
BA_ "GenSigStartValue" SG_ 2463978709 OCC_Temp_Ladedose_A_AC 254;
BA_ "GenSigSwitchedByIgnition" SG_ 2463978709 OCC_Temp_Ladedose_A_AC "No";
BA_ "Fehlerwert" SG_ 2463978709 OCC_Temp_Ladedose_A_AC 255;
BA_ "GenSigSendType" SG_ 2463978709 OCC_Temp_Ladedose_A_DC_minus "Cyclic";
BA_ "GenSigStartValue" SG_ 2463978709 OCC_Temp_Ladedose_A_DC_minus 254;
BA_ "GenSigSwitchedByIgnition" SG_ 2463978709 OCC_Temp_Ladedose_A_DC_minus "No";
BA_ "Fehlerwert" SG_ 2463978709 OCC_Temp_Ladedose_A_DC_minus 255;
BA_ "GenSigSendType" SG_ 2463978709 OCC_Temp_Ladedose_A_DC_plus "Cyclic";
BA_ "GenSigStartValue" SG_ 2463978709 OCC_Temp_Ladedose_A_DC_plus 254;
BA_ "GenSigSwitchedByIgnition" SG_ 2463978709 OCC_Temp_Ladedose_A_DC_plus "No";
BA_ "Fehlerwert" SG_ 2463978709 OCC_Temp_Ladedose_A_DC_plus 255;
BA_ "GenSigSendType" SG_ 2463978709 OCC_U_istAC_Netz_L1 "Cyclic";
BA_ "GenSigStartValue" SG_ 2463978709 OCC_U_istAC_Netz_L1 510;
BA_ "GenSigSwitchedByIgnition" SG_ 2463978709 OCC_U_istAC_Netz_L1 "No";
BA_ "Fehlerwert" SG_ 2463978709 OCC_U_istAC_Netz_L1 511;
BA_ "GenSigSendType" SG_ 2463978709 OCC_U_istAC_Netz_L2 "Cyclic";
BA_ "GenSigStartValue" SG_ 2463978709 OCC_U_istAC_Netz_L2 510;
BA_ "GenSigSwitchedByIgnition" SG_ 2463978709 OCC_U_istAC_Netz_L2 "No";
BA_ "Fehlerwert" SG_ 2463978709 OCC_U_istAC_Netz_L2 511;
BA_ "GenSigSendType" SG_ 2463978709 OCC_U_istAC_Netz_L3 "Cyclic";
BA_ "GenSigStartValue" SG_ 2463978709 OCC_U_istAC_Netz_L3 510;
BA_ "GenSigSwitchedByIgnition" SG_ 2463978709 OCC_U_istAC_Netz_L3 "No";
BA_ "Fehlerwert" SG_ 2463978709 OCC_U_istAC_Netz_L3 511;
BA_ "GenSigSendType" SG_ 2463978709 OCC_StatusVerEntriegelungAktor_A "OnChange";
BA_ "GenSigStartValue" SG_ 2463978709 OCC_StatusVerEntriegelungAktor_A 6;
BA_ "GenSigSwitchedByIgnition" SG_ 2463978709 OCC_StatusVerEntriegelungAktor_A "No";
BA_ "Fehlerwert" SG_ 2463978709 OCC_StatusVerEntriegelungAktor_A 7;
BA_ "GenSigSendType" SG_ 2463978709 OCC_SteckerEntriegelung_Verbot_A "OnChange";
BA_ "GenSigStartValue" SG_ 2463978709 OCC_SteckerEntriegelung_Verbot_A 3;
BA_ "GenSigSwitchedByIgnition" SG_ 2463978709 OCC_SteckerEntriegelung_Verbot_A "No";
BA_ "GenSigSendType" SG_ 2463978709 OCC_StatusVerEntriegelungAktor_B "OnChange";
BA_ "GenSigStartValue" SG_ 2463978709 OCC_StatusVerEntriegelungAktor_B 6;
BA_ "GenSigSwitchedByIgnition" SG_ 2463978709 OCC_StatusVerEntriegelungAktor_B "No";
BA_ "Fehlerwert" SG_ 2463978709 OCC_StatusVerEntriegelungAktor_B 7;
BA_ "GenSigSendType" SG_ 2463978709 OCC_SteckerEntriegelung_Verbot_B "OnChange";
BA_ "GenSigStartValue" SG_ 2463978709 OCC_SteckerEntriegelung_Verbot_B 3;
BA_ "GenSigSwitchedByIgnition" SG_ 2463978709 OCC_SteckerEntriegelung_Verbot_B "No";
BA_ "GenSigSendType" SG_ 2463978709 OCC_Verriegelung_Status_A "OnChange";
BA_ "GenSigStartValue" SG_ 2463978709 OCC_Verriegelung_Status_A 6;
BA_ "GenSigSwitchedByIgnition" SG_ 2463978709 OCC_Verriegelung_Status_A "No";
BA_ "Fehlerwert" SG_ 2463978709 OCC_Verriegelung_Status_A 7;
BA_ "GenSigSendType" SG_ 2463978709 OCC_Verriegelung_Status_B "OnChange";
BA_ "GenSigStartValue" SG_ 2463978709 OCC_Verriegelung_Status_B 6;
BA_ "GenSigSwitchedByIgnition" SG_ 2463978709 OCC_Verriegelung_Status_B "No";
BA_ "Fehlerwert" SG_ 2463978709 OCC_Verriegelung_Status_B 7;
BA_ "GenSigSendType" SG_ 2463978709 OCC_RtmWarnLadeKommunikation "Cyclic";
BA_ "GenSigSwitchedByIgnition" SG_ 2463978709 OCC_RtmWarnLadeKommunikation "No";
BA_ "GenSigSendType" SG_ 2463978709 OCC_Ist_Wirkungsgrad "Cyclic";
BA_ "GenSigStartValue" SG_ 2463978709 OCC_Ist_Wirkungsgrad 126;
BA_ "GenSigSwitchedByIgnition" SG_ 2463978709 OCC_Ist_Wirkungsgrad "No";
BA_ "Fehlerwert" SG_ 2463978709 OCC_Ist_Wirkungsgrad 127;
BA_ "GenSigSendType" SG_ 2463978709 OCC_PP_Max_Strom_A "OnChange";
BA_ "GenSigStartValue" SG_ 2463978709 OCC_PP_Max_Strom_A 8;
BA_ "GenSigSwitchedByIgnition" SG_ 2463978709 OCC_PP_Max_Strom_A "No";
BA_ "Fehlerwert" SG_ 2463978709 OCC_PP_Max_Strom_A 9;
BA_ "GenSigSendType" SG_ 2463978709 OCC_PP_Max_Strom_B "OnChange";
BA_ "GenSigStartValue" SG_ 2463978709 OCC_PP_Max_Strom_B 8;
BA_ "GenSigSwitchedByIgnition" SG_ 2463978709 OCC_PP_Max_Strom_B "No";
BA_ "Fehlerwert" SG_ 2463978709 OCC_PP_Max_Strom_B 9;
BA_ "GenSigSendType" SG_ 2463978709 OCC_DC_MaxStrom "OnChange";
BA_ "GenSigStartValue" SG_ 2463978709 OCC_DC_MaxStrom 2046;
BA_ "GenSigSwitchedByIgnition" SG_ 2463978709 OCC_DC_MaxStrom "No";
BA_ "Fehlerwert" SG_ 2463978709 OCC_DC_MaxStrom 2047;
BA_ "GenSigSendType" SG_ 2463978709 OCC_Derating_Temperatur "Cyclic";
BA_ "GenSigSwitchedByIgnition" SG_ 2463978709 OCC_Derating_Temperatur "No";
BA_ "GenSigSendType" SG_ 2463978709 OCC_Fehlerzustand "Cyclic";
BA_ "GenSigSwitchedByIgnition" SG_ 2463978709 OCC_Fehlerzustand "No";
BA_ "GenSigSendType" SG_ 2463978709 OCC_Ladest_Entriegelungs_Verbot "OnChange";
BA_ "GenSigStartValue" SG_ 2463978709 OCC_Ladest_Entriegelungs_Verbot 6;
BA_ "GenSigSwitchedByIgnition" SG_ 2463978709 OCC_Ladest_Entriegelungs_Verbot "No";
BA_ "Fehlerwert" SG_ 2463978709 OCC_Ladest_Entriegelungs_Verbot 7;
BA_ "GenSigSendType" SG_ 2463978709 OCC_Netzfrequenz_EVU "Cyclic";
BA_ "GenSigStartValue" SG_ 2463978709 OCC_Netzfrequenz_EVU 510;
BA_ "GenSigSwitchedByIgnition" SG_ 2463978709 OCC_Netzfrequenz_EVU "No";
BA_ "Fehlerwert" SG_ 2463978709 OCC_Netzfrequenz_EVU 511;
BA_ "GenSigSendType" SG_ 2463978709 OCC_Warnzustand "Cyclic";
BA_ "GenSigSwitchedByIgnition" SG_ 2463978709 OCC_Warnzustand "No";
BA_ "GenSigSendType" SG_ 2463978709 OCC_Kuehltemperatur "Cyclic";
BA_ "GenSigStartValue" SG_ 2463978709 OCC_Kuehltemperatur 254;
BA_ "GenSigSwitchedByIgnition" SG_ 2463978709 OCC_Kuehltemperatur "No";
BA_ "Fehlerwert" SG_ 2463978709 OCC_Kuehltemperatur 255;
BA_ "GenSigSendType" SG_ 2463978709 OCC_PP_Fehlerstatus_A "OnChange";
BA_ "GenSigStartValue" SG_ 2463978709 OCC_PP_Fehlerstatus_A 8;
BA_ "GenSigSwitchedByIgnition" SG_ 2463978709 OCC_PP_Fehlerstatus_A "No";
BA_ "GenSigSendType" SG_ 2463978709 OCC_PP_Fehlerstatus_B "OnChange";
BA_ "GenSigStartValue" SG_ 2463978709 OCC_PP_Fehlerstatus_B 8;
BA_ "GenSigSwitchedByIgnition" SG_ 2463978709 OCC_PP_Fehlerstatus_B "No";
BA_ "GenSigSendType" SG_ 2589283656 ORU_EM_Anfrage_freigegebeneNetze "OnChange";
BA_ "GenSigSwitchedByIgnition" SG_ 2589283656 ORU_EM_Anfrage_freigegebeneNetze "No";
BA_ "GenSigSendType" SG_ 2589283656 ORU_EM_Anfrage_Stromaufnahme "OnChange";
BA_ "GenSigSwitchedByIgnition" SG_ 2589283656 ORU_EM_Anfrage_Stromaufnahme "No";
BA_ "GenSigSendType" SG_ 2589283656 ORU_EM_Anfrage_Flashdauer "OnChange";
BA_ "GenSigSwitchedByIgnition" SG_ 2589283656 ORU_EM_Anfrage_Flashdauer "No";
BA_ "GenSigSendType" SG_ 2589283656 ORU_Warnung "OnChange";
BA_ "GenSigSwitchedByIgnition" SG_ 2589283656 ORU_Warnung "No";
BA_ "GenSigSendType" SG_ 2589283656 ORU_Status "OnChange";
BA_ "GenSigSwitchedByIgnition" SG_ 2589283656 ORU_Status "No";
BA_ "GenSigSendType" SG_ 2527679741 PAO_Status_01_CRC "Cyclic";
BA_ "GenSigFuncType" SG_ 2527679741 PAO_Status_01_CRC "CRC-8";
BA_ "GenSigSwitchedByIgnition" SG_ 2527679741 PAO_Status_01_CRC "No";
BA_ "GenSigSendType" SG_ 2527679741 PAO_Status_01_BZ "Cyclic";
BA_ "GenSigFuncType" SG_ 2527679741 PAO_Status_01_BZ "MsgCounter";
BA_ "GenSigSwitchedByIgnition" SG_ 2527679741 PAO_Status_01_BZ "No";
BA_ "GenSigSendType" SG_ 2527679741 PAO_ON_Status "Cyclic";
BA_ "GenSigSwitchedByIgnition" SG_ 2527679741 PAO_ON_Status "No";
BA_ "GenSigSendType" SG_ 2527679741 PAO_OFF_Status "Cyclic";
BA_ "GenSigSwitchedByIgnition" SG_ 2527679741 PAO_OFF_Status "No";
BA_ "GenSigSendType" SG_ 2527679741 PAO_Status_Reserve_Byte3 "Cyclic";
BA_ "GenSigSwitchedByIgnition" SG_ 2527679741 PAO_Status_Reserve_Byte3 "No";
BA_ "GenSigSendType" SG_ 518 Parken_BKD_Anf "Cyclic";
BA_ "GenSigStartValue" SG_ 518 Parken_BKD_Anf 14;
BA_ "GenSigSwitchedByIgnition" SG_ 518 Parken_BKD_Anf "No";
BA_ "Fehlerwert" SG_ 518 Parken_BKD_Anf 15;
BA_ "GenSigSendType" SG_ 518 Parken_Verz_Anf "Cyclic";
BA_ "GenSigStartValue" SG_ 518 Parken_Verz_Anf 126;
BA_ "GenSigSwitchedByIgnition" SG_ 518 Parken_Verz_Anf "No";
BA_ "GenSigSendType" SG_ 518 Parken_Prefill_Anf "Cyclic";
BA_ "GenSigSwitchedByIgnition" SG_ 518 Parken_Prefill_Anf "No";
BA_ "GenSigSendType" SG_ 518 Parken_Warnruck_Anf "Cyclic";
BA_ "GenSigSwitchedByIgnition" SG_ 518 Parken_Warnruck_Anf "No";
BA_ "GenSigSendType" SG_ 518 Parken_Verz_Anf_ASIL "Cyclic";
BA_ "GenSigSwitchedByIgnition" SG_ 518 Parken_Verz_Anf_ASIL "No";
BA_ "GenSigSendType" SG_ 518 Parken_Warnruckeln_Anf "Cyclic";
BA_ "GenSigSwitchedByIgnition" SG_ 518 Parken_Warnruckeln_Anf "No";
BA_ "GenSigSendType" SG_ 518 Parken_beibehalten "Cyclic";
BA_ "GenSigStartValue" SG_ 518 Parken_beibehalten 2;
BA_ "GenSigSwitchedByIgnition" SG_ 518 Parken_beibehalten "No";
BA_ "Fehlerwert" SG_ 518 Parken_beibehalten 3;
BA_ "GenSigSendType" SG_ 518 Parken_Anforderung_HMS "Cyclic";
BA_ "GenSigSwitchedByIgnition" SG_ 518 Parken_Anforderung_HMS "No";
BA_ "GenSigSendType" SG_ 518 Parken_Notstopp_Anf "Cyclic";
BA_ "GenSigSwitchedByIgnition" SG_ 518 Parken_Notstopp_Anf "No";
BA_ "GenSigSendType" SG_ 518 Parken_Anhalteweg_Anf "Cyclic";
BA_ "GenSigStartValue" SG_ 518 Parken_Anhalteweg_Anf 1022;
BA_ "GenSigSwitchedByIgnition" SG_ 518 Parken_Anhalteweg_Anf "No";
BA_ "Fehlerwert" SG_ 518 Parken_Anhalteweg_Anf 1023;
BA_ "GenSigSendType" SG_ 518 Parken_aktives_System "Cyclic";
BA_ "GenSigSendType" SG_ 518 Parken_max_Beschleunigung "Cyclic";
BA_ "GenSigStartValue" SG_ 518 Parken_max_Beschleunigung 122;
BA_ "GenSigSwitchedByIgnition" SG_ 518 Parken_max_Beschleunigung "No";
BA_ "Fehlerwert" SG_ 518 Parken_max_Beschleunigung 127;
BA_ "GenSigSendType" SG_ 518 Parken_Blinker_li_Anf "Cyclic";
BA_ "GenSigSwitchedByIgnition" SG_ 518 Parken_Blinker_li_Anf "No";
BA_ "GenSigSendType" SG_ 518 Parken_QFK_KruemmSoll "Cyclic";
BA_ "GenSigSendType" SG_ 518 Parken_QFK_KruemmSoll_VZ "Cyclic";
BA_ "GenSigSendType" SG_ 518 Parken_QFK_Spuerb "Cyclic";
BA_ "GenSigSendType" SG_ 518 Parken_QFK_AnfStat "Cyclic";
BA_ "GenSigStartValue" SG_ 518 Parken_QFK_AnfStat 1;
BA_ "GenSigSendType" SG_ 518 Parken_QFK_Signal1 "Cyclic";
BA_ "GenSigSendType" SG_ 518 Parken_QFK_Art1 "Cyclic";
BA_ "GenSigSendType" SG_ 518 Parken_QFK_Art2 "Cyclic";
BA_ "GenSigSendType" SG_ 518 Parken_QFK_Signal2 "Cyclic";
BA_ "GenSigSendType" SG_ 518 Parken_Sollbeschleunigung "Cyclic";
BA_ "GenSigSendType" SG_ 518 Parken_Blinker_re_Anf "Cyclic";
BA_ "GenSigSwitchedByIgnition" SG_ 518 Parken_Blinker_re_Anf "No";
BA_ "GenSigSendType" SG_ 518 Parken_Status_IPA_TSK "Cyclic";
BA_ "GenSigStartValue" SG_ 518 Parken_Status_IPA_TSK 1;
BA_ "GenSigSwitchedByIgnition" SG_ 518 Parken_Status_IPA_TSK "No";
BA_ "GenSigSendType" SG_ 518 Parken_erhoehtes_Moment "Cyclic";
BA_ "GenSigSwitchedByIgnition" SG_ 518 Parken_erhoehtes_Moment "No";
BA_ "GenSigSendType" SG_ 518 Parken_max_Geschwindigkeit "Cyclic";
BA_ "GenSigStartValue" SG_ 518 Parken_max_Geschwindigkeit 251;
BA_ "GenSigSwitchedByIgnition" SG_ 518 Parken_max_Geschwindigkeit "No";
BA_ "Fehlerwert" SG_ 518 Parken_max_Geschwindigkeit 255;
BA_ "GenSigSendType" SG_ 518 Parken_Soll_Anhalteweg_Anf "Cyclic";
BA_ "GenSigStartValue" SG_ 518 Parken_Soll_Anhalteweg_Anf 1022;
BA_ "GenSigSwitchedByIgnition" SG_ 518 Parken_Soll_Anhalteweg_Anf "No";
BA_ "Fehlerwert" SG_ 518 Parken_Soll_Anhalteweg_Anf 1023;
BA_ "GenSigSendType" SG_ 518 Parken_Fahrstufenwunsch "Cyclic";
BA_ "GenSigSendType" SG_ 518 IPA_TPA_Remote "Cyclic";
BA_ "GenSigSwitchedByIgnition" SG_ 518 IPA_TPA_Remote "No";
BA_ "GenSigSendType" SG_ 518 IPA_TPA_Remote_Anf "Cyclic";
BA_ "GenSigSwitchedByIgnition" SG_ 518 IPA_TPA_Remote_Anf "No";
BA_ "GenSigSendType" SG_ 518 IPA_TPA_Fehler "Cyclic";
BA_ "GenSigSwitchedByIgnition" SG_ 518 IPA_TPA_Fehler "No";
BA_ "GenSigSendType" SG_ 518 IPA_TPA_Abbruch "Cyclic";
BA_ "GenSigSwitchedByIgnition" SG_ 518 IPA_TPA_Abbruch "No";
BA_ "GenSigSendType" SG_ 518 IPA_TPA_Status "Cyclic";
BA_ "GenSigStartValue" SG_ 518 IPA_TPA_Status 1;
BA_ "GenSigSwitchedByIgnition" SG_ 518 IPA_TPA_Status "No";
BA_ "GenSigSendType" SG_ 2527679685 PDC_ASM_Ereignis "OnChange";
BA_ "GenSigSendType" SG_ 2527679685 PDC_ASM_Zeitstempel "OnChange";
BA_ "GenSigStartValue" SG_ 2527679685 PDC_ASM_Zeitstempel 255;
BA_ "GenSigSendType" SG_ 2527679685 PDC_ASM_Data_1 "Cyclic";
BA_ "GenSigSendType" SG_ 2527679685 PDC_ASM_Data_2 "Cyclic";
BA_ "GenSigSendType" SG_ 2527679685 PDC_ASM_Data_3 "Cyclic";
BA_ "GenSigSendType" SG_ 2527679685 PDC_ASM_Data_4 "Cyclic";
BA_ "GenSigSendType" SG_ 2527679685 PDC_ASM_Data_5 "Cyclic";
BA_ "GenSigSendType" SG_ 2527679685 PDC_ASM_Data_6 "Cyclic";
BA_ "GenSigSendType" SG_ 319 PreCrash_Charisma_FahrPr "Cyclic";
BA_ "GenSigSendType" SG_ 319 PreCrash_Charisma_Status "Cyclic";
BA_ "GenSigSendType" SG_ 319 PreCrash_Schiebedach_schliessen "OnChange";
BA_ "GenSigSendType" SG_ 319 PreCrash_Fenster_schliessen "OnChange";
BA_ "GenSigSendType" SG_ 319 PreCrash_Blinken "OnChange";
BA_ "GenSigSendType" SG_ 319 SC_PreSense_FCWP "OnChange";
BA_ "GenSigSwitchedByIgnition" SG_ 319 SC_PreSense_FCWP "No";
BA_ "GenSigSendType" SG_ 319 PreCrash_Tueren_Verriegeln "OnChange";
BA_ "GenSigSwitchedByIgnition" SG_ 319 PreCrash_Tueren_Verriegeln "No";
BA_ "GenSigSendType" SG_ 319 PreCrash_FS_Laengsverstellung "OnChange";
BA_ "GenSigSwitchedByIgnition" SG_ 319 PreCrash_FS_Laengsverstellung "No";
BA_ "GenSigSendType" SG_ 319 PreCrash_Anforderung_AFR "OnChange";
BA_ "GenSigStartValue" SG_ 319 PreCrash_Anforderung_AFR 7;
BA_ "GenSigSwitchedByIgnition" SG_ 319 PreCrash_Anforderung_AFR "No";
BA_ "GenSigSendType" SG_ 319 SC_PreCrash_LED "OnChange";
BA_ "GenSigSwitchedByIgnition" SG_ 319 SC_PreCrash_LED "No";
BA_ "GenSigSendType" SG_ 319 PreCrash_FS_Pneumatik_ansteuern "OnChange";
BA_ "GenSigSwitchedByIgnition" SG_ 319 PreCrash_FS_Pneumatik_ansteuern "No";
BA_ "GenSigSendType" SG_ 319 PreCrash_BFS_Pneumatik_ansteuern "OnChange";
BA_ "GenSigSwitchedByIgnition" SG_ 319 PreCrash_BFS_Pneumatik_ansteuern "No";
BA_ "GenSigSendType" SG_ 319 PreCrash_Fo_Pneumatik_ansteuern "OnChange";
BA_ "GenSigSwitchedByIgnition" SG_ 319 PreCrash_Fo_Pneumatik_ansteuern "No";
BA_ "GenSigSendType" SG_ 319 PreCrash_FS_Sitzlehne_verfahren "OnChange";
BA_ "GenSigSwitchedByIgnition" SG_ 319 PreCrash_FS_Sitzlehne_verfahren "No";
BA_ "GenSigSendType" SG_ 319 PreCrash_BFS_Sitzlehne_verfahren "OnChange";
BA_ "GenSigSwitchedByIgnition" SG_ 319 PreCrash_BFS_Sitzlehne_verfahren "No";
BA_ "GenSigSendType" SG_ 319 PreCrash_Fo_Sitzlehne_verfahren "OnChange";
BA_ "GenSigSwitchedByIgnition" SG_ 319 PreCrash_Fo_Sitzlehne_verfahren "No";
BA_ "GenSigSendType" SG_ 319 PreCrash_FS_KSV_verfahren "OnChange";
BA_ "GenSigSwitchedByIgnition" SG_ 319 PreCrash_FS_KSV_verfahren "No";
BA_ "GenSigSendType" SG_ 319 PreCrash_BFS_KSV_verfahren "OnChange";
BA_ "GenSigSwitchedByIgnition" SG_ 319 PreCrash_BFS_KSV_verfahren "No";
BA_ "GenSigSendType" SG_ 319 PreCrash_Fo_KSV_verfahren "OnChange";
BA_ "GenSigSwitchedByIgnition" SG_ 319 PreCrash_Fo_KSV_verfahren "No";
BA_ "GenSigSendType" SG_ 319 PreCrash_BFS_Laengsverstellung "OnChange";
BA_ "GenSigSwitchedByIgnition" SG_ 319 PreCrash_BFS_Laengsverstellung "No";
BA_ "GenSigSendType" SG_ 319 SC_PreCrash_Warnung "OnChange";
BA_ "GenSigSwitchedByIgnition" SG_ 319 SC_PreCrash_Warnung "No";
BA_ "GenSigSendType" SG_ 319 SC_PreCrash_Texte "OnChange";
BA_ "GenSigSwitchedByIgnition" SG_ 319 SC_PreCrash_Texte "No";
BA_ "GenSigSendType" SG_ 1122 PSD_Segment_ID "Cyclic";
BA_ "GenSigSendType" SG_ 1122 PSD_Vorgaenger_Segment_ID "Cyclic";
BA_ "GenSigSendType" SG_ 1122 PSD_Segmentlaenge "Cyclic";
BA_ "GenSigSendType" SG_ 1122 PSD_Strassenkategorie "Cyclic";
BA_ "GenSigStartValue" SG_ 1122 PSD_Strassenkategorie 7;
BA_ "GenSigSwitchedByIgnition" SG_ 1122 PSD_Strassenkategorie "No";
BA_ "GenSigSendType" SG_ 1122 PSD_Endkruemmung "Cyclic";
BA_ "GenSigSendType" SG_ 1122 PSD_Endkruemmung_Vorz "Cyclic";
BA_ "GenSigSendType" SG_ 1122 PSD_Idenditaets_ID "Cyclic";
BA_ "Fehlerwert" SG_ 1122 PSD_Idenditaets_ID 1;
BA_ "GenSigSendType" SG_ 1122 PSD_ADAS_Qualitaet "Cyclic";
BA_ "GenSigSendType" SG_ 1122 PSD_wahrscheinlichster_Pfad "Cyclic";
BA_ "GenSigSendType" SG_ 1122 PSD_Geradester_Pfad "Cyclic";
BA_ "GenSigSendType" SG_ 1122 PSD_Fahrspuren_Anzahl "Cyclic";
BA_ "GenSigStartValue" SG_ 1122 PSD_Fahrspuren_Anzahl 1;
BA_ "GenSigSwitchedByIgnition" SG_ 1122 PSD_Fahrspuren_Anzahl "No";
BA_ "GenSigSendType" SG_ 1122 PSD_Bebauung "Cyclic";
BA_ "GenSigSendType" SG_ 1122 PSD_Segment_Komplett "Cyclic";
BA_ "GenSigSwitchedByIgnition" SG_ 1122 PSD_Segment_Komplett "No";
BA_ "GenSigSendType" SG_ 1122 PSD_Rampe "Cyclic";
BA_ "GenSigSendType" SG_ 1122 PSD_Anfangskruemmung "Cyclic";
BA_ "GenSigSwitchedByIgnition" SG_ 1122 PSD_Anfangskruemmung "No";
BA_ "GenSigSendType" SG_ 1122 PSD_Anfangskruemmung_Vorz "Cyclic";
BA_ "GenSigSwitchedByIgnition" SG_ 1122 PSD_Anfangskruemmung_Vorz "No";
BA_ "GenSigSendType" SG_ 1122 PSD_Abzweigerichtung "Cyclic";
BA_ "GenSigSwitchedByIgnition" SG_ 1122 PSD_Abzweigerichtung "No";
BA_ "GenSigSendType" SG_ 1122 PSD_Abzweigewinkel "Cyclic";
BA_ "GenSigSwitchedByIgnition" SG_ 1122 PSD_Abzweigewinkel "No";
BA_ "GenSigSendType" SG_ 1123 PSD_Pos_Segment_ID "Cyclic";
BA_ "GenSigSendType" SG_ 1123 PSD_Pos_Segmentlaenge "Cyclic";
BA_ "GenSigSendType" SG_ 1123 PSD_Pos_Inhibitzeit "Cyclic";
BA_ "GenSigSendType" SG_ 1123 PSD_Pos_Standort_Eindeutig "Cyclic";
BA_ "GenSigSwitchedByIgnition" SG_ 1123 PSD_Pos_Standort_Eindeutig "No";
BA_ "GenSigSendType" SG_ 1123 PSD_Pos_Fehler_Laengsrichtung "Cyclic";
BA_ "GenSigSendType" SG_ 1123 PSD_Pos_Fahrspur "Cyclic";
BA_ "GenSigSendType" SG_ 1123 PSD_Attribut_Segment_ID_05 "Cyclic";
BA_ "Fehlerwert" SG_ 1123 PSD_Attribut_Segment_ID_05 1;
BA_ "GenSigSendType" SG_ 1123 PSD_Attribut_1_ID "Cyclic";
BA_ "GenSigSendType" SG_ 1123 PSD_Attribut_1_Wert "Cyclic";
BA_ "GenSigSendType" SG_ 1123 PSD_Attribut_1_Offset "Cyclic";
BA_ "GenSigSendType" SG_ 1123 PSD_Attribut_2_ID "Cyclic";
BA_ "GenSigSendType" SG_ 1123 PSD_Attribut_2_Wert "Cyclic";
BA_ "GenSigSendType" SG_ 1123 PSD_Attribut_2_Offset "Cyclic";
BA_ "GenSigSendType" SG_ 1123 PSD_Attribute_Komplett_05 "Cyclic";
BA_ "GenSigSendType" SG_ 1124 PSD_06_Mux "Cyclic";
BA_ "NWM-WakeupAllowed" SG_ 1124 PSD_06_Mux "Yes";
BA_ "GenSigSwitchedByIgnition" SG_ 1124 PSD_06_Mux "No";
BA_ "Fehlerwert" SG_ 1124 PSD_Attribut_Segment_ID 1;
BA_ "Fehlerwert" SG_ 1124 PSD_Steigung_1_Segment_ID 1;
BA_ "GenSigStartValue" SG_ 1124 PSD_Ges_Typ 3;
BA_ "GenSigSwitchedByIgnition" SG_ 1124 PSD_Ges_Typ "No";
BA_ "GenSigSwitchedByIgnition" SG_ 1124 PSD_Steigung_1_Attribute_kompl "No";
BA_ "Fehlerwert" SG_ 1124 PSD_Steigung_2_Segment_ID 1;
BA_ "GenSigSwitchedByIgnition" SG_ 1124 PSD_Attribute_Komplett_06 "No";
BA_ "GenSigSwitchedByIgnition" SG_ 1124 PSD_Steigung_2_Attribute_kompl "No";
BA_ "GenSigSendType" SG_ 591 RDR1_relevanter_Fehler "Cyclic";
BA_ "GenSigSendType" SG_ 591 RDR1_Blindheit_erkannt "Cyclic";
BA_ "GenSigSendType" SG_ 591 RDR1_relev_Nichtverfuegbarkeit "Cyclic";
BA_ "GenSigSendType" SG_ 591 RDR1_Obj_01_Nummer "Cyclic";
BA_ "GenSigSendType" SG_ 591 RDR1_Obj_02_Nummer "Cyclic";
BA_ "GenSigSendType" SG_ 591 RDR1_Obj_03_Nummer "Cyclic";
BA_ "GenSigSendType" SG_ 591 RDR1_Obj_04_Nummer "Cyclic";
BA_ "GenSigSendType" SG_ 591 RDR1_Obj_05_Nummer "Cyclic";
BA_ "GenSigSendType" SG_ 591 RDR1_Obj_06_Nummer "Cyclic";
BA_ "GenSigSendType" SG_ 591 RDR1_Verkehrssinn "Cyclic";
BA_ "GenSigSendType" SG_ 591 RDR1_Objekte_02_Datenalter "Cyclic";
BA_ "GenSigSendType" SG_ 591 RDR1_Obj_01_dx_v "Cyclic";
BA_ "GenSigSendType" SG_ 591 RDR1_Obj_01_dy_v "Cyclic";
BA_ "GenSigStartValue" SG_ 591 RDR1_Obj_01_dy_v 512;
BA_ "GenSigSendType" SG_ 591 RDR1_Obj_01_vx_v "Cyclic";
BA_ "GenSigStartValue" SG_ 591 RDR1_Obj_01_vx_v 512;
BA_ "GenSigSendType" SG_ 591 RDR1_Obj_02_dx_v "Cyclic";
BA_ "GenSigSendType" SG_ 591 RDR1_Obj_02_dy_v "Cyclic";
BA_ "GenSigStartValue" SG_ 591 RDR1_Obj_02_dy_v 512;
BA_ "GenSigSendType" SG_ 591 RDR1_Obj_02_vx_v "Cyclic";
BA_ "GenSigStartValue" SG_ 591 RDR1_Obj_02_vx_v 512;
BA_ "GenSigSendType" SG_ 591 RDR1_Obj_03_dx_v "Cyclic";
BA_ "GenSigSendType" SG_ 591 RDR1_Obj_03_dy_v "Cyclic";
BA_ "GenSigStartValue" SG_ 591 RDR1_Obj_03_dy_v 512;
BA_ "GenSigSendType" SG_ 591 RDR1_Obj_03_vx_v "Cyclic";
BA_ "GenSigStartValue" SG_ 591 RDR1_Obj_03_vx_v 512;
BA_ "GenSigSendType" SG_ 591 RDR1_Obj_04_dx_v "Cyclic";
BA_ "GenSigSendType" SG_ 591 RDR1_Obj_04_dy_v "Cyclic";
BA_ "GenSigStartValue" SG_ 591 RDR1_Obj_04_dy_v 512;
BA_ "GenSigSendType" SG_ 591 RDR1_Obj_04_vx_v "Cyclic";
BA_ "GenSigStartValue" SG_ 591 RDR1_Obj_04_vx_v 512;
BA_ "GenSigSendType" SG_ 591 RDR1_Obj_05_dx_v "Cyclic";
BA_ "GenSigSendType" SG_ 591 RDR1_Obj_05_dy_v "Cyclic";
BA_ "GenSigStartValue" SG_ 591 RDR1_Obj_05_dy_v 512;
BA_ "GenSigSendType" SG_ 591 RDR1_Obj_05_vx_v "Cyclic";
BA_ "GenSigStartValue" SG_ 591 RDR1_Obj_05_vx_v 512;
BA_ "GenSigSendType" SG_ 591 RDR1_Obj_06_dx_v "Cyclic";
BA_ "GenSigSendType" SG_ 591 RDR1_Obj_06_dy_v "Cyclic";
BA_ "GenSigStartValue" SG_ 591 RDR1_Obj_06_dy_v 512;
BA_ "GenSigSendType" SG_ 591 RDR1_Obj_06_vx_v "Cyclic";
BA_ "GenSigStartValue" SG_ 591 RDR1_Obj_06_vx_v 512;
BA_ "GenSigSendType" SG_ 591 RDR1_Obj_01_ax_v "Cyclic";
BA_ "GenSigStartValue" SG_ 591 RDR1_Obj_01_ax_v 255;
BA_ "GenSigSwitchedByIgnition" SG_ 591 RDR1_Obj_01_ax_v "No";
BA_ "GenSigSendType" SG_ 591 RDR1_Obj_01_ax_StdA "Cyclic";
BA_ "GenSigStartValue" SG_ 591 RDR1_Obj_01_ax_StdA 63;
BA_ "GenSigSwitchedByIgnition" SG_ 591 RDR1_Obj_01_ax_StdA "No";
BA_ "GenSigSendType" SG_ 591 RDR1_Obj_01_vx_StdA "Cyclic";
BA_ "GenSigStartValue" SG_ 591 RDR1_Obj_01_vx_StdA 127;
BA_ "GenSigSwitchedByIgnition" SG_ 591 RDR1_Obj_01_vx_StdA "No";
BA_ "GenSigSendType" SG_ 591 RDR1_Obj_01_dx_StdA "Cyclic";
BA_ "GenSigStartValue" SG_ 591 RDR1_Obj_01_dx_StdA 127;
BA_ "GenSigSwitchedByIgnition" SG_ 591 RDR1_Obj_01_dx_StdA "No";
BA_ "GenSigSendType" SG_ 591 RDR1_Obj_01_dy_StdA "Cyclic";
BA_ "GenSigStartValue" SG_ 591 RDR1_Obj_01_dy_StdA 127;
BA_ "GenSigSendType" SG_ 980 SMLS_01_CRC "Cyclic";
BA_ "GenSigFuncType" SG_ 980 SMLS_01_CRC "CRC-8";
BA_ "GenSigSwitchedByIgnition" SG_ 980 SMLS_01_CRC "No";
BA_ "GenSigSendType" SG_ 980 SMLS_01_BZ "Cyclic";
BA_ "GenSigFuncType" SG_ 980 SMLS_01_BZ "MsgCounter";
BA_ "GenSigSwitchedByIgnition" SG_ 980 SMLS_01_BZ "No";
BA_ "GenSigSendType" SG_ 980 BH_Blinker_li "OnChangeWithRepetition";
BA_ "GenSigSwitchedByIgnition" SG_ 980 BH_Blinker_li "No";
BA_ "GenSigSendType" SG_ 980 BH_Blinker_re "OnChangeWithRepetition";
BA_ "GenSigSwitchedByIgnition" SG_ 980 BH_Blinker_re "No";
BA_ "GenSigSendType" SG_ 980 BH_Lichthupe "OnChangeWithRepetition";
BA_ "GenSigSwitchedByIgnition" SG_ 980 BH_Lichthupe "No";
BA_ "GenSigSendType" SG_ 980 BH_Fernlicht "OnChange";
BA_ "GenSigSwitchedByIgnition" SG_ 980 BH_Fernlicht "No";
BA_ "GenSigSendType" SG_ 980 WH_Tipwischen "OnChangeWithRepetition";
BA_ "GenSigSwitchedByIgnition" SG_ 980 WH_Tipwischen "No";
BA_ "GenSigSendType" SG_ 980 WH_Intervall "OnChange";
BA_ "GenSigSwitchedByIgnition" SG_ 980 WH_Intervall "No";
BA_ "GenSigSendType" SG_ 980 WH_WischerStufe1 "OnChange";
BA_ "GenSigSwitchedByIgnition" SG_ 980 WH_WischerStufe1 "No";
BA_ "GenSigSendType" SG_ 980 WH_WischerStufe2 "OnChange";
BA_ "GenSigSwitchedByIgnition" SG_ 980 WH_WischerStufe2 "No";
BA_ "GenSigSendType" SG_ 980 WH_Frontwaschen "OnChange";
BA_ "GenSigSwitchedByIgnition" SG_ 980 WH_Frontwaschen "No";
BA_ "GenSigSendType" SG_ 980 WH_Heckintervall "OnChange";
BA_ "GenSigSwitchedByIgnition" SG_ 980 WH_Heckintervall "No";
BA_ "GenSigSendType" SG_ 980 WH_Heckwaschen "OnChange";
BA_ "GenSigSwitchedByIgnition" SG_ 980 WH_Heckwaschen "No";
BA_ "GenSigSendType" SG_ 980 WH_Intervallstufen "OnChange";
BA_ "GenSigSwitchedByIgnition" SG_ 980 WH_Intervallstufen "No";
BA_ "Fehlerwert" SG_ 980 WH_Intervallstufen 15;
BA_ "GenSigMissingSourceValue" SG_ 980 WH_Intervallstufen 15;
BA_ "GenSigSendType" SG_ 980 FAS_Taster "OnChange";
BA_ "GenSigSwitchedByIgnition" SG_ 980 FAS_Taster "No";
BA_ "GenSigSendType" SG_ 980 FAS_Taster_Fehler "OnChange";
BA_ "GenSigSwitchedByIgnition" SG_ 980 FAS_Taster_Fehler "No";
BA_ "Fehlerwert" SG_ 980 FAS_Taster_Fehler 1;
BA_ "GenSigSendType" SG_ 980 SMLS_Hupe "OnChangeWithRepetition";
BA_ "GenSigSwitchedByIgnition" SG_ 980 SMLS_Hupe "No";
BA_ "GenSigSendType" SG_ 980 LRH_on_off "OnChange";
BA_ "GenSigSwitchedByIgnition" SG_ 980 LRH_on_off "No";
BA_ "Fehlerwert" SG_ 980 LRH_on_off 3;
BA_ "GenSigSendType" SG_ 980 LSS_Tastencode "OnChange";
BA_ "GenSigSwitchedByIgnition" SG_ 980 LSS_Tastencode "No";
BA_ "GenSigSendType" SG_ 980 LRH_aktiv "OnChange";
BA_ "GenSigSwitchedByIgnition" SG_ 980 LRH_aktiv "No";
BA_ "GenSigSendType" SG_ 980 SMLS_P_verriegelt "OnChangeWithRepetition";
BA_ "GenSigSwitchedByIgnition" SG_ 980 SMLS_P_verriegelt "No";
BA_ "Fehlerwert" SG_ 980 SMLS_P_verriegelt 3;
BA_ "GenSigSendType" SG_ 980 SMLS_P_verriegelt_plausibel "OnChange";
BA_ "GenSigSwitchedByIgnition" SG_ 980 SMLS_P_verriegelt_plausibel "No";
BA_ "GenSigSendType" SG_ 980 WH_SRA "OnChange";
BA_ "GenSigSwitchedByIgnition" SG_ 980 WH_SRA "No";
BA_ "GenSigSendType" SG_ 980 WH_Wischer_Fehler "OnChange";
BA_ "GenSigSwitchedByIgnition" SG_ 980 WH_Wischer_Fehler "No";
BA_ "Fehlerwert" SG_ 980 WH_Wischer_Fehler 1;
BA_ "GenSigSendType" SG_ 980 BH_Blinker_Fehler "OnChange";
BA_ "GenSigSwitchedByIgnition" SG_ 980 BH_Blinker_Fehler "No";
BA_ "Fehlerwert" SG_ 980 BH_Blinker_Fehler 1;
BA_ "GenSigSendType" SG_ 980 SMLS_PTT "OnChangeWithRepetition";
BA_ "GenSigSendType" SG_ 980 WH_Tipwischen_lang "OnChangeWithRepetition";
BA_ "GenSigSwitchedByIgnition" SG_ 980 WH_Tipwischen_lang "No";
BA_ "GenSigSendType" SG_ 2464153718 SOK_FoD_MO_01_Req_Challenge "OnChange";
BA_ "GenSigSwitchedByIgnition" SG_ 2464153718 SOK_FoD_MO_01_Req_Challenge "No";
BA_ "GenSigSendType" SG_ 2464284790 SOK_FoD_MO_01_Resp_Challenge "OnChange";
BA_ "GenSigSwitchedByIgnition" SG_ 2464284790 SOK_FoD_MO_01_Resp_Challenge "No";
BA_ "GenSigSendType" SG_ 1413 SI_Sammel_SG_Fehler "Cyclic";
BA_ "GenSigStartValue" SG_ 1413 SI_Sammel_SG_Fehler 63;
BA_ "GenSigSwitchedByIgnition" SG_ 1413 SI_Sammel_SG_Fehler "No";
BA_ "GenSigSendType" SG_ 1413 SI_P_Mode_gueltig "OnChange";
BA_ "GenSigSwitchedByIgnition" SG_ 1413 SI_P_Mode_gueltig "No";
BA_ "GenSigSendType" SG_ 1413 SI_Diagnose_Aktiv "OnChange";
BA_ "GenSigSwitchedByIgnition" SG_ 1413 SI_Diagnose_Aktiv "No";
BA_ "GenSigSendType" SG_ 1413 SI_QRS_Mode "OnChange";
BA_ "GenSigSwitchedByIgnition" SG_ 1413 SI_QRS_Mode "No";
BA_ "GenSigSendType" SG_ 1413 SI_T_Mode "OnChange";
BA_ "GenSigSwitchedByIgnition" SG_ 1413 SI_T_Mode "No";
BA_ "GenSigSendType" SG_ 1413 SI_NWDF "OnChange";
BA_ "GenSigSwitchedByIgnition" SG_ 1413 SI_NWDF "No";
BA_ "GenSigSendType" SG_ 1413 SI_NWDF_gueltig "OnChange";
BA_ "GenSigFuncType" SG_ 1413 SI_NWDF_gueltig "Constant";
BA_ "GenSigSwitchedByIgnition" SG_ 1413 SI_NWDF_gueltig "No";
BA_ "GenSigSendType" SG_ 1413 SI_Sammelfehler "OnChange";
BA_ "GenSigSwitchedByIgnition" SG_ 1413 SI_Sammelfehler "No";
BA_ "GenSigSendType" SG_ 1413 GW_KD_Fehler "OnChange";
BA_ "GenSigSendType" SG_ 1413 SI_T_Schutz "OnChange";
BA_ "GenSigSwitchedByIgnition" SG_ 1413 SI_T_Schutz "No";
BA_ "GenSigSendType" SG_ 1413 SI_P_Mode "OnChange";
BA_ "GenSigSwitchedByIgnition" SG_ 1413 SI_P_Mode "No";
BA_ "GenSigSendType" SG_ 1413 SI_BUS_01 "OnChange";
BA_ "GenSigStartValue" SG_ 1413 SI_BUS_01 1;
BA_ "GenSigSwitchedByIgnition" SG_ 1413 SI_BUS_01 "No";
BA_ "GenSigSendType" SG_ 1413 SI_BUS_02 "OnChange";
BA_ "GenSigStartValue" SG_ 1413 SI_BUS_02 1;
BA_ "GenSigSwitchedByIgnition" SG_ 1413 SI_BUS_02 "No";
BA_ "GenSigSendType" SG_ 1413 SI_BUS_03 "OnChange";
BA_ "GenSigStartValue" SG_ 1413 SI_BUS_03 1;
BA_ "GenSigSwitchedByIgnition" SG_ 1413 SI_BUS_03 "No";
BA_ "GenSigSendType" SG_ 1413 SI_BUS_04 "OnChange";
BA_ "GenSigStartValue" SG_ 1413 SI_BUS_04 1;
BA_ "GenSigSwitchedByIgnition" SG_ 1413 SI_BUS_04 "No";
BA_ "GenSigSendType" SG_ 1413 SI_BUS_05 "OnChange";
BA_ "GenSigStartValue" SG_ 1413 SI_BUS_05 1;
BA_ "GenSigSwitchedByIgnition" SG_ 1413 SI_BUS_05 "No";
BA_ "GenSigSendType" SG_ 1413 SI_BUS_06 "OnChange";
BA_ "GenSigStartValue" SG_ 1413 SI_BUS_06 1;
BA_ "GenSigSwitchedByIgnition" SG_ 1413 SI_BUS_06 "No";
BA_ "GenSigSendType" SG_ 1413 SI_BUS_07 "OnChange";
BA_ "GenSigStartValue" SG_ 1413 SI_BUS_07 1;
BA_ "GenSigSwitchedByIgnition" SG_ 1413 SI_BUS_07 "No";
BA_ "GenSigSendType" SG_ 1413 SI_BUS_08 "OnChange";
BA_ "GenSigStartValue" SG_ 1413 SI_BUS_08 1;
BA_ "GenSigSwitchedByIgnition" SG_ 1413 SI_BUS_08 "No";
BA_ "GenSigSendType" SG_ 1413 SI_BUS_09 "OnChange";
BA_ "GenSigStartValue" SG_ 1413 SI_BUS_09 1;
BA_ "GenSigSwitchedByIgnition" SG_ 1413 SI_BUS_09 "No";
BA_ "GenSigSendType" SG_ 1413 SI_BUS_10 "OnChange";
BA_ "GenSigStartValue" SG_ 1413 SI_BUS_10 1;
BA_ "GenSigSwitchedByIgnition" SG_ 1413 SI_BUS_10 "No";
BA_ "GenSigSendType" SG_ 1413 SI_BUS_11 "OnChange";
BA_ "GenSigStartValue" SG_ 1413 SI_BUS_11 1;
BA_ "GenSigSwitchedByIgnition" SG_ 1413 SI_BUS_11 "No";
BA_ "GenSigSendType" SG_ 1413 SI_BUS_12 "OnChange";
BA_ "GenSigStartValue" SG_ 1413 SI_BUS_12 1;
BA_ "GenSigSwitchedByIgnition" SG_ 1413 SI_BUS_12 "No";
BA_ "GenSigSendType" SG_ 1413 SI_BUS_13 "OnChange";
BA_ "GenSigStartValue" SG_ 1413 SI_BUS_13 1;
BA_ "GenSigSwitchedByIgnition" SG_ 1413 SI_BUS_13 "No";
BA_ "GenSigSendType" SG_ 1413 SI_BUS_14 "OnChange";
BA_ "GenSigStartValue" SG_ 1413 SI_BUS_14 1;
BA_ "GenSigSwitchedByIgnition" SG_ 1413 SI_BUS_14 "No";
BA_ "GenSigSendType" SG_ 1413 SI_BUS_15 "OnChange";
BA_ "GenSigStartValue" SG_ 1413 SI_BUS_15 1;
BA_ "GenSigSwitchedByIgnition" SG_ 1413 SI_BUS_15 "No";
BA_ "GenSigSendType" SG_ 1413 SI_Bus_Identifikation "Cyclic";
BA_ "GenSigSwitchedByIgnition" SG_ 1413 SI_Bus_Identifikation "No";
BA_ "GenSigSendType" SG_ 1413 SI_CAB_V10 "OnChange";
BA_ "GenSigSwitchedByIgnition" SG_ 1413 SI_CAB_V10 "No";
BA_ "GenSigSendType" SG_ 2589283396 TSK_vMax_EfficiencyMode1 "Cyclic";
BA_ "GenSigStartValue" SG_ 2589283396 TSK_vMax_EfficiencyMode1 255;
BA_ "GenSigSendType" SG_ 2589283396 TSK_vMax_EfficiencyMode2 "Cyclic";
BA_ "GenSigStartValue" SG_ 2589283396 TSK_vMax_EfficiencyMode2 255;
BA_ "GenSigSendType" SG_ 2589283396 TSK_vMax_StandardMode "Cyclic";
BA_ "GenSigStartValue" SG_ 2589283396 TSK_vMax_StandardMode 255;
VAL_ 2600468501 NM_Airbag_01_CBV_AWB 0 "Passiver_WakeUp" 1 "Aktiver_WakeUp";
VAL_ 2600468501 NM_Airbag_01_CBV_CRI 0 "Standard_Layout" 1 "TNB_Layout";
VAL_ 2600468501 NM_Airbag_01_NM_State 1 "NM_RM_aus_BSM" 2 "NM_RM_aus_PBSM" 4 "NM_NO_aus_RM" 8 "NM_NO_aus_RS";
VAL_ 2600468501 NM_Airbag_01_Car_Wakeup 0 "Inaktiv" 1 "Car_Wakeup";
VAL_ 2600468501 NM_Airbag_01_UDS_CC 0 "Init" 1 "CC_aktiv";
VAL_ 2600468501 NM_Airbag_01_NM_aktiv_KL15 0 "Inaktiv" 1 "KL15_EIN";
VAL_ 2600468501 NM_Airbag_01_NM_aktiv_Diagnose 0 "Init" 1 "Diagnose_aktiv";
VAL_ 2600468501 NM_Airbag_01_NM_aktiv_Tmin 0 "Inaktiv" 1 "Mindestaktivzeit";
VAL_ 2600468501 NM_Airbag_01_CAB_V10 32768 "CAB_16_Licht" 16384 "CAB_15_Laden" 128 "CAB_08_MIB" 0 "Init" 64 "CAB_07_Connect" 8192 "CAB_14_VLAN_Infotainment" 32 "CAB_06_Anzeige" 4096 "CAB_13_VLAN_Connect" 16 "CAB_05_Komfort" 8 "CAB_04_Fahrerassistenz" 1 "CAB_01_Antrieb" 2 "CAB_02_Hybrid_Laden" 4 "CAB_03_Fahrwerk" 256 "CAB_09_Standheizung" 1024 "CAB_11_VLAN_Fahrerassistenz";
VAL_ 2600468604 NM_EMotor_01_CBV_AWB 0 "Passiver_WakeUp" 1 "Aktiver_WakeUp";
VAL_ 2600468604 NM_EMotor_01_CBV_CRI 0 "Standard_Layout" 1 "TNB_Layout";
VAL_ 2600468604 NM_EMotor_01_NM_State 1 "NM_RM_aus_BSM" 2 "NM_RM_aus_PBSM" 4 "NM_NO_aus_RM" 8 "NM_NO_aus_RS";
VAL_ 2600468604 NM_EMotor_01_Car_Wakeup 0 "Inaktiv" 1 "Car_Wakeup";
VAL_ 2600468604 NM_EMotor_01_UDS_CC 0 "Init" 1 "CC_aktiv";
VAL_ 2600468604 NM_EMotor_01_NM_aktiv_KL15 0 "Inaktiv" 1 "KL15_EIN";
VAL_ 2600468604 NM_EMotor_01_NM_aktiv_Diagnose 0 "Init" 1 "Diagnose_aktiv";
VAL_ 2600468604 NM_EMotor_01_NM_aktiv_Tmin 0 "Inaktiv" 1 "Mindestaktivzeit";
VAL_ 2600468604 NM_EMotor_01_keine_HV_Entl 1 "keine_HV_Entladung_moeglich";
VAL_ 2600468604 NM_EMotor_01_CAB_V10 32768 "CAB_16_Licht" 16384 "CAB_15_Laden" 128 "CAB_08_MIB" 0 "Init" 64 "CAB_07_Connect" 8192 "CAB_14_VLAN_Infotainment" 32 "CAB_06_Anzeige" 4096 "CAB_13_VLAN_Connect" 16 "CAB_05_Komfort" 8 "CAB_04_Fahrerassistenz" 1 "CAB_01_Antrieb" 2 "CAB_02_Hybrid_Laden" 4 "CAB_03_Fahrwerk" 256 "CAB_09_Standheizung" 1024 "CAB_11_VLAN_Fahrerassistenz";
VAL_ 2600468496 NM_Gateway_CBV_AWB 0 "Passiver_WakeUp" 1 "Aktiver_WakeUp";
VAL_ 2600468496 NM_Gateway_CBV_CRI 0 "Standard_Layout" 1 "TNB_Layout";
VAL_ 2600468496 NM_Gateway_NM_State 1 "NM_RM_aus_BSM" 2 "NM_RM_aus_PBSM" 4 "NM_NO_aus_RM" 32 "NM_RM_aus_NO" 16 "NM_RM_aus_RS" 8 "NM_NO_aus_RS";
VAL_ 2600468496 NM_Gateway_Car_Wakeup 0 "Inaktiv" 1 "Car_Wakeup";
VAL_ 2600468496 NM_Gateway_UDS_CC 0 "Init" 1 "CC_aktiv";
VAL_ 2600468496 NM_Gateway_NM_aktiv_KL15 0 "Inaktiv" 1 "KL15_EIN";
VAL_ 2600468496 NM_Gateway_NM_aktiv_Diagnose 0 "Init" 1 "Diagnose_aktiv";
VAL_ 2600468496 NM_Gateway_NM_aktiv_Tmin 0 "Inaktiv" 1 "Mindestaktivzeit";
VAL_ 2600468496 NM_Gateway_CAB_V10 32768 "CAB_16_Licht" 16384 "CAB_15_Laden" 128 "CAB_08_MIB" 0 "Init" 64 "CAB_07_Connect" 8192 "CAB_14_VLAN_Infotainment" 32 "CAB_06_Anzeige" 4096 "CAB_13_VLAN_Connect" 16 "CAB_05_Komfort" 8 "CAB_04_Fahrerassistenz" 1 "CAB_01_Antrieb" 2 "CAB_02_Hybrid_Laden" 4 "CAB_03_Fahrwerk" 256 "CAB_09_Standheizung" 1024 "CAB_11_VLAN_Fahrerassistenz";
VAL_ 2600468664 NM_LE2_CBV_AWB 0 "Passiver_WakeUp" 1 "Aktiver_WakeUp";
VAL_ 2600468664 NM_LE2_CBV_CRI 0 "Standard_Layout" 1 "TNB_Layout";
VAL_ 2600468664 NM_LE2_NM_State 1 "NM_RM_aus_BSM" 2 "NM_RM_aus_PBSM" 4 "NM_NO_aus_RM" 32 "NM_RM_aus_NO" 16 "NM_RM_aus_RS" 8 "NM_NO_aus_RS";
VAL_ 2600468664 NM_LE2_Car_Wakeup 0 "Inaktiv" 1 "Car_Wakeup";
VAL_ 2600468664 NM_LE2_UDS_CC 0 "Init" 1 "CC_aktiv";
VAL_ 2600468664 NM_LE2_NM_aktiv_KL15 0 "Inaktiv" 1 "KL15_EIN";
VAL_ 2600468664 NM_LE2_NM_aktiv_Diagnose 0 "Init" 1 "Diagnose_aktiv";
VAL_ 2600468664 NM_LE2_NM_aktiv_Tmin 0 "Inaktiv" 1 "Mindestaktivzeit";
VAL_ 2600468664 NM_LE2_keine_HV_entl 0 "Inaktiv" 1 "keine_HV_Entladung_moeglich";
VAL_ 2600468664 NM_LE2_CAB_V10 32768 "CAB_16_Licht" 16384 "CAB_15_Laden" 128 "CAB_08_MIB" 0 "Init" 64 "CAB_07_Connect" 8192 "CAB_14_VLAN_Infotainment" 32 "CAB_06_Anzeige" 4096 "CAB_13_VLAN_Connect" 16 "CAB_05_Komfort" 8 "CAB_04_Fahrerassistenz" 1 "CAB_01_Antrieb" 2 "CAB_02_Hybrid_Laden" 4 "CAB_03_Fahrwerk" 256 "CAB_09_Standheizung" 1024 "CAB_11_VLAN_Fahrerassistenz";
VAL_ 2600468598 NM_MO_01_CBV_AWB 0 "Passiver_WakeUp" 1 "Aktiver_WakeUp";
VAL_ 2600468598 NM_MO_01_CBV_CRI 0 "Standard_Layout" 1 "TNB_Layout";
VAL_ 2600468598 NM_MO_01_NM_State 1 "NM_RM_aus_BSM" 2 "NM_RM_aus_PBSM" 4 "NM_NO_aus_RM" 32 "NM_RM_aus_NO" 16 "NM_RM_aus_RS" 8 "NM_NO_aus_RS";
VAL_ 2600468598 NM_MO_01_Car_Wakeup 0 "Inaktiv" 1 "Car_Wakeup";
VAL_ 2600468598 NM_MO_01_UDS_CC 0 "Init" 1 "CC_aktiv";
VAL_ 2600468598 NM_MO_01_NM_aktiv_KL15 0 "Inaktiv" 1 "KL15_EIN";
VAL_ 2600468598 NM_MO_01_NM_aktiv_Diagnose 0 "Init" 1 "Diagnose_aktiv";
VAL_ 2600468598 NM_MO_01_NM_aktiv_Tmin 0 "Inaktiv" 1 "Mindestaktivzeit";
VAL_ 2600468598 NM_MO_01_NM_aktiv_Betankung 0 "kein_Nachlauf" 1 "Betankung_Drucktank";
VAL_ 2600468598 NM_MO_01_NM_aktiv_Waehlhebel 0 "kein_Nachlauf" 1 "Kommunikation_Waehlhebel";
VAL_ 2600468598 NM_MO_01_NM_aktiv_HV_Abschaltung 0 "kein_Nachlauf" 1 "Abschaltung_aktiv";
VAL_ 2600468598 NM_MO_01_NM_aktiv_Hochvolt 0 "kein_Nachlauf" 1 "Hochvolt_aktiv";
VAL_ 2600468598 NM_MO_01_CAB_V10 32768 "CAB_16_Licht" 16384 "CAB_15_Laden" 128 "CAB_08_MIB" 0 "Init" 64 "CAB_07_Connect" 8192 "CAB_14_VLAN_Infotainment" 32 "CAB_06_Anzeige" 4096 "CAB_13_VLAN_Connect" 16 "CAB_05_Komfort" 8 "CAB_04_Fahrerassistenz" 1 "CAB_01_Antrieb" 2 "CAB_02_Hybrid_Laden" 4 "CAB_03_Fahrwerk" 256 "CAB_09_Standheizung" 1024 "CAB_11_VLAN_Fahrerassistenz";
VAL_ 2600468733 NM_Waehlhebel_CBV_AWB 0 "Passiver_WakeUp" 1 "Aktiver_WakeUp";
VAL_ 2600468733 NM_Waehlhebel_CBV_CRI 0 "Standard_Layout" 1 "TNB_Layout";
VAL_ 2600468733 NM_Waehlhebel_NM_State 32 "NM_RM_aus_NO" 16 "NM_RM_aus_RS" 8 "NM_NO_aus_RS" 0 "Init" 1 "NM_RM_aus_BSM" 2 "NM_RM_aus_PBSM" 4 "NM_NO_aus_RM";
VAL_ 2600468733 NM_Waehlhebel_Car_Wakeup 0 "Inaktiv" 1 "Car_Wakeup";
VAL_ 2600468733 NM_Waehlhebel_UDS_CC 0 "Init" 1 "CC_aktiv";
VAL_ 2600468733 NM_Waehlhebel_NM_aktiv_KL15 0 "Inaktiv" 1 "KL15_EIN";
VAL_ 2600468733 NM_Waehlhebel_NM_aktiv_Diagnose 0 "Init" 1 "Diagnose_aktiv";
VAL_ 2600468733 NM_Waehlhebel_NM_aktiv_Tmin 0 "Inaktiv" 1 "Mindestaktivzeit";
VAL_ 2600468733 NM_Waehlhebel_CAB_V10 32768 "CAB_16_Licht" 16384 "CAB_15_Laden" 128 "CAB_08_MIB" 0 "Init" 64 "CAB_07_Connect" 8192 "CAB_14_VLAN_Infotainment" 32 "CAB_06_Anzeige" 4096 "CAB_13_VLAN_Connect" 16 "CAB_05_Komfort" 8 "CAB_04_Fahrerassistenz" 1 "CAB_01_Antrieb" 2 "CAB_02_Hybrid_Laden" 4 "CAB_03_Fahrwerk" 256 "CAB_09_Standheizung" 1024 "CAB_11_VLAN_Fahrerassistenz";
VAL_ 627 OCC_Stecker_Status 0 "Init" 1 "kein_Stecker_erkannt" 2 "Stecker_erkannt" 3 "Fehler";
VAL_ 627 OCC_Status_Spgfreiheit 0 "Init__ohne_Funktion" 1 "HV_Komponente_Spannungsfrei" 2 "HV_Komponente_nichtSpannungsfrei" 3 "Fehler";
VAL_ 627 OCC_DC_IstStrom 2046 "Init" 2047 "Fehler";
VAL_ 627 OCC_CC_Latchstatus_DC_GBT 0 "nicht_betaetigt" 1 "betaetigt" 2 "nicht_vorhanden" 6 "Init" 7 "Fehler";
VAL_ 627 OCC_Status_EoHVL 0 "Init" 1 "Keine_offene_HV_Leitung_erkannt" 2 "offene_HV_Leitung_erkannt" 3 "Fehler";
VAL_ 627 OCC_I_istAC_Netz_L1 510 "Init" 511 "Fehler";
VAL_ 627 OCC_PP_Latchstatus_A 0 "nicht_betaetigt" 1 "betaetigt" 2 "nicht_vorhanden" 6 "Init" 7 "Fehler";
VAL_ 627 OCC_PP_Latchstatus_B 0 "nicht_betaetigt" 1 "betaetigt" 2 "nicht_vorhanden" 6 "Init" 7 "Fehler";
VAL_ 627 OCC_I_istAC_Netz_L2 510 "Init" 511 "Fehler";
VAL_ 627 OCC_I_istAC_Netz_L3 509 "nicht_vorhanden" 510 "Init" 511 "Fehler";
VAL_ 627 OCC_IstModus 0 "Standby" 1 "Netzladung_aktiv" 2 "Rueckspeisung_aktiv" 3 "reserve" 4 "reserve" 5 "reserve" 6 "Init" 7 "Fehler";
VAL_ 627 OCC_CP_Status_A 0 "CP_nicht_erkannt" 1 "CP_erkannt" 2 "Init" 3 "Fehler";
VAL_ 627 OCC_CP_Status_B 0 "CP_nicht_erkannt" 1 "CP_erkannt" 2 "Init" 3 "Fehler";
VAL_ 627 OCC_IstSpannung_HV 1022 "Init" 1023 "Fehler";
VAL_ 627 OCC_PP_Status_A 0 "nicht_erkannt" 1 "erkannt" 2 "Init" 3 "Fehler";
VAL_ 627 OCC_PP_Status_B 0 "nicht_erkannt" 1 "erkannt" 2 "Init" 3 "Fehler";
VAL_ 627 OCC_CC_Status_DC_GBT 0 "nicht_erkannt" 1 "erkannt" 2 "Init" 3 "Fehler";
VAL_ 627 OCC_CC_Fehlerstatus_DC_GBT 0 "Init" 1 "kein_Fehler" 2 "Aktiv_Kurzschluss_nach_Masse" 3 "Aktiv_Kurzschluss_nach_12V" 4 "Fehler_in_Hardwarschaltung" 5 "Fehler_Ladedose" 6 "Fehler_Ladestecker" 7 "keine_GBT_DC_Ladedose" 8 "Fehler_Zwischenbereich_erkannt";
VAL_ 627 OCC_Temp_Sensor_Fehlerstatus_DC 0 "Init" 1 "Fehler_Sensor_defekt" 2 "kein_Fehler";
VAL_ 627 OCC_Temp_Sensor_Fehlerstatus_AC 0 "Init" 1 "Fehler_Kurzschluss" 2 "Warnung" 3 "kein_Fehler";
VAL_ 627 OCC_Temp_Sensor_Status 0 "Init" 1 "kein_Fehler" 2 "DC_Plus_Fehler" 3 "DC_Minus_Fehler" 4 "DC_Plus_und_DC_Minus_Fehler" 5 "Reserve" 6 "Reserve";
VAL_ 2463978709 OCC_CP_Tastgrad_A 1022 "Init" 1023 "Fehler";
VAL_ 2463978709 OCC_CP_Tastgrad_B 1022 "Init" 1023 "Fehler";
VAL_ 2463978709 OCC_CP_Frequenz_A 253 "keine_Frequenz_erkannt" 254 "Init" 255 "Fehler";
VAL_ 2463978709 OCC_CP_Frequenz_B 253 "keine_Frequenz_erkannt" 254 "Init" 255 "Fehler";
VAL_ 2463978709 OCC_CP_Spannung_A 510 "Init" 511 "Fehler";
VAL_ 2463978709 OCC_CP_Spannung_B 510 "Init" 511 "Fehler";
VAL_ 2463978709 OCC_CP_Fehlerstatus_A 0 "Messsystem_niO" 1 "Spannung_niO" 2 "Frequenz_niO" 3 "Tastgrad_niO" 4 "Init" 5 "Kein_Fehler" 6 "keine_CP_Ladedose";
VAL_ 2463978709 OCC_CP_Fehlerstatus_B 0 "Messsystem_niO" 1 "Spannung_niO" 2 "Frequenz_niO" 3 "Tastgrad_niO" 4 "Init" 5 "kein_Fehler" 6 "keine_CP_Ladedose";
VAL_ 2463978709 OCC_Temp_Ladedose_A_AC 254 "Init" 255 "Fehler";
VAL_ 2463978709 OCC_Temp_Ladedose_A_DC_minus 254 "Init" 255 "Fehler";
VAL_ 2463978709 OCC_Temp_Ladedose_A_DC_plus 254 "Init" 255 "Fehler";
VAL_ 2463978709 OCC_U_istAC_Netz_L1 510 "Init" 511 "Fehler";
VAL_ 2463978709 OCC_U_istAC_Netz_L2 510 "Init" 511 "Fehler";
VAL_ 2463978709 OCC_U_istAC_Netz_L3 509 "nicht_vorhanden" 510 "Init" 511 "Fehler";
VAL_ 2463978709 OCC_StatusVerEntriegelungAktor_A 0 "keine_Ansteuerung" 1 "entriegeln_wird_angesteuert" 2 "verriegeln_wird_angesteuert" 3 "maximale_WdhVersuche_erreicht" 4 "reserve" 5 "reserve" 6 "Init" 7 "Fehler";
VAL_ 2463978709 OCC_SteckerEntriegelung_Verbot_A 0 "kein_Verbot" 1 "Entriegelungsverbot_des_Steckers" 2 "reserve" 3 "Init";
VAL_ 2463978709 OCC_StatusVerEntriegelungAktor_B 0 "keine_Ansteuerung" 1 "entriegeln_wird_angesteuert" 2 "verriegeln_wird_angesteuert" 3 "maximale_WdhVersuche_erreicht" 4 "reserve" 5 "reserve" 6 "Init" 7 "Fehler";
VAL_ 2463978709 OCC_SteckerEntriegelung_Verbot_B 0 "kein_Verbot" 1 "Entriegelungsverbot_des_Steckers" 2 "reserve" 3 "Init";
VAL_ 2463978709 OCC_Verriegelung_Status_A 0 "entriegelt" 1 "verriegelt" 2 "zu_weit_gefahren_erkannt" 3 "verklemmt_erkannt" 4 "reserve" 5 "reserve" 6 "Init" 7 "Fehler";
VAL_ 2463978709 OCC_Verriegelung_Status_B 0 "entriegelt" 1 "verriegelt" 2 "zu_weit_gefahren_erkannt" 3 "verklemmt_erkannt" 4 "reserve" 5 "reserve" 6 "Init" 7 "Fehler";
VAL_ 2463978709 OCC_RtmWarnLadeKommunikation 0 "kein_Fehler" 1 "Fehler_Stufe_1" 2 "Fehler_Stufe_2" 3 "Fehler_Stufe_3" 4 "reserviert" 5 "reserviert" 6 "reserviert" 7 "reserviert";
VAL_ 2463978709 OCC_Ist_Wirkungsgrad 126 "Init" 127 "Fehler";
VAL_ 2463978709 OCC_PP_Max_Strom_A 0 "nicht_vorhanden" 1 "Wert_10A" 2 "Wert_13A" 3 "Wert_16A" 4 "Wert_20A" 5 "Wert_32A" 6 "Wert_63A" 7 "reserve" 8 "Init" 9 "Fehler";
VAL_ 2463978709 OCC_PP_Max_Strom_B 0 "nicht_vorhanden" 1 "Wert_10A" 2 "Wert_13A" 3 "Wert_16A" 4 "Wert_20A" 5 "Wert_32A" 6 "Wert_63A" 7 "reserve" 8 "Init" 9 "Fehler";
VAL_ 2463978709 OCC_DC_MaxStrom 2046 "Init" 2047 "Fehler";
VAL_ 2463978709 OCC_Derating_Temperatur 0 "kein_Derating_aktiv" 1 "Derating_aktiv";
VAL_ 2463978709 OCC_Fehlerzustand 0 "kein_Fehler_aktiv" 1 "Fehler_aktiv_Laden_beendet";
VAL_ 2463978709 OCC_Ladest_Entriegelungs_Verbot 0 "kein_Entriegelungsverbot" 1 "Entriegelungsverbot_Ladedose_A" 2 "Entriegelungsverbot_Ladedose_B" 3 "Entriegelungsverbot_beide_Ladedo" 4 "reserve" 5 "reserve" 6 "Init" 7 "Fehler";
VAL_ 2463978709 OCC_Netzfrequenz_EVU 509 "kein_Frequenz_erkannt" 510 "Init" 511 "Fehler";
VAL_ 2463978709 OCC_Warnzustand 0 "keine_Warnung" 1 "Warnung_aktiv";
VAL_ 2463978709 OCC_Kuehltemperatur 254 "Init" 255 "Fehler";
VAL_ 2463978709 OCC_PP_Fehlerstatus_A 0 "keinen_Fehler" 1 "Fehler_Zwischenbereich_erkannt" 2 "Aktiv_Kurzschluss_nach_Masse" 3 "Aktiv_Kurzschluss_nach_12V" 4 "Fehler_in_Hardwareschaltung" 5 "Fehler_Ladedose" 6 "Fehler_Ladestecker" 7 "keine_PP_Ladedose" 8 "Init";
VAL_ 2463978709 OCC_PP_Fehlerstatus_B 0 "kein_Fehler" 1 "Fehler_Zwischenbereich_erkannt" 2 "Aktiv_Kurzschluss_nach_Masse" 3 "Aktiv_Kurzschluss_nach_12V" 4 "Fehler_in_Hardwareschaltung" 5 "Fehler_Ladedose" 6 "Fehler_Ladestecker" 7 "keine_PP_Ladedose" 8 "Init";
VAL_ 2589283656 ORU_EM_Anfrage_freigegebeneNetze 0 "only_12V" 1 "networks_48V_and_12V" 2 "networks_HV_and_12V" 3 "networks_HV_and_48V_and_12V";
VAL_ 2589283656 ORU_Warnung 0 "keine_Anzeige" 1 "Update_unvollstaendig_Prio1" 2 "reserviert" 3 "reserviert";
VAL_ 2589283656 ORU_Status 0 "IDLE" 1 "PENDING" 2 "PREPARATION" 3 "PREPARATION_HV" 4 "RUNNING" 5 "RUNNING_HV" 6 "PENDING_NOTREADY";
VAL_ 2527679741 PAO_ON_Status 0 "LED_aus" 1 "LED_an" 2 "LED_blinkt" 3 "LED_defekt";
VAL_ 2527679741 PAO_OFF_Status 0 "LED_aus" 1 "LED_an" 2 "LED_blinkt" 3 "LED_defekt";
VAL_ 518 Parken_BKD_Anf 14 "Neutralwert" 15 "Fehler";
VAL_ 518 Parken_Verz_Anf 126 "Neutralwert" 127 "reserved";
VAL_ 518 Parken_Prefill_Anf 0 "keine_Anforderung" 1 "Prefill_Anforderung";
VAL_ 518 Parken_Warnruck_Anf 0 "Keine_Anforderung" 1 "schwacher_Warnruck" 2 "mittlerer_Warnruck" 3 "starker_Warnruck";
VAL_ 518 Parken_Verz_Anf_ASIL 0 "ASIL_QM" 1 "ASIL_A" 2 "ASIL_B" 3 "ASIL_C";
VAL_ 518 Parken_Warnruckeln_Anf 0 "keine_Anforderung" 1 "schwaches_Warnruckeln" 2 "mittleres_Warnruckeln" 3 "starkes_Warnruckeln";
VAL_ 518 Parken_beibehalten 0 "Parken_nicht_beibehalten" 1 "Parken_beibehalten" 2 "Init" 3 "Fehler";
VAL_ 518 Parken_Anforderung_HMS 0 "keine_Anforderung" 1 "Halten" 2 "Parken" 3 "Halten_standby" 4 "Anfahren" 5 "Loesen_ueber_Rampe" 6 "Parken_mit_P" 7 "reserviert";
VAL_ 518 Parken_Notstopp_Anf 0 "Ueberwachung_aus" 1 "Ueberwachung_ein" 2 "Notstopp_ausloesen";
VAL_ 518 Parken_Anhalteweg_Anf 1022 "Neutralwert" 1023 "Fehler";
VAL_ 518 Parken_aktives_System 0 "kein_aktives_System" 1 "Manoevrierassistent_Ueberwachung" 2 "IPA" 3 "fernbedientes_Parken" 4 "Manoevrierassistent" 5 "Manoevrierassistent_quer" 6 "Anhaengerrangierassistent" 7 "fernbedienter_Anhaengerrangierassistent";
VAL_ 518 Parken_max_Beschleunigung 0 "Inaktiv" 122 "Init" 127 "Fehler";
VAL_ 518 Parken_Blinker_li_Anf 0 "keine_Anforderung" 1 "Blinker_links_aktivieren";
VAL_ 518 Parken_QFK_KruemmSoll_VZ 0 "positiv" 1 "negativ";
VAL_ 518 Parken_QFK_AnfStat 1 "Init" 2 "Bereit" 4 "Eingriff";
VAL_ 518 Parken_Sollbeschleunigung 0 "Neutralwert";
VAL_ 518 Parken_Blinker_re_Anf 0 "keine_Anforderung" 1 "Blinker_rechts_aktivieren";
VAL_ 518 Parken_Status_IPA_TSK 1 "IPA_TSK_Init" 2 "IPA_TSK_Fehler" 4 "IPA_TSK_aktivierbar" 5 "IPA_TSK_pausiert" 6 "IPA_TSK_aktiv" 8 "IPA_TSK_funktionsbereit";
VAL_ 518 Parken_erhoehtes_Moment 0 "keine_Anforderung" 1 "Anforderung_Rampe1" 2 "Anforderung_Rampe2" 3 "Anforderung_Rampe3" 4 "Anforderung_Rampe4" 5 "Anforderung_Rampe5" 6 "Anforderung_Rampe6" 7 "Anforderung_Rampe7" 8 "Anforderung_Rampe8" 9 "Anforderung_Rampe9" 10 "Anforderung_Rampe10" 11 "Anforderung_Rampe11" 12 "Anforderung_Rampe12" 13 "Anforderung_Rampe13" 14 "Anforderung_Rampe14" 15 "Anforderung_Rampe15";
VAL_ 518 Parken_max_Geschwindigkeit 0 "Inaktiv" 251 "Init" 255 "Fehler";
VAL_ 518 Parken_Soll_Anhalteweg_Anf 1022 "Neutralwert" 1023 "Fehler";
VAL_ 518 Parken_Fahrstufenwunsch 0 "Init" 1 "Fahrstufe_beibehalten" 2 "Position_R" 3 "Position_D" 4 "Position_N";
VAL_ 518 IPA_TPA_Remote 0 "nicht_aktiv" 1 "aktiv" 2 "Uebergabe" 3 "Uebernahme";
VAL_ 518 IPA_TPA_Remote_Anf 0 "keine_Anforderung" 1 "Remote_Anforderung";
VAL_ 518 IPA_TPA_Fehler 0 "Init" 1 "ESC_Fehler" 2 "PPF_Fehler" 3 "VMM_Fehler" 4 "sonstiger_Fehler" 5 "temporaerer_Fehler";
VAL_ 518 IPA_TPA_Abbruch 8 "Ueberschreitung_vMax" 0 "Init" 1 "ESC_Fehler" 2 "PPF_Fehler" 3 "VMM_Fehler" 4 "sonstiger_Fehler" 5 "temporaerer_Fehler" 7 "Hindernis" 9 "Lenkeingriff_Fahrer" 10 "Tuer_offen" 11 "MH_HD_offen";
VAL_ 518 IPA_TPA_Status 8 "funktionsbereit" 0 "deaktiv" 1 "Init" 4 "startbereit" 6 "Regelung_aktiv" 15 "Error" 7 "Parkvorgang_abgeschlossen" 10 "Abbruch";
VAL_ 2527679685 PDC_ASM_Ereignis 0 "No_Event" 255 "ASM_Trigger";
VAL_ 2527679685 PDC_ASM_Zeitstempel 255 "Init";
VAL_ 319 PreCrash_Charisma_FahrPr 0 "keine_Funktion" 1 "Programm_1" 2 "Programm_2" 3 "Programm_3" 4 "Programm_4" 5 "Programm_5" 6 "Programm_6" 7 "Programm_7" 8 "Programm_8" 9 "Programm_9" 10 "Programm_10" 11 "Programm_11" 12 "Programm_12" 13 "Programm_13" 14 "Programm_14" 15 "Programm_15";
VAL_ 319 PreCrash_Charisma_Status 0 "Init" 1 "verfuegbar" 2 "nicht_verfuegbar" 3 "asynchron_durch_Fahrerwunsch";
VAL_ 319 PreCrash_Schiebedach_schliessen 0 "keine_Schliessung" 1 "Schliessung_angefordert";
VAL_ 319 PreCrash_Fenster_schliessen 0 "keine_Schliessung" 1 "Schliessung_angefordert";
VAL_ 319 PreCrash_Blinken 0 "keine_Blinkanforderung" 1 "Warnblinken" 2 "RECAS_Blinken" 3 "Notbremsblinken";
VAL_ 319 SC_PreSense_FCWP 0 "Warnung_gilt_fuer_Objekte" 1 "Warnung_gitl_fuer_Fussgaenger";
VAL_ 319 PreCrash_Tueren_Verriegeln 0 "keine_Anforderung" 1 "Tueren_Verriegeln";
VAL_ 319 PreCrash_FS_Laengsverstellung 0 "nicht_angefordert" 1 "angefordert";
VAL_ 319 PreCrash_Anforderung_AFR 0 "keine_Anforderung" 1 "linke_Seite" 2 "rechte_Seite" 3 "Vorderachse" 4 "Hinterachse" 5 "Vorwarnung" 7 "Init";
VAL_ 319 SC_PreCrash_LED 0 "keine_Anzeige" 1 "Stufe_1_glimmen" 2 "Stufe_2_leuchten" 3 "Stufe_3_blinken";
VAL_ 319 PreCrash_FS_Pneumatik_ansteuern 0 "keine_Anforderung" 1 "Pneumatik_ansteuern";
VAL_ 319 PreCrash_BFS_Pneumatik_ansteuern 0 "keine_Anforderung" 1 "Pneumatik_ansteuern";
VAL_ 319 PreCrash_Fo_Pneumatik_ansteuern 0 "keine_Anforderung" 1 "Pneumatik_ansteuern";
VAL_ 319 PreCrash_FS_Sitzlehne_verfahren 0 "keine_Anforderung" 1 "Sitzlehne_in_pos_x-Richtung_verfahren(vor)" 2 "Sitzlehne_in_neg_x-Richtung_verfahren(zurueck)" 3 "Sitzlehnenkopf_in_pos_x-Richtung_verfahren(vor)" 4 "Sitzlehnenkopf_in_neg_x-Richtung_verfahren(zurueck)" 6 "Lehnenverstellung_ansteuern" 7 "Lehnenkopfverstellung_ansteuern";
VAL_ 319 PreCrash_BFS_Sitzlehne_verfahren 0 "keine_Anforderung" 1 "Sitzlehne_in_pos_x-Richtung_verfahren(vor)" 2 "Sitzlehne_in_neg_x-Richtung_verfahren(zurueck)" 3 "Sitzlehnenkopf_in_pos_x-Richtung_verfahren(vor)" 4 "Sitzlehnenkopf_in_neg_x-Richtung_verfahren(zurueck)" 6 "Lehnenverstellung_ansteuern" 7 "Lehnenkopfverstellung_ansteuern";
VAL_ 319 PreCrash_Fo_Sitzlehne_verfahren 0 "keine_Anforderung" 1 "Sitzlehne_in_pos_x-Richtung_verfahren(vor)" 2 "Sitzlehne_in_neg_x-Richtung_verfahren(zurueck)" 3 "Sitzlehnenkopf_in_pos_x-Richtung_verfahren(vor)" 4 "Sitzlehnenkopf_in_neg_x-Richtung_verfahren(zurueck)";
VAL_ 319 PreCrash_FS_KSV_verfahren 0 "keine_Anforderung" 1 "in_pos_x-Richtung_verfahren" 2 "in_neg_x-Richung_verfahren" 3 "in_pos_z-Richtung_verfahren" 4 "in_neg_z-Richtung_verfahren" 5 "in_pos_x-Richtung_und_neg_z-Richtung_verfahren" 6 "in_pos_x_Richtung_und_pos_z-Richtung_verfahren" 7 "in_neg_x-Richtung_und_neg_z-Richtung_verfahren" 8 "in_neg_x-Richtung_und_pos_z-Richtung_verfahren" 9 "Kopfstuetze_ansteuern";
VAL_ 319 PreCrash_BFS_KSV_verfahren 0 "keine_Anforderung" 1 "in_pos_x-Richtung_verfahren" 2 "in_neg_x-Richung_verfahren" 3 "in_pos_z-Richtung_verfahren" 4 "in_neg_z-Richtung_verfahren" 5 "in_pos_x-Richtung_und_neg_z-Richtung_verfahren" 6 "in_pos_x_Richtung_und_pos_z-Richtung_verfahren" 7 "in_neg_x-Richtung_und_neg_z-Richtung_verfahren" 8 "in_neg_x-Richtung_und_pos_z-Richtung_verfahren" 9 "Kopfstuetze_ansteuern";
VAL_ 319 PreCrash_Fo_KSV_verfahren 0 "keine_Anforderung" 1 "in_pos_x-Richtung_verfahren" 2 "in_neg_x-Richung_verfahren" 3 "in_pos_z-Richtung_verfahren" 4 "in_neg_z-Richtung_verfahren" 5 "in_pos_x-Richtung_und_neg_z-Richtung_verfahren" 6 "in_pos_x_Richtung_und_pos_z-Richtung_verfahren" 7 "in_neg_x-Richtung_und_neg_z-Richtung_verfahren" 8 "in_neg_x-Richtung_und_pos_z-Richtung_verfahren";
VAL_ 319 PreCrash_BFS_Laengsverstellung 0 "nicht_angefordert" 1 "angefordert";
VAL_ 319 SC_PreCrash_Warnung 0 "keine_Anzeige" 1 "latente_Vorwarnung" 2 "Vorwarnung" 3 "Akutwarnung" 4 "Eingriff" 5 "Fahreruebernahmeaufforderung" 6 "Abbiegewarnung" 7 "Basiseingriff" 8 "Heckeingriff";
VAL_ 319 SC_PreCrash_Texte 0 "keine_Anzeige" 1 "Systemstoerung" 2 "keine_Sensorsicht" 3 "Demomodus" 4 "System_aus" 5 "Anhaengerbetrieb" 6 "ESC_aus" 7 "zurzeit_eingeschraenkt" 8 "zurzeit_eingeschraenkt_ESP_Aus" 9 "Initialisierung";
VAL_ 1122 PSD_Segment_ID 0 "keine Segmentinformationen vorhanden" 1 "Fehlerwert";
VAL_ 1122 PSD_Vorgaenger_Segment_ID 0 "keine Segmentinformation vorhanden" 1 "Fehlerwert";
VAL_ 1122 PSD_Strassenkategorie 0 "Rest_Feldweg_Schotterweg_Privatweg" 1 "Ortsstraße" 2 "Kreisstraße" 3 "Landstraße" 4 "Bundesstraße" 5 "Autobahn" 7 "Init";
VAL_ 1122 PSD_Endkruemmung 255 "Gerade";
VAL_ 1122 PSD_Endkruemmung_Vorz 0 "Kruemmung_positiv" 1 "Kruemmung_negativ";
VAL_ 1122 PSD_Idenditaets_ID 0 "keine_Segment_Informationen_vorhanden" 1 "Fehler";
VAL_ 1122 PSD_ADAS_Qualitaet 0 "keine_ADAS_Qualitaet" 1 "ADAS_Qualitaet";
VAL_ 1122 PSD_wahrscheinlichster_Pfad 0 "Pfad_mit_geringer_Wahrscheinlichkeit" 1 "wahrscheinlichster_Pfad";
VAL_ 1122 PSD_Geradester_Pfad 0 "nicht_geradester_PFad" 1 "geradester_Pfad";
VAL_ 1122 PSD_Fahrspuren_Anzahl 0 "Einbahnstrasse_in_falsche_Richtung" 1 "eine_Fahrspur" 2 "zwei_Fahrspuren" 3 "drei_Fahrspuren" 4 "vier_Fahrspuren" 5 "fuenf_Fahrspuren" 6 "sechs_Fahrspuren" 7 "mehr_als_sechs_Fahrspuren";
VAL_ 1122 PSD_Bebauung 0 "ausserhalb_bebauten_Gebietes" 1 "innerhalb_bebauten_Gebietes";
VAL_ 1122 PSD_Segment_Komplett 0 "Segment_Attribute_nicht_komplett" 1 "Segment_Attribute_komplett";
VAL_ 1122 PSD_Rampe 0 "Strasse_mit_Gegenverkehr" 1 "Auffahrt_Einbahnstr" 2 "Abfahrt_Einbahnstr" 3 "Einbahnstrasse";
VAL_ 1122 PSD_Anfangskruemmung 255 "Gerade";
VAL_ 1122 PSD_Anfangskruemmung_Vorz 0 "positiv" 1 "negativ";
VAL_ 1122 PSD_Abzweigerichtung 0 "rects_abzweigende_Strasse" 1 "links_abzweigende_Strasse";
VAL_ 1123 PSD_Pos_Segment_ID 0 "keine Position gegeben" 1 "Fehlerwert";
VAL_ 1123 PSD_Pos_Standort_Eindeutig 0 "mehrdeutiger_Standort" 1 "eindeutiger_Standort";
VAL_ 1123 PSD_Pos_Fehler_Laengsrichtung 0 "Init" 1 "< 2m" 2 "< 5m" 3 "< 10m" 4 "< 20m" 5 "< 50m" 6 "> 50m" 7 "Off-Road";
VAL_ 1123 PSD_Pos_Fahrspur 0 "unbekannt" 1 "Erste_Spur_von_rechts" 2 "Zweite_Spur_von_rechts" 3 "Dritte_Spur_von_rechts" 4 "Vierte_Spur_von_rechts" 5 "Fuenfte_Spur_von_rechts" 6 "Sechte_Spur_von_rechts" 7 "Siebte_oder_weitere_Spur_von_rechts";
VAL_ 1123 PSD_Attribut_Segment_ID_05 0 "keine_Segment_Information" 1 "Fehler";
VAL_ 1123 PSD_Attribut_1_ID 0 "keine_Information";
VAL_ 1123 PSD_Attribut_2_ID 0 "keine_Information";
VAL_ 1123 PSD_Attribute_Komplett_05 0 "Attribute_nicht_komplett" 1 "Attribute_komplett";
VAL_ 1124 PSD_06_Mux 0 "Init";
VAL_ 1124 PSD_Sys_Segment_ID 0 "keine Segmentinformationen vorhanden" 1 "nicht zulaessig";
VAL_ 1124 PSD_Attribut_Segment_ID 0 "keine_Segment_Information_vorhanden" 1 "Fehler";
VAL_ 1124 PSD_Ges_Segment_ID 0 "keine Segmentinformationen vorhanden" 1 "nicht zulaessig";
VAL_ 1124 PSD_Baum_Laenge_VZ 0 "Ost" 1 "West";
VAL_ 1124 PSD_Steigung_1_Segment_ID 0 "keine_Segment_Information_vorhanden" 1 "Fehler";
VAL_ 1124 PSD_Baum_Laenge 33554431 "keine_GPS_Information";
VAL_ 1124 PSD_Attribut_3_ID 0 "keine_Information";
VAL_ 1124 PSD_Steigung_1_A_Steigung 126 "mehr_als_15_Prozent" 127 "Steigung_unbekannt";
VAL_ 1124 PSD_Ges_Geschwindigkeit 0 "Kein Geschwindigkeitsgebot" 1 "0 km/h < v_max <  5 km/h" 2 "5 km/h < v_max < 10km/h" 3 "10 km/h < v_max < 15 km/h" 4 "15 km/h < v_max < 20 km/h" 5 "20 km/h < v_max < 25 km/h" 6 "25 km/h < v_max < 30 km/h" 7 "30 km/h < v_max < 35 km/h" 8 "35 km/h < v_max < 40 km/h" 9 "40 km/h < v_max < 45 km/h" 10 "45 km/h < v_max < 50 km/h" 11 "50 km/h < v_max < 60 km/h" 12 "60 km/h < v_max < 70 km/h" 13 "70 km/h < v_max < 80 km/h" 14 "80 km/h < v_max < 90 km/h" 15 "90 km/h < v_max < 100 km/h" 16 "100 km/h < v_max < 110 km/h" 17 "110 km/h < v_max < 120 km/h" 18 " 120 km/h < v_max < 130 km/h" 19 "130 km/h < v_max < 140 km/h" 20 "140 km/h < v_max < 150 km/h" 21 "150 km/h < v_max < 160 km/h" 22 "160 km/h < v_max" 23 "Geschwindigkeitsgebot aufgehoben" 24 "..0x1F ungültig";
VAL_ 1124 PSD_Steigung_1_A_Vorz 0 "Gefaelle" 1 "Steigung";
VAL_ 1124 PSD_Sys_Geschwindigkeit_Einheit 0 "km/h" 1 "mph";
VAL_ 1124 PSD_Sys_Verkehrsrichtung 0 "Rechtsverkehr" 1 "Linksverkehr";
VAL_ 1124 PSD_Sys_Geometrieguete 0 "Geringe_Guete" 1 "tbd" 2 "tbd" 3 "Hohe_Guete";
VAL_ 1124 PSD_Sys_Mapmatchingguete 0 "geringe_Guete" 1 "res" 2 "res" 3 "hohe_Guete";
VAL_ 1124 PSD_Ges_Typ 0 "Geschw_Klasse_des_Kartendatensuppliers" 1 "Explizit_abgeleiteten_Begrenzung" 2 "Durch_Gesetzg_vorgeg_allgem_Gebot_fuer_uebertr_Rahmenbed" 3 "Init";
VAL_ 1124 PSD_Sys_Alter_Karte 0 "kleiner_1_Jahr" 1 "1_Jahr" 2 "2_Jahre" 3 "3_Jahre" 4 "4_Jahre" 5 "5_Jahre" 6 "6_Jahre" 7 "groesser_7_Jahre";
VAL_ 1124 PSD_Ges_Spur_Geschw_Begrenzung 0 "Gebot_fuer_alle_spuren_gueltig";
VAL_ 1124 PSD_Steigung_1_B_Steigung 126 "mehr_als_15_Prozent" 127 "Steigung_unbekannt";
VAL_ 1124 PSD_Attribut_4_ID 0 "keine_Information";
VAL_ 1124 PSD_Sys_Zielfuehrung 0 "Zielfuehrung nicht aktiv" 1 "Zielfuehrung aktiv";
VAL_ 1124 PSD_Sys_US_State 0 "kein_US_State" 1 "Alabama" 2 "Alaska" 3 "Arkansas" 4 "Arizona" 5 "California" 6 "Colorado" 7 "Conneticut" 8 "District_of_Columbia" 9 "Delaware" 10 "Florida" 11 "Georgia" 12 "Hawaii" 13 "Idaho" 14 "Illinois" 15 "Iowa" 16 "Indiana" 17 "Kansas" 18 "Kentucky" 19 "Louisiana" 20 "Massachusetts" 21 "Maryland" 22 "Maine" 23 "Michigan" 24 "Minnesota" 25 "Missouri" 26 "Mississippi" 27 "Montana" 28 "North_Carolina" 29 "North_Dakota" 30 "Nebraska" 31 "Nevada" 32 "New_Hampshire" 33 "New_Jersey" 34 "New_Mexico" 35 "New_York" 36 "Ohio" 37 "Oklahoma" 38 "Oregon" 39 "Pennsylvania" 40 "Puerto_Rico" 41 "Rhode_Island" 42 "South_Carolina" 43 "South_Dakota" 44 "Tennessee" 45 "Texas" 46 "Utah" 47 "Virginia" 48 "Virgin_Islands" 49 "Vermont" 50 "Washington" 51 "Wisconsin" 52 "West_Virginia" 53 "Wyoming";
VAL_ 1124 PSD_Ges_Geschwindigkeit_Gespann 0 "alle Fahrzeuge" 1 "PKW mit Gespann" 2 "LKW, Busse, etc.";
VAL_ 1124 PSD_Baum_Breite_VZ 0 "Nord" 1 "Sued";
VAL_ 1124 PSD_Ges_Geschwindigkeit_Witter 0 "Witterungsunabhängig" 1 "Nässe, Regen, Niederschlag" 2 "Glätte" 3 "Nebel";
VAL_ 1124 PSD_Steigung_1_B_Vorz 0 "Gefaelle" 1 "Steigung";
VAL_ 1124 PSD_Ges_Geschwindigkeit_Tag_Anf 0 "kein Beginn definiert" 1 "Montag" 2 "Dienstag" 3 "Mittwoch" 4 "Donnerstag" 5 "Freitag" 6 "Samstag" 7 "Sonntag";
VAL_ 1124 PSD_Ges_Geschwindigkeit_Tag_Ende 0 "kein Ende definiert" 1 "Montag" 2 "Dienstag" 3 "Mittwoch" 4 "Donnerstag" 5 "Freitag" 6 "Samstag" 7 "Sonntag";
VAL_ 1124 PSD_Sys_Quali_verfuegbar 0 "Qualitaetskriterien_nicht_verfuegbar" 1 "Qualitaetskriterien_verfuegbar";
VAL_ 1124 PSD_Sys_Zielfuehrung_geaendert 0 "Zielfuehrung_nicht_geaendert" 1 "Zielfuehrung_geaendert";
VAL_ 1124 PSD_Ges_Geschwindigkeit_Std_Anf 25 "kein Beginn für stundenweise Einschränkungen";
VAL_ 1124 PSD_Steigung_1_Attribute_kompl 0 "Steigungen_nicht_komplett" 1 "Steigungen_komplett";
VAL_ 1124 PSD_Sys_Geometrieguete_erweitert 0 "Init";
VAL_ 1124 PSD_Steigung_2_Segment_ID 0 "keine_Segment_Information_vorhanden" 1 "Fehler";
VAL_ 1124 PSD_Attribut_5_ID 0 "keine_Information";
VAL_ 1124 PSD_Ges_Geschwindigkeit_Std_Ende 25 "kein Ende für stundenweise Einschränkungen";
VAL_ 1124 PSD_Steigung_2_Steigung 126 "mehr_als_15_Prozent" 127 "Steigung_unbekannt";
VAL_ 1124 PSD_Ges_Ueberholverbot 0 "kein Überholverbot" 1 "alle Fahrzeuge" 2 "Überholverbot für PKW mit Gespann" 3 "Überholverbot für LKW, Busse, etc.";
VAL_ 1124 PSD_Ges_Wechselverkehrszeichen 0 "Kein Wechselverkehrszeichen" 1 "Wechselverkehrszeichen links" 2 "Wechselverkehrszeichen rechts" 3 "Wechselverkehrszeichen links und rechts" 4 "Wechselverkerhszeichen über der Fahrbahn";
VAL_ 1124 PSD_Steigung_2_Vorz 0 "Gefaelle" 1 "Steigung";
VAL_ 1124 PSD_Wechselverkehrszeichen_Typ 0 "kein_Wechselverkehrszeichen" 1 "LED_Wechselverkehrszeichen" 2 "nicht_LED_Wechselverkehrszeichen";
VAL_ 1124 PSD_Ges_Gesetzlich_Kategorie 0 "kein_legales_Verbot" 1 "innerorts" 2 "ausserorts" 3 "Autobahn";
VAL_ 1124 PSD_Attribute_Komplett_06 0 "Attribute_nicht_komplett" 1 "Attribute_komplett";
VAL_ 1124 PSD_Ges_Gesetzlich_Zusatz 0 "kein_Zusatz_zu_legalem_Gebot" 1 "Anhaenger_Klasse_1" 2 "Anhaenger_Klasse_2";
VAL_ 1124 PSD_Ges_Verkehrszeichen_Quelle 0 "VZA_kein_Onlinedienst" 1 "nur_VZA" 2 "nur_VZO" 3 "VZA_und_VZO";
VAL_ 1124 PSD_Steigung_2_Attribute_kompl 0 "Steigungen_nicht_komplett" 1 "Steigungen_komplett";
VAL_ 1124 PSD_Ges_Attribute_Komplett 0 "Attribute_nicht_komplett" 1 "Attribute_komplett";
VAL_ 591 RDR1_relevanter_Fehler 0 "kein_relevanter_Fehler" 1 "relevanter_Fehler";
VAL_ 591 RDR1_Blindheit_erkannt 0 "keine_Blindheit_erkannt" 1 "Blindheit_erkannt";
VAL_ 591 RDR1_relev_Nichtverfuegbarkeit 0 "verfuegbar" 1 "nicht_verfuegbar";
VAL_ 591 RDR1_Verkehrssinn 0 "init" 1 "Linksverkehr" 2 "Rechtsverkehr" 3 "Unbekannt";
VAL_ 591 RDR1_Objekte_02_Datenalter 1023 "Daten_aelter_als_Maximum";
VAL_ 591 RDR1_Obj_01_ax_v 255 "Init";
VAL_ 591 RDR1_Obj_01_ax_StdA 63 "Init";
VAL_ 591 RDR1_Obj_01_vx_StdA 127 "Init";
VAL_ 591 RDR1_Obj_01_dx_StdA 127 "Init";
VAL_ 591 RDR1_Obj_01_dy_StdA 127 "Init";
VAL_ 980 BH_Blinker_li 0 "nicht_betaetigt" 1 "Blinkerhebel_Richtung_links_betaetigt";
VAL_ 980 BH_Blinker_re 0 "nicht_betaetigt" 1 "Blinkerhebel_Richtung_rechts_betaetigt";
VAL_ 980 BH_Lichthupe 0 "nicht_betaetigt" 1 "Blinkerhebel in Richtung Lichthupe betaetigt";
VAL_ 980 BH_Fernlicht 0 "nicht_betaetigt" 1 "Blinkerhebel_in_Richtung_Fernlicht_betaetigt";
VAL_ 980 WH_Tipwischen 0 "nicht_betaetigt" 1 "betaetigt";
VAL_ 980 WH_Intervall 0 "aus" 1 "Wischerhebel in Stellung Intervall";
VAL_ 980 WH_WischerStufe1 0 "aus" 1 "Wischerhebel in Stufe Wischen 1";
VAL_ 980 WH_WischerStufe2 0 "aus" 1 "Wischerhebel in Stufe Wischen 2";
VAL_ 980 WH_Frontwaschen 0 "aus" 1 "Wischerhebel in Stellung Wisch Wasch vorne";
VAL_ 980 WH_Heckintervall 0 "nicht_betaetigt" 1 "Wischerhebel in Stellung Heckintervall";
VAL_ 980 WH_Heckwaschen 0 "nicht_betaetigt" 1 "Wischerhebel in Stellung Wisch Wasch hinten";
VAL_ 980 WH_Intervallstufen 0 "Init / Default" 9 "Intervallstufe 3" 1 "Intervallstufe 1" 13 "Intervallstufe 4" 5 "Intervallstufe 2" 15 "Fehler";
VAL_ 980 FAS_Taster 0 "nicht_betaetigt" 1 "betaetigt";
VAL_ 980 FAS_Taster_Fehler 0 "kein_Fehler" 1 "Fehler";
VAL_ 980 SMLS_Hupe 0 "nicht_betaetigt" 1 "Hupe_gedrueckt";
VAL_ 980 LRH_on_off 0 "LRH_aus__keine Anzeige" 1 "LRH_aus" 2 "LRH_ein" 3 "Fehler";
VAL_ 980 LSS_Tastencode 0 "Key_Released__No_Key" 4 "Up" 5 "Down" 7 "OK__ThumbWheel_Button";
VAL_ 980 LRH_aktiv 0 "inaktiv" 1 "aktiv";
VAL_ 980 SMLS_P_verriegelt 0 "Init" 1 "nicht_verriegelt" 2 "verriegelt" 3 "Fehler";
VAL_ 980 SMLS_P_verriegelt_plausibel 0 "unplausibel" 1 "plausibel";
VAL_ 980 WH_SRA 0 "SRA_Aus" 1 "SRA_Ein";
VAL_ 980 WH_Wischer_Fehler 0 "kein_Fehler" 1 "Fehler";
VAL_ 980 BH_Blinker_Fehler 0 "kein_Fehler" 1 "Fehler";
VAL_ 980 SMLS_PTT 0 "nicht_betaetigt" 1 "PTT_gedrueckt";
VAL_ 980 WH_Tipwischen_lang 0 "nicht_betaetigt" 1 "betaetigt";
VAL_ 1413 SI_Sammel_SG_Fehler 61 "Reserviert" 62 "Overflow" 63 "ungueltig";
VAL_ 1413 SI_P_Mode_gueltig 0 "dezentraler_Produktionsmode" 1 "zentraler_Produktionsmode";
VAL_ 1413 SI_Diagnose_Aktiv 0 "inaktiv" 1 "aktiv";
VAL_ 1413 SI_QRS_Mode 0 "QRS_Messmodus_nicht_aktiv" 1 "QRS_Messmodus_aktiv";
VAL_ 1413 SI_T_Mode 0 "Transportmodus_nicht_aktiv" 1 "Transportmodus_aktiv";
VAL_ 1413 SI_NWDF 0 "Ueberwachung_nicht_freigegeben" 1 "Ueberwachung_freigegeben";
VAL_ 1413 SI_NWDF_gueltig 0 "NWDF_wird_nicht_unterstuetzt" 1 "NWDF_wird_unterstuetzt";
VAL_ 1413 SI_Sammelfehler 0 "kein_Sammelfehler" 1 "Sammelfehler";
VAL_ 1413 GW_KD_Fehler 0 "kein_KD_Fehler" 1 "KD_Fehler";
VAL_ 1413 SI_T_Schutz 0 "Transportschutz_nicht_aktiv" 1 "Transportschutz_aktiv";
VAL_ 1413 SI_P_Mode 0 "inaktiv" 1 "aktiv";
VAL_ 1413 SI_BUS_01 0 "keine_Busruhe" 1 "Busruhe";
VAL_ 1413 SI_BUS_02 0 "keine_Busruhe" 1 "Busruhe";
VAL_ 1413 SI_BUS_03 0 "keine_Busruhe" 1 "Busruhe";
VAL_ 1413 SI_BUS_04 0 "keine_Busruhe" 1 "Busruhe";
VAL_ 1413 SI_BUS_05 0 "keine_Busruhe" 1 "Busruhe";
VAL_ 1413 SI_BUS_06 0 "keine_Busruhe" 1 "Busruhe";
VAL_ 1413 SI_BUS_07 0 "keine_Busruhe" 1 "Busruhe";
VAL_ 1413 SI_BUS_08 0 "keine_Busruhe" 1 "Busruhe";
VAL_ 1413 SI_BUS_09 0 "keine_Busruhe" 1 "Busruhe";
VAL_ 1413 SI_BUS_10 0 "keine_Busruhe" 1 "Busruhe";
VAL_ 1413 SI_BUS_11 0 "keine_Busruhe" 1 "Busruhe";
VAL_ 1413 SI_BUS_12 0 "keine_Busruhe" 1 "Busruhe";
VAL_ 1413 SI_BUS_13 0 "keine_Busruhe" 1 "Busruhe";
VAL_ 1413 SI_BUS_14 0 "keine_Busruhe" 1 "Busruhe";
VAL_ 1413 SI_BUS_15 0 "keine_Busruhe" 1 "Busruhe";
VAL_ 1413 SI_Bus_Identifikation 16 "CAN_Diagnose" 17 "CAN_Antrieb" 18 "CAN_Komfort" 19 "CAN_Infotainment" 20 "CAN_Fahrwerk" 21 "CAN_Extended" 22 "CAN_Hybrid" 23 "CAN_Lade" 24 "CAN_Kombi" 25 "CAN_Komfort_2" 26 "CAN_AFS" 97 "VLAN_FAS" 33 "CAN_FahrerAssistenzSysteme" 98 "VLAN_Infotainment" 34 "CAN_Migration" 99 "VLAN_Connect" 35 "CAN_Connect" 100 "VLAN_Komfort" 36 "CAN_AnzeigeBedienung" 101 "VLAN_Antrieb" 37 "CAN_ElectricalVehicle" 104 "VLAN_Gateway" 40 "CAN_Telematik" 105 "VLAN_Remote_FC" 41 "CAN_MFL" 48 "FlexRay_A" 49 "FlexRay_B" 102 "VLAN_Diagnose" 103 "VLAN_Internet" 106 "VLAN_Connect_2";
VAL_ 1413 SI_CAB_V10 32768 "CAB_16_Licht" 16384 "CAB_15_Laden" 128 "CAB_08_MIB" 0 "Init" 64 "CAB_07_Connect" 8192 "CAB_14_VLAN_Infotainment" 32 "CAB_06_Anzeige" 4096 "CAB_13_VLAN_Connect" 16 "CAB_05_Komfort" 8 "CAB_04_Fahrerassistenz" 1 "CAB_01_Antrieb" 2 "CAB_02_Hybrid_Laden" 4 "CAB_03_Fahrwerk" 256 "CAB_09_Standheizung" 1024 "CAB_11_VLAN_Fahrerassistenz";
VAL_ 2589283396 TSK_vMax_EfficiencyMode1 254 "kein_Limit_aktiv" 255 "Init";
VAL_ 2589283396 TSK_vMax_EfficiencyMode2 254 "kein_Limit_aktiv" 255 "Init";
VAL_ 2589283396 TSK_vMax_StandardMode 254 "kein_Limit_aktiv" 255 "Init";
